VERSION ""

NS_ :

BS_:

BU_: WPC2 PSB SHVU_RR FCS vHS_B2 EMCU SLB GW_APSU GW_DLBCU RCM ARS CGW_CCU vDummy_HS_B GW_RLPSU ATS RLHV SGU PFSU GW_RRPSU ALBCU DSAU SWRC SHVU_FR RCS GW_DPSU BLTN_CAM SCM OHCL RWPC RRHV WPC HOD ASAU

BO_ 894 PDCex_01_200ms: 8 CGW_CCU
 SG_ PDCex_Crc1Val : 0|8@1+ (1,0) [0|0] "0" Vector__XXX
 SG_ PDCex_4thRLSBRMatSw : 10|1@1+ (1,0) [0|0] ""  ARS,FCS,WPC2
 SG_ PDCex_4thRRSBRMatSw : 11|1@1+ (1,0) [0|0] ""  ARS,FCS,WPC2
 SG_ PDCex_AlvCnt1Val : 12|4@1+ (1,0) [0|0] "0" Vector__XXX
 SG_ PDCex_4thRLSeatBeltSW : 16|1@1+ (1,0) [0|0] ""  ARS,FCS,WPC2
 SG_ PDCex_4thRCSeatBeltSW : 17|1@1+ (1,0) [0|0] ""  ARS,FCS,WPC2
 SG_ PDCex_4thRRSeatBeltSW : 18|1@1+ (1,0) [0|0] ""  ARS,FCS,WPC2
 SG_ PDCex_WirelessSBRWrngSta : 19|2@1+ (1,0) [0|0] "" Vector__XXX
 SG_ PDCex_FrtSunroofOpnSta : 21|2@1+ (1,0) [0|0] "" Vector__XXX
 SG_ PDCex_RrSunroofOpnSta : 23|2@1+ (1,0) [0|0] "" Vector__XXX
 SG_ PDCex_FuelDrOpenSta : 25|1@1+ (1,0) [0|0] ""  ARS,FCS,WPC2
 SG_ PDCex_TlgtUnLkSta : 26|2@1+ (1,0) [0|0] "" Vector__XXX
 SG_ PDCex_PSDPwrModeOffSwSta : 28|2@1+ (1,0) [0|0] ""  ARS,FCS,WPC2
 SG_ PDCex_StrBoxLidSta : 30|2@1+ (1,0) [0|0] "" Vector__XXX
 SG_ PDCex_StrBoxOutReleaseSwSta : 32|2@1+ (1,0) [0|0] "" Vector__XXX
 SG_ PDCex_DoorLock_LkOutSta : 34|2@1+ (1,0) [0|0] "" Vector__XXX
 SG_ SeatBeltSwSta_4thLft : 40|2@1+ (1,0) [0|0] "" Vector__XXX
 SG_ SeatBeltSwSta_4thCtr : 42|2@1+ (1,0) [0|0] "" Vector__XXX
 SG_ SeatBeltSwSta_4thRt : 44|2@1+ (1,0) [0|0] "" Vector__XXX
 SG_ PDCex_OptTyp : 8|2@1+ (1,0) [0|0] "" Vector__XXX

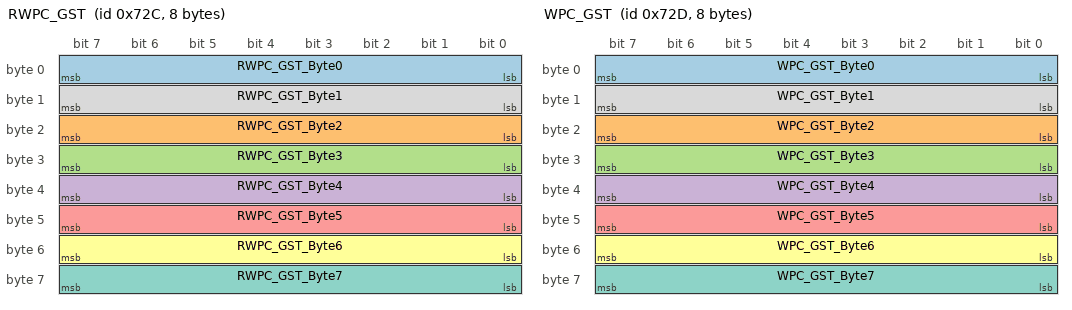
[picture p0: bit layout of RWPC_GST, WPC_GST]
BO_ 1836 RWPC_GST: 8 RWPC
 SG_ RWPC_GST_Byte0 : 0|8@1+ (1,0) [0|0] ""  CGW_CCU
 SG_ RWPC_GST_Byte2 : 16|8@1+ (1,0) [0|0] ""  CGW_CCU
 SG_ RWPC_GST_Byte3 : 24|8@1+ (1,0) [0|0] ""  CGW_CCU
 SG_ RWPC_GST_Byte4 : 32|8@1+ (1,0) [0|0] ""  CGW_CCU
 SG_ RWPC_GST_Byte5 : 40|8@1+ (1,0) [0|0] ""  CGW_CCU
 SG_ RWPC_GST_Byte6 : 48|8@1+ (1,0) [0|0] ""  CGW_CCU
 SG_ RWPC_GST_Byte7 : 56|8@1+ (1,0) [0|0] ""  CGW_CCU
 SG_ RWPC_GST_Byte1 : 8|8@1+ (1,0) [0|0] ""  CGW_CCU

BO_ 1837 WPC_GST: 8 WPC
 SG_ WPC_GST_Byte0 : 0|8@1+ (1,0) [0|0] ""  CGW_CCU
 SG_ WPC_GST_Byte2 : 16|8@1+ (1,0) [0|0] ""  CGW_CCU
 SG_ WPC_GST_Byte3 : 24|8@1+ (1,0) [0|0] ""  CGW_CCU
 SG_ WPC_GST_Byte4 : 32|8@1+ (1,0) [0|0] ""  CGW_CCU
 SG_ WPC_GST_Byte5 : 40|8@1+ (1,0) [0|0] ""  CGW_CCU
 SG_ WPC_GST_Byte6 : 48|8@1+ (1,0) [0|0] ""  CGW_CCU
 SG_ WPC_GST_Byte7 : 56|8@1+ (1,0) [0|0] ""  CGW_CCU
 SG_ WPC_GST_Byte1 : 8|8@1+ (1,0) [0|0] ""  CGW_CCU

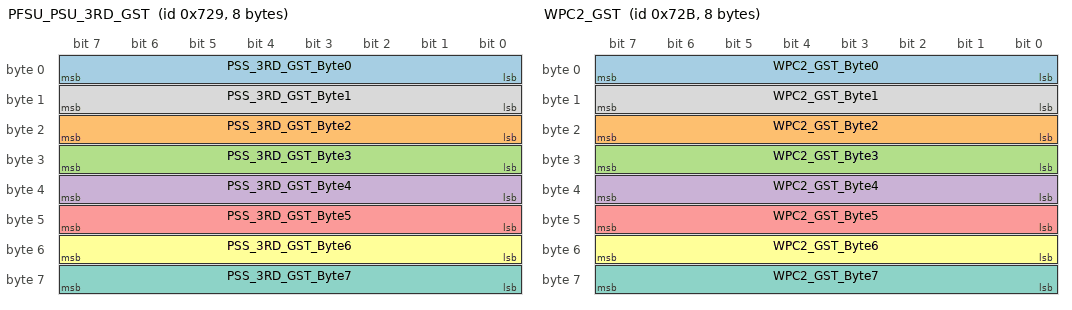
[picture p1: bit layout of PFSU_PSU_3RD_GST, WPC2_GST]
BO_ 1833 PFSU_PSU_3RD_GST: 8 PFSU
 SG_ PSS_3RD_GST_Byte0 : 0|8@1+ (1,0) [0|0] ""  CGW_CCU
 SG_ PSS_3RD_GST_Byte2 : 16|8@1+ (1,0) [0|0] ""  CGW_CCU
 SG_ PSS_3RD_GST_Byte3 : 24|8@1+ (1,0) [0|0] ""  CGW_CCU
 SG_ PSS_3RD_GST_Byte4 : 32|8@1+ (1,0) [0|0] ""  CGW_CCU
 SG_ PSS_3RD_GST_Byte5 : 40|8@1+ (1,0) [0|0] ""  CGW_CCU
 SG_ PSS_3RD_GST_Byte6 : 48|8@1+ (1,0) [0|0] ""  CGW_CCU
 SG_ PSS_3RD_GST_Byte7 : 56|8@1+ (1,0) [0|0] ""  CGW_CCU
 SG_ PSS_3RD_GST_Byte1 : 8|8@1+ (1,0) [0|0] ""  CGW_CCU

BO_ 1835 WPC2_GST: 8 WPC2
 SG_ WPC2_GST_Byte0 : 0|8@1+ (1,0) [0|0] ""  CGW_CCU
 SG_ WPC2_GST_Byte2 : 16|8@1+ (1,0) [0|0] ""  CGW_CCU
 SG_ WPC2_GST_Byte3 : 24|8@1+ (1,0) [0|0] ""  CGW_CCU
 SG_ WPC2_GST_Byte4 : 32|8@1+ (1,0) [0|0] ""  CGW_CCU
 SG_ WPC2_GST_Byte5 : 40|8@1+ (1,0) [0|0] ""  CGW_CCU
 SG_ WPC2_GST_Byte6 : 48|8@1+ (1,0) [0|0] ""  CGW_CCU
 SG_ WPC2_GST_Byte7 : 56|8@1+ (1,0) [0|0] ""  CGW_CCU
 SG_ WPC2_GST_Byte1 : 8|8@1+ (1,0) [0|0] ""  CGW_CCU

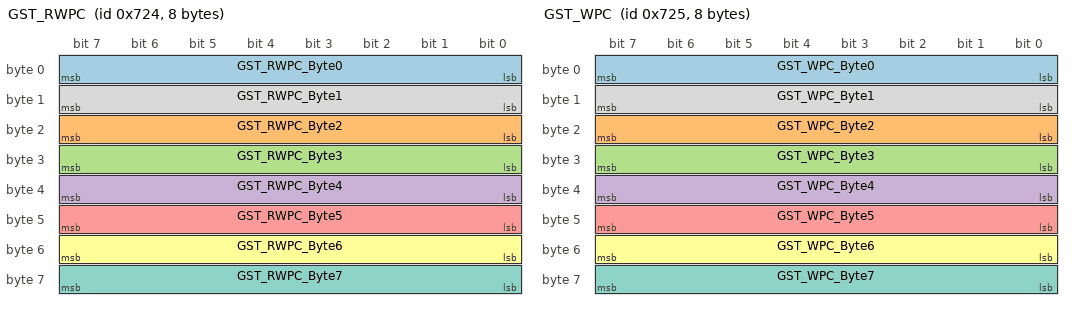
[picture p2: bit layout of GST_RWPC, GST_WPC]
BO_ 1828 GST_RWPC: 8 CGW_CCU
 SG_ GST_RWPC_Byte0 : 0|8@1+ (1,0) [0|0] ""  RWPC
 SG_ GST_RWPC_Byte2 : 16|8@1+ (1,0) [0|0] ""  RWPC
 SG_ GST_RWPC_Byte3 : 24|8@1+ (1,0) [0|0] ""  RWPC
 SG_ GST_RWPC_Byte4 : 32|8@1+ (1,0) [0|0] ""  RWPC
 SG_ GST_RWPC_Byte5 : 40|8@1+ (1,0) [0|0] ""  RWPC
 SG_ GST_RWPC_Byte6 : 48|8@1+ (1,0) [0|0] ""  RWPC
 SG_ GST_RWPC_Byte7 : 56|8@1+ (1,0) [0|0] ""  RWPC
 SG_ GST_RWPC_Byte1 : 8|8@1+ (1,0) [0|0] ""  RWPC

BO_ 1829 GST_WPC: 8 CGW_CCU
 SG_ GST_WPC_Byte0 : 0|8@1+ (1,0) [0|0] ""  WPC
 SG_ GST_WPC_Byte2 : 16|8@1+ (1,0) [0|0] ""  WPC
 SG_ GST_WPC_Byte3 : 24|8@1+ (1,0) [0|0] ""  WPC
 SG_ GST_WPC_Byte4 : 32|8@1+ (1,0) [0|0] ""  WPC
 SG_ GST_WPC_Byte5 : 40|8@1+ (1,0) [0|0] ""  WPC
 SG_ GST_WPC_Byte6 : 48|8@1+ (1,0) [0|0] ""  WPC
 SG_ GST_WPC_Byte7 : 56|8@1+ (1,0) [0|0] ""  WPC
 SG_ GST_WPC_Byte1 : 8|8@1+ (1,0) [0|0] ""  WPC

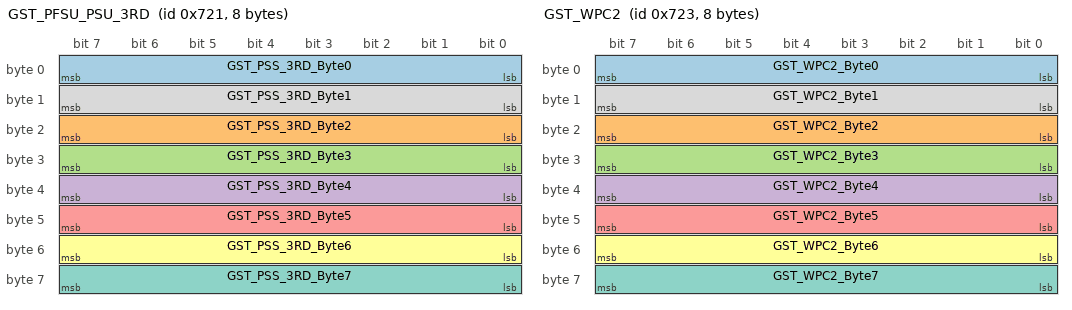
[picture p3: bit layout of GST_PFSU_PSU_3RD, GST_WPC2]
BO_ 1825 GST_PFSU_PSU_3RD: 8 CGW_CCU
 SG_ GST_PSS_3RD_Byte0 : 0|8@1+ (1,0) [0|0] ""  PFSU
 SG_ GST_PSS_3RD_Byte2 : 16|8@1+ (1,0) [0|0] ""  PFSU
 SG_ GST_PSS_3RD_Byte3 : 24|8@1+ (1,0) [0|0] ""  PFSU
 SG_ GST_PSS_3RD_Byte4 : 32|8@1+ (1,0) [0|0] ""  PFSU
 SG_ GST_PSS_3RD_Byte5 : 40|8@1+ (1,0) [0|0] ""  PFSU
 SG_ GST_PSS_3RD_Byte6 : 48|8@1+ (1,0) [0|0] ""  PFSU
 SG_ GST_PSS_3RD_Byte7 : 56|8@1+ (1,0) [0|0] ""  PFSU
 SG_ GST_PSS_3RD_Byte1 : 8|8@1+ (1,0) [0|0] ""  PFSU

BO_ 1827 GST_WPC2: 8 CGW_CCU
 SG_ GST_WPC2_Byte0 : 0|8@1+ (1,0) [0|0] ""  WPC2
 SG_ GST_WPC2_Byte2 : 16|8@1+ (1,0) [0|0] ""  WPC2
 SG_ GST_WPC2_Byte3 : 24|8@1+ (1,0) [0|0] ""  WPC2
 SG_ GST_WPC2_Byte4 : 32|8@1+ (1,0) [0|0] ""  WPC2
 SG_ GST_WPC2_Byte5 : 40|8@1+ (1,0) [0|0] ""  WPC2
 SG_ GST_WPC2_Byte6 : 48|8@1+ (1,0) [0|0] ""  WPC2
 SG_ GST_WPC2_Byte7 : 56|8@1+ (1,0) [0|0] ""  WPC2
 SG_ GST_WPC2_Byte1 : 8|8@1+ (1,0) [0|0] ""  WPC2

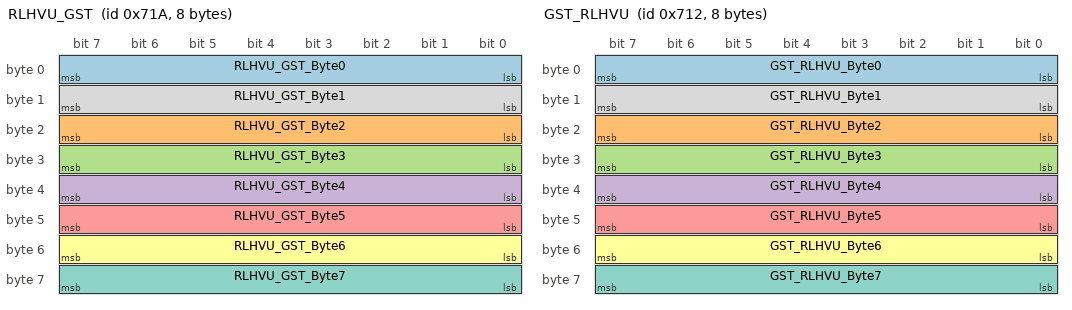
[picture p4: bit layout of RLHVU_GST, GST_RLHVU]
BO_ 1818 RLHVU_GST: 8 RLHV
 SG_ RLHVU_GST_Byte0 : 0|8@1+ (1,0) [0|0] ""  CGW_CCU
 SG_ RLHVU_GST_Byte2 : 16|8@1+ (1,0) [0|0] ""  CGW_CCU
 SG_ RLHVU_GST_Byte3 : 24|8@1+ (1,0) [0|0] ""  CGW_CCU
 SG_ RLHVU_GST_Byte4 : 32|8@1+ (1,0) [0|0] ""  CGW_CCU
 SG_ RLHVU_GST_Byte5 : 40|8@1+ (1,0) [0|0] ""  CGW_CCU
 SG_ RLHVU_GST_Byte6 : 48|8@1+ (1,0) [0|0] ""  CGW_CCU
 SG_ RLHVU_GST_Byte7 : 56|8@1+ (1,0) [0|0] ""  CGW_CCU
 SG_ RLHVU_GST_Byte1 : 8|8@1+ (1,0) [0|0] ""  CGW_CCU

BO_ 858 SBCM_AST_02_200ms: 8 CGW_CCU
 SG_ SBCM_AST_Crc2Val : 0|8@1+ (1,0) [0|0] "" Vector__XXX
 SG_ AST_CrashUnlockCmd : 10|1@1+ (1,0) [0|0] ""  BLTN_CAM
 SG_ SBCM_AST_AlvCnt2Val : 12|4@1+ (1,0) [0|0] "" Vector__XXX
 SG_ DoorLock_CtrlDrLkSwSta_SBCM : 16|2@1+ (1,0) [0|0] "" Vector__XXX
 SG_ DoorLock_CtrlDrUnLkSwSta_SBCM : 18|2@1+ (1,0) [0|0] "" Vector__XXX
 SG_ Warn_AsstDrSwSta_SBCM : 20|2@1+ (1,0) [0|0] ""  ALBCU,ATS,BLTN_CAM,GW_APSU,GW_RLPSU,GW_RRPSU,PSB,RWPC,WPC,WPC2
 SG_ DoorLock_AsstDrUnLkSta_SBCM : 22|2@1+ (1,0) [0|0] ""  ATS
 SG_ AST_SEAWarn_RH : 24|2@1+ (1,0) [0|0] "" Vector__XXX
 SG_ AST_SEAWarn_LH : 26|2@1+ (1,0) [0|0] "" Vector__XXX
 SG_ AST_SEWWarn_LH : 28|2@1+ (1,0) [0|0] "" Vector__XXX
 SG_ AST_SEWWarn_RH : 30|2@1+ (1,0) [0|0] "" Vector__XXX
 SG_ AST_MRActivationAlarm : 32|2@1+ (1,0) [0|0] "" Vector__XXX
 SG_ AST_ReleaseWarn : 34|2@1+ (1,0) [0|0] "" Vector__XXX
 SG_ USM_AstGhostDoorSta : 36|2@1+ (1,0) [0|0] "" Vector__XXX
 SG_ AST_SWFailAlarm : 38|2@1+ (1,0) [0|0] "" Vector__XXX
 SG_ DoorLock_PDSLkSwSta_AST : 40|2@1+ (1,0) [0|0] "" Vector__XXX
 SG_ PDS_TypeOption_AST : 42|2@1+ (1,0) [0|0] "" Vector__XXX
 SG_ AFCU_AutoWashModeSta_SBCM_AST : 56|3@1+ (1,0) [0|0] "" Vector__XXX
 SG_ CDM_AutoWashModeSta_SBCM_AST : 59|3@1+ (1,0) [0|0] "" Vector__XXX
 SG_ ASTDoorPushAlarm : 8|2@1+ (1,0) [0|0] "" Vector__XXX

BO_ 863 Ast_SHVU_03_200ms: 8 SHVU_FR
 SG_ Ast_SHVU_DTCdisplay : 0|8@1+ (1,0) [0|0] "" Vector__XXX
 SG_ Ast_SHVU_DiagMode : 8|2@1+ (1,0) [0|0] ""  vHS_B2

BO_ 862 SBCM_RL_01_200ms: 8 CGW_CCU
 SG_ SBCM_RL_Crc1Val : 0|8@1+ (1,0) [0|0] "" Vector__XXX
 SG_ RL_CrashUnlockCmd : 10|1@1+ (1,0) [0|0] ""  BLTN_CAM
 SG_ SBCM_RL_AlvCnt1Val : 12|4@1+ (1,0) [0|0] "" Vector__XXX
 SG_ Warn_RrLftDrSwSta_SBCM : 16|2@1+ (1,0) [0|0] ""  ATS,BLTN_CAM,GW_APSU,GW_RLPSU,GW_RRPSU,RWPC,WPC,WPC2
 SG_ DoorLock_RrLftDrUnLkSta_SBCM : 18|2@1+ (1,0) [0|0] ""  ATS
 SG_ RL_SEAActivated : 20|2@1+ (1,0) [0|0] "" Vector__XXX
 SG_ RL_SEAWarn : 22|2@1+ (1,0) [0|0] "" Vector__XXX
 SG_ RL_SEWWarn : 24|2@1+ (1,0) [0|0] "" Vector__XXX
 SG_ RL_ReleaseWarn : 26|2@1+ (1,0) [0|0] "" Vector__XXX
 SG_ RL_SWFailAlarm : 28|2@1+ (1,0) [0|0] "" Vector__XXX
 SG_ RL_ChildLock_ActnFlSta : 30|2@1+ (1,0) [0|0] "" Vector__XXX
 SG_ RL_MRActivationAlarm : 32|2@1+ (1,0) [0|0] "" Vector__XXX
 SG_ RL_ChildLock_Status : 34|2@1+ (1,0) [0|0] "" Vector__XXX
 SG_ USM_RLGhostDoorSta : 36|2@1+ (1,0) [0|0] "" Vector__XXX
 SG_ DoorLock_PDSLkSwSta_RL : 40|2@1+ (1,0) [0|0] "" Vector__XXX
 SG_ PDS_TypeOption_RL : 42|2@1+ (1,0) [0|0] "" Vector__XXX
 SG_ RLDoorPushAlarm : 8|2@1+ (1,0) [0|0] "" Vector__XXX

BO_ 1810 GST_RLHVU: 8 CGW_CCU
 SG_ GST_RLHVU_Byte0 : 0|8@1+ (1,0) [0|0] ""  RLHV
 SG_ GST_RLHVU_Byte2 : 16|8@1+ (1,0) [0|0] ""  RLHV
 SG_ GST_RLHVU_Byte3 : 24|8@1+ (1,0) [0|0] ""  RLHV
 SG_ GST_RLHVU_Byte4 : 32|8@1+ (1,0) [0|0] ""  RLHV
 SG_ GST_RLHVU_Byte5 : 40|8@1+ (1,0) [0|0] ""  RLHV
 SG_ GST_RLHVU_Byte6 : 48|8@1+ (1,0) [0|0] ""  RLHV
 SG_ GST_RLHVU_Byte7 : 56|8@1+ (1,0) [0|0] ""  RLHV
 SG_ GST_RLHVU_Byte1 : 8|8@1+ (1,0) [0|0] ""  RLHV

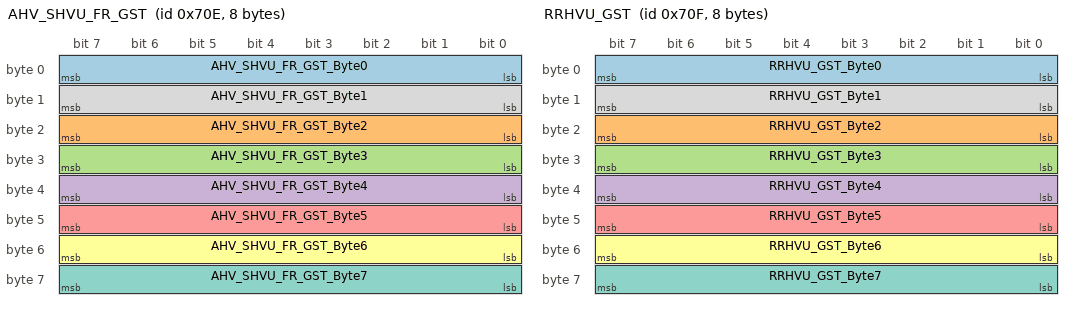
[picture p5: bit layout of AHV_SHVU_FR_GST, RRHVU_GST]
BO_ 1806 AHV_SHVU_FR_GST: 8 SHVU_FR
 SG_ AHV_SHVU_FR_GST_Byte0 : 0|8@1+ (1,0) [0|0] ""  CGW_CCU
 SG_ AHV_SHVU_FR_GST_Byte2 : 16|8@1+ (1,0) [0|0] ""  CGW_CCU
 SG_ AHV_SHVU_FR_GST_Byte3 : 24|8@1+ (1,0) [0|0] ""  CGW_CCU
 SG_ AHV_SHVU_FR_GST_Byte4 : 32|8@1+ (1,0) [0|0] ""  CGW_CCU
 SG_ AHV_SHVU_FR_GST_Byte5 : 40|8@1+ (1,0) [0|0] ""  CGW_CCU
 SG_ AHV_SHVU_FR_GST_Byte6 : 48|8@1+ (1,0) [0|0] ""  CGW_CCU
 SG_ AHV_SHVU_FR_GST_Byte7 : 56|8@1+ (1,0) [0|0] ""  CGW_CCU
 SG_ AHV_SHVU_FR_GST_Byte1 : 8|8@1+ (1,0) [0|0] ""  CGW_CCU

BO_ 1807 RRHVU_GST: 8 SHVU_RR
 SG_ RRHVU_GST_Byte0 : 0|8@1+ (1,0) [0|0] ""  CGW_CCU
 SG_ RRHVU_GST_Byte2 : 16|8@1+ (1,0) [0|0] ""  CGW_CCU
 SG_ RRHVU_GST_Byte3 : 24|8@1+ (1,0) [0|0] ""  CGW_CCU
 SG_ RRHVU_GST_Byte4 : 32|8@1+ (1,0) [0|0] ""  CGW_CCU
 SG_ RRHVU_GST_Byte5 : 40|8@1+ (1,0) [0|0] ""  CGW_CCU
 SG_ RRHVU_GST_Byte6 : 48|8@1+ (1,0) [0|0] ""  CGW_CCU
 SG_ RRHVU_GST_Byte7 : 56|8@1+ (1,0) [0|0] ""  CGW_CCU
 SG_ RRHVU_GST_Byte1 : 8|8@1+ (1,0) [0|0] ""  CGW_CCU

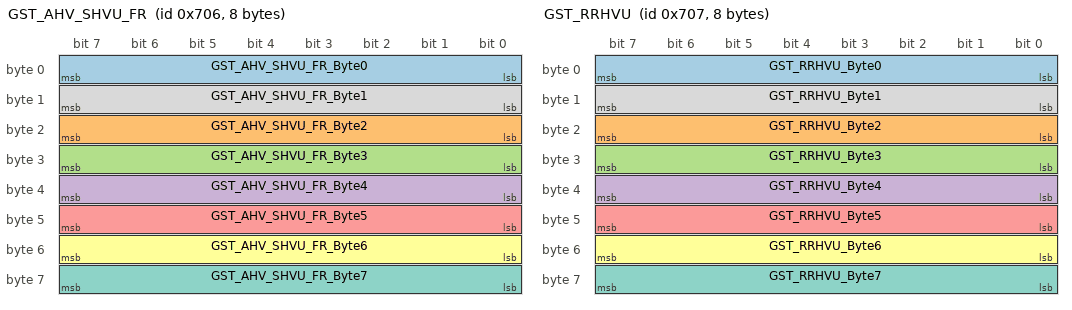
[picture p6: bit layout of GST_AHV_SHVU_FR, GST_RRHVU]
BO_ 1798 GST_AHV_SHVU_FR: 8 CGW_CCU
 SG_ GST_AHV_SHVU_FR_Byte0 : 0|8@1+ (1,0) [0|0] ""  SHVU_FR
 SG_ GST_AHV_SHVU_FR_Byte2 : 16|8@1+ (1,0) [0|0] ""  SHVU_FR
 SG_ GST_AHV_SHVU_FR_Byte3 : 24|8@1+ (1,0) [0|0] ""  SHVU_FR
 SG_ GST_AHV_SHVU_FR_Byte4 : 32|8@1+ (1,0) [0|0] ""  SHVU_FR
 SG_ GST_AHV_SHVU_FR_Byte5 : 40|8@1+ (1,0) [0|0] ""  SHVU_FR
 SG_ GST_AHV_SHVU_FR_Byte6 : 48|8@1+ (1,0) [0|0] ""  SHVU_FR
 SG_ GST_AHV_SHVU_FR_Byte7 : 56|8@1+ (1,0) [0|0] ""  SHVU_FR
 SG_ GST_AHV_SHVU_FR_Byte1 : 8|8@1+ (1,0) [0|0] ""  SHVU_FR

BO_ 1799 GST_RRHVU: 8 CGW_CCU
 SG_ GST_RRHVU_Byte0 : 0|8@1+ (1,0) [0|0] ""  RRHV,SHVU_RR
 SG_ GST_RRHVU_Byte2 : 16|8@1+ (1,0) [0|0] ""  RRHV,SHVU_RR
 SG_ GST_RRHVU_Byte3 : 24|8@1+ (1,0) [0|0] ""  RRHV,SHVU_RR
 SG_ GST_RRHVU_Byte4 : 32|8@1+ (1,0) [0|0] ""  RRHV,SHVU_RR
 SG_ GST_RRHVU_Byte5 : 40|8@1+ (1,0) [0|0] ""  RRHV,SHVU_RR
 SG_ GST_RRHVU_Byte6 : 48|8@1+ (1,0) [0|0] ""  RRHV,SHVU_RR
 SG_ GST_RRHVU_Byte7 : 56|8@1+ (1,0) [0|0] ""  RRHV,SHVU_RR
 SG_ GST_RRHVU_Byte1 : 8|8@1+ (1,0) [0|0] ""  RRHV,SHVU_RR

BO_ 847 Drv_SHVU_03_200ms: 8 SHVU_FR
 SG_ Drv_SHVU_DTCdisplay : 0|8@1+ (1,0) [0|0] "" Vector__XXX
 SG_ Drv_SHVU_DiagMode : 8|2@1+ (1,0) [0|0] "" Vector__XXX

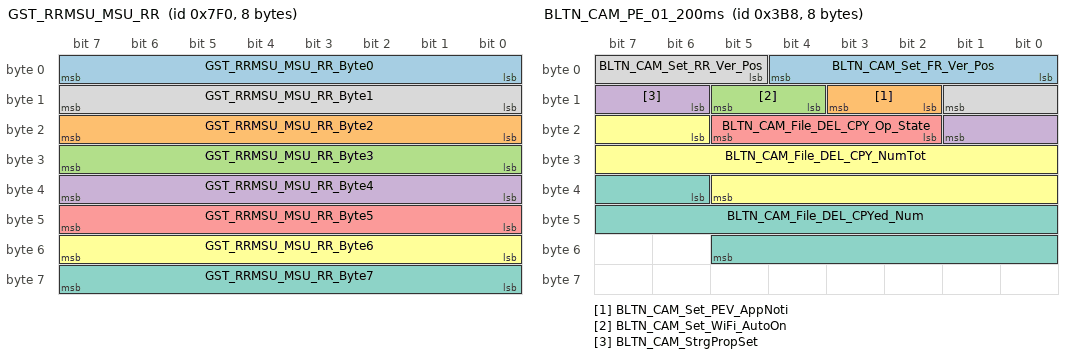
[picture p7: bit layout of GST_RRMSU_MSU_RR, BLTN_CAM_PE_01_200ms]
BO_ 2032 GST_RRMSU_MSU_RR: 8 CGW_CCU
 SG_ GST_RRMSU_MSU_RR_Byte0 : 0|8@1+ (1,0) [0|0] ""  GW_RRPSU
 SG_ GST_RRMSU_MSU_RR_Byte2 : 16|8@1+ (1,0) [0|0] ""  GW_RRPSU
 SG_ GST_RRMSU_MSU_RR_Byte3 : 24|8@1+ (1,0) [0|0] ""  GW_RRPSU
 SG_ GST_RRMSU_MSU_RR_Byte4 : 32|8@1+ (1,0) [0|0] ""  GW_RRPSU
 SG_ GST_RRMSU_MSU_RR_Byte5 : 40|8@1+ (1,0) [0|0] ""  GW_RRPSU
 SG_ GST_RRMSU_MSU_RR_Byte6 : 48|8@1+ (1,0) [0|0] ""  GW_RRPSU
 SG_ GST_RRMSU_MSU_RR_Byte7 : 56|8@1+ (1,0) [0|0] ""  GW_RRPSU
 SG_ GST_RRMSU_MSU_RR_Byte1 : 8|8@1+ (1,0) [0|0] ""  GW_RRPSU

BO_ 952 BLTN_CAM_PE_01_200ms: 8 BLTN_CAM
 SG_ BLTN_CAM_Set_FR_Ver_Pos : 0|5@1+ (1,0) [0|0] ""  CGW_CCU
 SG_ BLTN_CAM_Set_PEV_AppNoti : 10|2@1+ (1,0) [0|0] ""  CGW_CCU
 SG_ BLTN_CAM_Set_WiFi_AutoOn : 12|2@1+ (1,0) [0|0] ""  CGW_CCU
 SG_ BLTN_CAM_StrgPropSet : 14|4@1+ (1,0) [0|0] ""  CGW_CCU
 SG_ BLTN_CAM_File_DEL_CPY_Op_State : 18|4@1+ (1,0) [0|0] ""  CGW_CCU
 SG_ BLTN_CAM_File_DEL_CPY_NumTot : 22|16@1+ (1,0) [0|0] ""  CGW_CCU
 SG_ BLTN_CAM_File_DEL_CPYed_Num : 38|16@1+ (1,0) [0|0] ""  CGW_CCU
 SG_ BLTN_CAM_Set_RR_Ver_Pos : 5|5@1+ (1,0) [0|0] ""  CGW_CCU

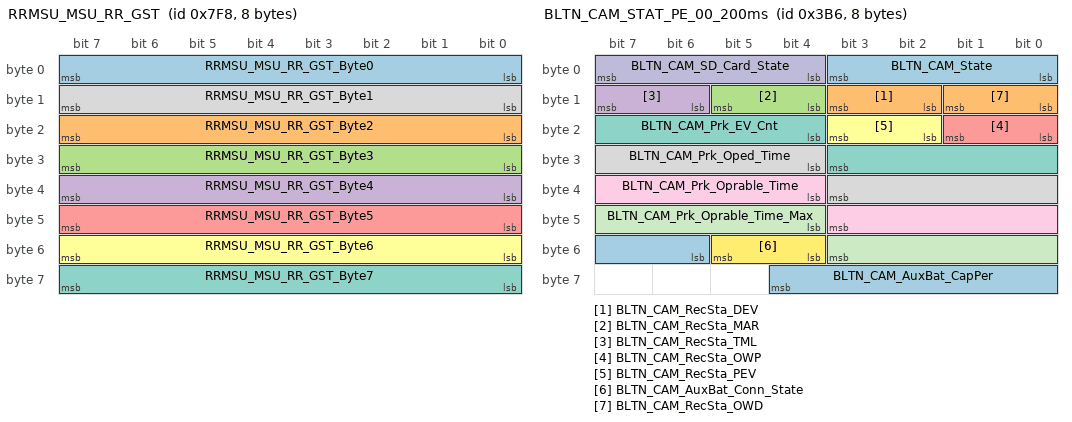
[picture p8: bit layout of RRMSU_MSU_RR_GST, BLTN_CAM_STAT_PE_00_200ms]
BO_ 2040 RRMSU_MSU_RR_GST: 8 GW_RRPSU
 SG_ RRMSU_MSU_RR_GST_Byte0 : 0|8@1+ (1,0) [0|0] ""  CGW_CCU
 SG_ RRMSU_MSU_RR_GST_Byte2 : 16|8@1+ (1,0) [0|0] ""  CGW_CCU
 SG_ RRMSU_MSU_RR_GST_Byte3 : 24|8@1+ (1,0) [0|0] ""  CGW_CCU
 SG_ RRMSU_MSU_RR_GST_Byte4 : 32|8@1+ (1,0) [0|0] ""  CGW_CCU
 SG_ RRMSU_MSU_RR_GST_Byte5 : 40|8@1+ (1,0) [0|0] ""  CGW_CCU
 SG_ RRMSU_MSU_RR_GST_Byte6 : 48|8@1+ (1,0) [0|0] ""  CGW_CCU
 SG_ RRMSU_MSU_RR_GST_Byte7 : 56|8@1+ (1,0) [0|0] ""  CGW_CCU
 SG_ RRMSU_MSU_RR_GST_Byte1 : 8|8@1+ (1,0) [0|0] ""  CGW_CCU

BO_ 950 BLTN_CAM_STAT_PE_00_200ms: 8 BLTN_CAM
 SG_ BLTN_CAM_State : 0|4@1+ (1,0) [0|0] ""  CGW_CCU
 SG_ BLTN_CAM_RecSta_DEV : 10|2@1+ (1,0) [0|0] ""  CGW_CCU
 SG_ BLTN_CAM_RecSta_MAR : 12|2@1+ (1,0) [0|0] ""  CGW_CCU
 SG_ BLTN_CAM_RecSta_TML : 14|2@1+ (1,0) [0|0] ""  CGW_CCU
 SG_ BLTN_CAM_RecSta_OWP : 16|2@1+ (1,0) [0|0] ""  CGW_CCU
 SG_ BLTN_CAM_RecSta_PEV : 18|2@1+ (1,0) [0|0] ""  CGW_CCU
 SG_ BLTN_CAM_Prk_EV_Cnt : 20|8@1+ (1,0) [0|0] ""  CGW_CCU
 SG_ BLTN_CAM_Prk_Oped_Time : 28|8@1+ (1,0) [0|0] "Hour"  CGW_CCU
 SG_ BLTN_CAM_Prk_Oprable_Time : 36|8@1+ (1,0) [0|0] "Hour"  CGW_CCU
 SG_ BLTN_CAM_SD_Card_State : 4|4@1+ (1,0) [0|0] ""  CGW_CCU
 SG_ BLTN_CAM_Prk_Oprable_Time_Max : 44|8@1+ (1,0) [0|0] "Hour"  CGW_CCU
 SG_ BLTN_CAM_AuxBat_Conn_State : 52|2@1+ (1,0) [0|0] ""  CGW_CCU
 SG_ BLTN_CAM_AuxBat_CapPer : 54|7@1+ (1,0) [0|0] "%"  CGW_CCU
 SG_ BLTN_CAM_RecSta_OWD : 8|2@1+ (1,0) [0|0] ""  CGW_CCU

BO_ 951 BLTN_CAM_PE_00_200ms: 8 BLTN_CAM
 SG_ BLTN_CAM_RecSet_OWD : 0|2@1+ (1,0) [0|0] ""  CGW_CCU
 SG_ BLTN_CAM_Set_Tim_Stm : 10|2@1+ (1,0) [0|0] ""  CGW_CCU
 SG_ BLTN_CAM_Set_Spd_Stm : 12|2@1+ (1,0) [0|0] ""  CGW_CCU
 SG_ BLTN_CAM_Set_Locatn_Stm : 14|2@1+ (1,0) [0|0] ""  CGW_CCU
 SG_ BLTN_CAM_Set_TrnSig_Stm : 16|2@1+ (1,0) [0|0] ""  CGW_CCU
 SG_ BLTN_CAM_Set_AclBrk_Stm : 18|2@1+ (1,0) [0|0] ""  CGW_CCU
 SG_ BLTN_CAM_RecSet_DEV : 2|2@1+ (1,0) [0|0] ""  CGW_CCU
 SG_ BLTN_CAM_Set_GearPos_Stm : 20|2@1+ (1,0) [0|0] ""  CGW_CCU
 SG_ BLTN_CAM_Set_EVSen_Stm : 22|2@1+ (1,0) [0|0] ""  CGW_CCU
 SG_ BLTN_CAM_Set_StrAngl_Stm : 24|2@1+ (1,0) [0|0] ""  CGW_CCU
 SG_ BLTN_CAM_Set_EV_RecMaxTime : 26|2@1+ (1,0) [0|0] ""  CGW_CCU
 SG_ BLTN_CAM_Set_PrkTime : 30|8@1+ (1,0) [0|0] "Hour"  CGW_CCU
 SG_ BLTN_CAM_Set_EV_BfrTime : 38|5@1+ (1,0) [0|0] ""  CGW_CCU
 SG_ BLTN_CAM_RecSet_OWP : 4|2@1+ (1,0) [0|0] ""  CGW_CCU
 SG_ BLTN_CAM_Set_EV_AftTime : 43|5@1+ (1,0) [0|0] ""  CGW_CCU
 SG_ BLTN_CAM_Set_Drv_TML_Int : 48|4@1+ (1,0) [0|0] ""  CGW_CCU
 SG_ BLTN_CAM_SenSet_DEV : 52|4@1+ (1,0) [0|0] ""  CGW_CCU
 SG_ BLTN_CAM_SenSet_PEV : 56|4@1+ (1,0) [0|0] ""  CGW_CCU
 SG_ BLTN_CAM_RecSet_PEV : 6|2@1+ (1,0) [0|0] ""  CGW_CCU
 SG_ BLTN_CAM_AudRec_Set : 8|2@1+ (1,0) [0|0] ""  CGW_CCU

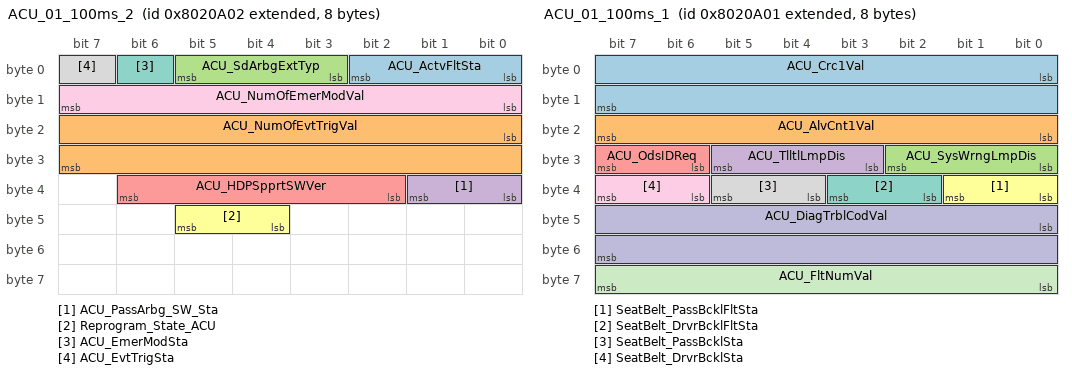
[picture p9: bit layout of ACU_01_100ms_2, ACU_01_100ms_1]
BO_ 2281835010 ACU_01_100ms_2: 8 CGW_CCU
 SG_ ACU_ActvFltSta : 0|3@1+ (1,0) [0|0] "" Vector__XXX
 SG_ ACU_NumOfEvtTrigVal : 16|16@1+ (1,0) [0|0] "" Vector__XXX
 SG_ ACU_SdArbgExtTyp : 3|3@1+ (1,0) [0|0] "" Vector__XXX
 SG_ ACU_PassArbg_SW_Sta : 32|2@1+ (1,0) [0|0] "" Vector__XXX
 SG_ ACU_HDPSpprtSWVer : 34|5@1+ (1,0) [0|0] "" Vector__XXX
 SG_ Reprogram_State_ACU : 44|2@1+ (1,0) [0|0] "" Vector__XXX
 SG_ ACU_EmerModSta : 6|1@1+ (1,0) [0|0] "" Vector__XXX
 SG_ ACU_EvtTrigSta : 7|1@1+ (1,0) [0|0] "" Vector__XXX
 SG_ ACU_NumOfEmerModVal : 8|8@1+ (1,0) [0|0] "" Vector__XXX

BO_ 2281835009 ACU_01_100ms_1: 8 CGW_CCU
 SG_ ACU_Crc1Val : 0|16@1+ (1,0) [0|0] ""  OHCL
 SG_ ACU_AlvCnt1Val : 16|8@1+ (1,0) [0|0] ""  OHCL
 SG_ ACU_SysWrngLmpDis : 24|3@1+ (1,0) [0|0] "" Vector__XXX
 SG_ ACU_TlltlLmpDis : 27|3@1+ (1,0) [0|0] ""  OHCL
 SG_ ACU_OdsIDReq : 30|2@1+ (1,0) [0|0] "" Vector__XXX
 SG_ SeatBelt_PassBcklFltSta : 32|2@1+ (1,0) [0|0] ""  PSB
 SG_ SeatBelt_DrvrBcklFltSta : 34|2@1+ (1,0) [0|0] ""  PSB
 SG_ SeatBelt_PassBcklSta : 36|2@1+ (1,0) [0|0] ""  ATS,GW_APSU,GW_RLPSU,GW_RRPSU,PSB
 SG_ SeatBelt_DrvrBcklSta : 38|2@1+ (1,0) [0|0] ""  PSB
 SG_ ACU_DiagTrblCodVal : 40|16@1+ (1,0) [0|0] "" Vector__XXX
 SG_ ACU_FltNumVal : 56|8@1+ (1,0) [0|0] "" Vector__XXX

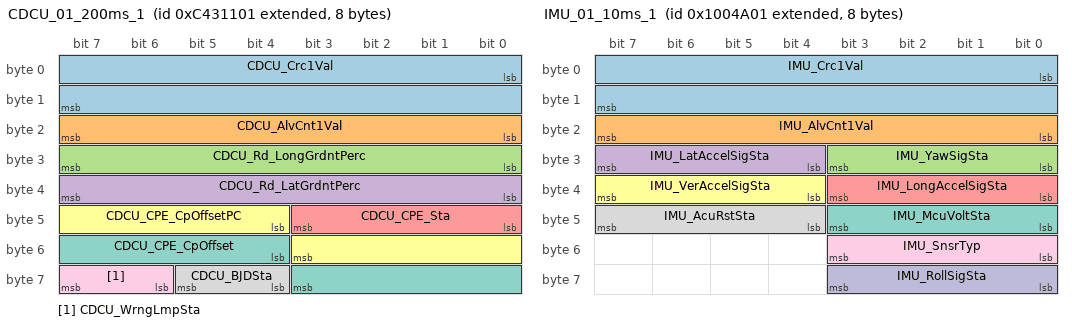
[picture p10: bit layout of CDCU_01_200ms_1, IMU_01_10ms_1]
BO_ 2353205505 CDCU_01_200ms_1: 8 CGW_CCU
 SG_ CDCU_Crc1Val : 0|16@1+ (1,0) [0|0] "" Vector__XXX
 SG_ CDCU_AlvCnt1Val : 16|8@1+ (1,0) [0|0] "" Vector__XXX
 SG_ CDCU_Rd_LongGrdntPerc : 24|8@1+ (1,-128) [-100|100] "%"  EMCU
 SG_ CDCU_Rd_LatGrdntPerc : 32|8@1+ (1,-128) [-100|100] "%"  EMCU
 SG_ CDCU_CPE_Sta : 40|4@1+ (1,0) [0|0] "" Vector__XXX
 SG_ CDCU_CPE_CpOffsetPC : 44|8@1+ (0.392157,-50) [-50|49.60784] "%" Vector__XXX
 SG_ CDCU_CPE_CpOffset : 52|8@1+ (0.392157,-50) [-50|49.60784] "Nm/bar" Vector__XXX
 SG_ CDCU_BJDSta : 60|2@1+ (1,0) [0|0] "" Vector__XXX
 SG_ CDCU_WrngLmpSta : 62|2@1+ (1,0) [0|0] "" Vector__XXX

BO_ 2164279809 IMU_01_10ms_1: 8 CGW_CCU
 SG_ IMU_Crc1Val : 0|16@1+ (1,0) [0|0] "" Vector__XXX
 SG_ IMU_AlvCnt1Val : 16|8@1+ (1,0) [0|0] "" Vector__XXX
 SG_ IMU_YawSigSta : 24|4@1+ (1,0) [0|0] ""  PSB
 SG_ IMU_LatAccelSigSta : 28|4@1+ (1,0) [0|0] ""  PSB
 SG_ IMU_LongAccelSigSta : 32|4@1+ (1,0) [0|0] ""  PSB
 SG_ IMU_VerAccelSigSta : 36|4@1+ (1,0) [0|0] "" Vector__XXX
 SG_ IMU_McuVoltSta : 40|4@1+ (1,0) [0|0] "" Vector__XXX
 SG_ IMU_AcuRstSta : 44|4@1+ (1,0) [0|0] "" Vector__XXX
 SG_ IMU_SnsrTyp : 48|4@1+ (1,0) [0|0] "" Vector__XXX
 SG_ IMU_RollSigSta : 56|4@1+ (1,0) [0|0] "" Vector__XXX

BO_ 2164279811 IMU_01_10ms_3: 8 CGW_CCU
 SG_ IMU_SeralNumVal : 0|48@1+ (1,0) [0|0] "" Vector__XXX

BO_ 2353205506 CDCU_01_200ms_2: 8 CGW_CCU
 SG_ CBCR_SocConsumptionReq : 2|2@1+ (1,0) [0|0] "" Vector__XXX
 SG_ CBCR_CluDispMsgSta : 4|3@1+ (1,0) [0|0] "" Vector__XXX

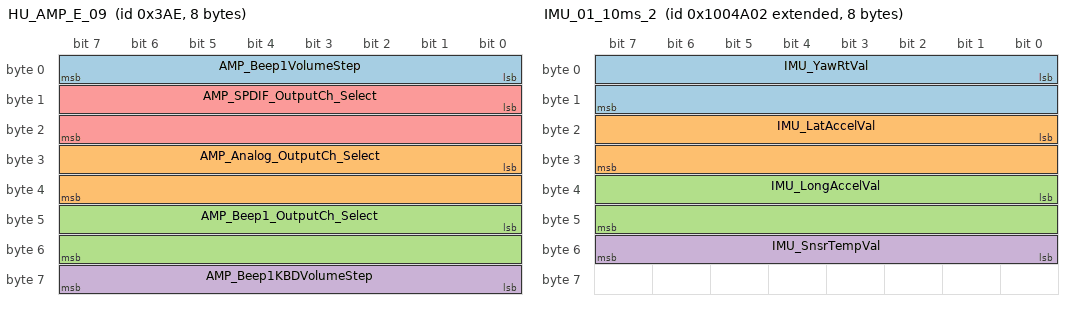
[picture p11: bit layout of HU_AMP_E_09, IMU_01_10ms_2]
BO_ 942 HU_AMP_E_09: 8 CGW_CCU
 SG_ AMP_Beep1VolumeStep : 0|8@1+ (1,0) [0|0] ""  ATS
 SG_ AMP_Analog_OutputCh_Select : 24|16@1+ (1,0) [0|0] "" Vector__XXX
 SG_ AMP_Beep1_OutputCh_Select : 40|16@1+ (1,0) [0|0] "" Vector__XXX
 SG_ AMP_Beep1KBDVolumeStep : 56|8@1+ (1,0) [0|0] "" Vector__XXX
 SG_ AMP_SPDIF_OutputCh_Select : 8|16@1+ (1,0) [0|0] "" Vector__XXX

BO_ 2164279810 IMU_01_10ms_2: 8 CGW_CCU
 SG_ IMU_YawRtVal : 0|16@1+ (0.005,-163.84) [0|0] "¢ª/s"  PSB
 SG_ IMU_LatAccelVal : 16|16@1+ (0.000127465,-4.17677312) [0|0] "g"  PSB
 SG_ IMU_LongAccelVal : 32|16@1+ (0.000127465,-4.17677312) [0|0] "g"  PSB
 SG_ IMU_SnsrTempVal : 48|8@1+ (1,-68) [0|0] "¡É" Vector__XXX

BO_ 2164279812 IMU_01_10ms_4: 8 CGW_CCU
 SG_ IMU_RollRtVal : 0|16@1+ (0.005,-163.84) [0|0] "¢ª/s" Vector__XXX
 SG_ IMU_VerAccelVal : 16|16@1+ (0.000127465,-4.17677312) [0|0] "g" Vector__XXX

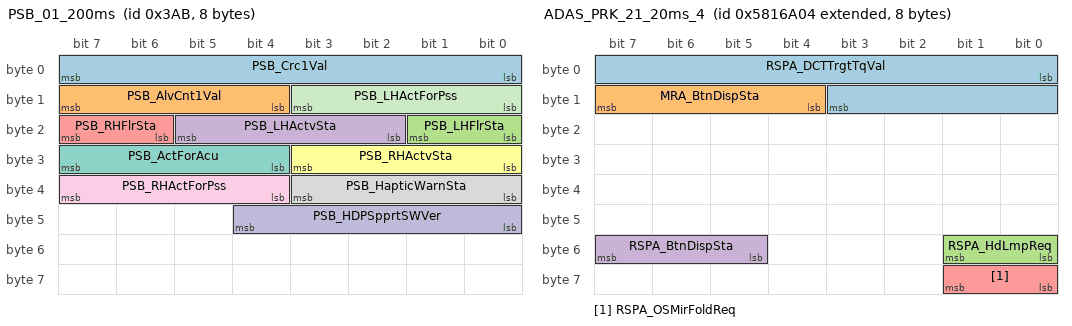
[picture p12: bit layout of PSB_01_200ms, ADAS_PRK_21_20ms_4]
BO_ 939 PSB_01_200ms: 8 PSB
 SG_ PSB_Crc1Val : 0|8@1+ (1,0) [0|0] ""  CGW_CCU
 SG_ PSB_AlvCnt1Val : 12|4@1+ (1,0) [0|0] ""  CGW_CCU
 SG_ PSB_LHFlrSta : 16|2@1+ (1,0) [0|0] ""  CGW_CCU
 SG_ PSB_LHActvSta : 18|4@1+ (1,0) [0|0] ""  CGW_CCU
 SG_ PSB_RHFlrSta : 22|2@1+ (1,0) [0|0] ""  CGW_CCU
 SG_ PSB_RHActvSta : 24|4@1+ (1,0) [0|0] ""  CGW_CCU,GW_APSU
 SG_ PSB_ActForAcu : 28|4@1+ (1,0) [0|0] ""  CGW_CCU
 SG_ PSB_HapticWarnSta : 32|4@1+ (1,0) [0|0] ""  CGW_CCU
 SG_ PSB_RHActForPss : 36|4@1+ (1,0) [0|0] ""  GW_APSU,GW_RLPSU,GW_RRPSU
 SG_ PSB_HDPSpprtSWVer : 40|5@1+ (1,0) [0|0] ""  CGW_CCU
 SG_ PSB_LHActForPss : 8|4@1+ (1,0) [0|0] ""  GW_RLPSU,GW_RRPSU

BO_ 935 SCM_02_00ms: 8 SCM
 SG_ SCM_AnySwOnEv : 24|1@1+ (1,0) [0|0] ""  CGW_CCU

BO_ 2239851012 ADAS_PRK_21_20ms_4: 8 CGW_CCU
 SG_ RSPA_DCTTrgtTqVal : 0|12@1- (1,0) [0|0] "Nm" Vector__XXX
 SG_ MRA_BtnDispSta : 12|4@1+ (1,0) [0|0] "" Vector__XXX
 SG_ RSPA_HdLmpReq : 48|2@1+ (1,0) [0|0] "" Vector__XXX
 SG_ RSPA_BtnDispSta : 53|3@1+ (1,0) [0|0] "" Vector__XXX
 SG_ RSPA_OSMirFoldReq : 56|2@1+ (1,0) [0|0] "" Vector__XXX

BO_TX_BU_ 863 : SHVU_FR,GW_APSU;
BO_TX_BU_ 1807 : SHVU_RR,RRHV;
CM_ BO_ 894 "[PE] Periodic and On Event";
CM_ SG_ 894 PDCex_Crc1Val "PDCex_CyclicRedundancyCheck1Value";
CM_ SG_ 894 PDCex_AlvCnt1Val "PDCex_AliveCounter1Value";
CM_ SG_ 894 PDCex_DoorLock_LkOutSta "DoorLock_LockOutputStatus";
CM_ BO_ 1836 "[TP] Transport Protocol";
CM_ BO_ 1837 "[TP] Transport Protocol";
CM_ BO_ 1833 "[TP] Transport Protocol";
CM_ BO_ 1835 "[TP] Transport Protocol";
CM_ BO_ 1828 "[TP] Transport Protocol";
CM_ BO_ 1829 "[TP] Transport Protocol";
CM_ BO_ 1825 "[TP] Transport Protocol";
CM_ BO_ 1827 "[TP] Transport Protocol";
CM_ BO_ 1818 "[TP] Transport Protocol";
CM_ BO_ 858 "[PE] Periodic and On Event";
CM_ SG_ 858 SBCM_AST_Crc2Val "SBCM_AST_CyclicRedundancyCheck2Value";
CM_ SG_ 858 AST_CrashUnlockCmd "AssistCrashUnlockCommand";
CM_ SG_ 858 SBCM_AST_AlvCnt2Val "SBCM_AST_AliveCounter2Value";
CM_ SG_ 858 DoorLock_CtrlDrLkSwSta_SBCM "DoorLock_CentralDoorLockAssistSwitchStatus";
CM_ SG_ 858 DoorLock_CtrlDrUnLkSwSta_SBCM "DoorLock_CentralDoorUnLockAssistSwitchStatus";
CM_ SG_ 858 Warn_AsstDrSwSta_SBCM "Warn_AssistDoorSwitchStatus ##2G## -  - C_AstDrSw,CF_Gway_AstDrSw,Warn_AsstDrSwSta";
CM_ SG_ 858 DoorLock_AsstDrUnLkSta_SBCM "DoorLock_AssistDoorUnLockStatus ##2G## -  - C_AstUnlockState,DoorLock_AsstDrUnLkSta";
CM_ SG_ 858 AST_SEAWarn_RH "Assist SEA Warning (LHD)";
CM_ BO_ 863 "[PE] Periodic and On Event";
CM_ BO_ 862 "[PE] Periodic and On Event";
CM_ SG_ 862 SBCM_RL_Crc1Val "SBCM_RL_CyclicRedundancyCheck1Value";
CM_ SG_ 862 RL_CrashUnlockCmd "Rear Lefr Crash Unlock Command";
CM_ SG_ 862 SBCM_RL_AlvCnt1Val "SBCM_RL_AliveCounter1Value";
CM_ SG_ 862 Warn_RrLftDrSwSta_SBCM "Warn_RearLeftDoorSwitchStatus ##2G## -  - C_RLDrSw,CF_Gway_RLDrSw,Warn_RrLftDrSwSta";
CM_ SG_ 862 DoorLock_RrLftDrUnLkSta_SBCM "DoorLock_RearLeftDoorUnLockStatus ##2G## -  - C_RLUnlockState,DoorLock_RrLftDrUnLkSta";
CM_ SG_ 862 RL_SEAActivated "RearLeftSEAActivated";
CM_ SG_ 862 RL_SEAWarn "Rear Left SEA Warning";
CM_ BO_ 1810 "[TP] Transport Protocol";
CM_ BO_ 1806 "[TP] Transport Protocol";
CM_ BO_ 1807 "[TP] Transport Protocol";
CM_ BO_ 1798 "[TP] Transport Protocol";
CM_ BO_ 1799 "[TP] Transport Protocol";
CM_ BO_ 847 "[PE] Periodic and On Event";
CM_ BO_ 2032 "[TP] Transport Protocol";
CM_ BO_ 952 "[PE] Periodic and On Event";
CM_ SG_ 952 BLTN_CAM_Set_FR_Ver_Pos "Front Camera Vertical position setting value.";
CM_ SG_ 952 BLTN_CAM_Set_PEV_AppNoti "Parked Event notification to Connectivity Phone App. On/Off";
CM_ SG_ 952 BLTN_CAM_Set_WiFi_AutoOn "Wifi On/Off User setting";
CM_ SG_ 952 BLTN_CAM_StrgPropSet "Propotion of built-in Cam SD card Propotion set of the Recording Categories";
CM_ SG_ 952 BLTN_CAM_File_DEL_CPY_Op_State "Bulil in Cam Fily copy and delete operating state.";
CM_ SG_ 952 BLTN_CAM_File_DEL_CPY_NumTot "Number of Copied or Deleted files.";
CM_ SG_ 952 BLTN_CAM_File_DEL_CPYed_Num "Total number of the copy or delete file.";
CM_ SG_ 952 BLTN_CAM_Set_RR_Ver_Pos "Rear Camera Vertical position setting value.";
CM_ BO_ 2040 "[TP] Transport Protocol";
CM_ BO_ 950 "[PE] Periodic and On Event";
CM_ SG_ 950 BLTN_CAM_State "This Signal is for cluster warning popup.";
CM_ SG_ 950 BLTN_CAM_RecSta_DEV "This Signal inform recording status of Driving Event.";
CM_ SG_ 950 BLTN_CAM_RecSta_MAR "This Signal inform recording status of Manual Recording.";
CM_ SG_ 950 BLTN_CAM_RecSta_TML "This Signal inform recording status of Time-lapse.";
CM_ SG_ 950 BLTN_CAM_RecSta_OWP "This Signal inform recording status of On While Parked.";
CM_ SG_ 950 BLTN_CAM_RecSta_PEV "This Signal inform recording status of Parked Event.";
CM_ SG_ 950 BLTN_CAM_Prk_EV_Cnt "The count number of a parked Event.";
CM_ SG_ 950 BLTN_CAM_Prk_Oped_Time "The Parked Opreated time ingormation";
CM_ SG_ 950 BLTN_CAM_Prk_Oprable_Time "The hours of Park Mode Operatable, the time is limited by user max oper. Set.";
CM_ SG_ 950 BLTN_CAM_SD_Card_State "This Signal is for SD card Status in Built-in App menu and CCS Phone App.";
CM_ SG_ 950 BLTN_CAM_Prk_Oprable_Time_Max "The hours of Park Mode Operatable, the time has no limit.";
CM_ SG_ 950 BLTN_CAM_AuxBat_Conn_State "0x0 : Default / 0x1 : Auxiliary Battery is connected.(P-LBM or B-LBM) / 0x2 : Auxiliary Battery Is not connected. - Auxiliary Battery applicable on this vehicle model / 0x3:  Auxiliary Battery is not connected. ? Auxiliary Battery not applicable on this vehicle model";
CM_ SG_ 950 BLTN_CAM_AuxBat_CapPer "The percentage of Aux. Bat.";
CM_ SG_ 950 BLTN_CAM_RecSta_OWD "This Signal inform recording status of On While Driving.";
CM_ BO_ 951 "[PE] Periodic and On Event";
CM_ SG_ 951 BLTN_CAM_RecSet_OWD "Record On/Off Set of On While Driving";
CM_ SG_ 951 BLTN_CAM_Set_Tim_Stm "Record Set of Date and Time Stamp";
CM_ SG_ 951 BLTN_CAM_Set_Spd_Stm "Record Set of Speed Stamp";
CM_ SG_ 951 BLTN_CAM_Set_Locatn_Stm "Record Set of Location Stamp";
CM_ SG_ 951 BLTN_CAM_Set_TrnSig_Stm "Record Set of Turn Signal Stamp";
CM_ SG_ 951 BLTN_CAM_Set_AclBrk_Stm "Record Set of Accelerator Brake Stamp";
CM_ SG_ 951 BLTN_CAM_RecSet_DEV "Record On/Off Set of Driving Event";
CM_ SG_ 951 BLTN_CAM_Set_GearPos_Stm "Record Set of Gear Position Stamp";
CM_ SG_ 951 BLTN_CAM_Set_EVSen_Stm "Record Set of Event Sensitivity Stamp";
CM_ SG_ 951 BLTN_CAM_Set_StrAngl_Stm "Record Set of Steering Angle Stamp";
CM_ SG_ 951 BLTN_CAM_Set_EV_RecMaxTime "Record Set of  EV Parking Rec Max Time On/Off";
CM_ SG_ 951 BLTN_CAM_Set_PrkTime "Parking Operation Setting Time, Resolution : hr";
CM_ SG_ 951 BLTN_CAM_Set_EV_BfrTime "Driving Event Time Setting - Before, Resolution : sec";
CM_ SG_ 951 BLTN_CAM_RecSet_OWP "Record On/Off Set of On While Parked, 0x0(Default) : Parking recording function not supported";
CM_ SG_ 951 BLTN_CAM_Set_EV_AftTime "Driving Event Time Setting - After, Resolution : sec";
CM_ SG_ 951 BLTN_CAM_Set_Drv_TML_Int "Record Set of Time-lapse Interval, Resolution : sec";
CM_ SG_ 951 BLTN_CAM_SenSet_DEV "Set of Event  Detection Sensitivity of Driving Mode";
CM_ SG_ 951 BLTN_CAM_SenSet_PEV "Set of Event  Detection Sensitivity of Parking Mode";
CM_ SG_ 951 BLTN_CAM_RecSet_PEV "Record Set of Parked Event, 0x0(Default) : Parking recording function not supported";
CM_ SG_ 951 BLTN_CAM_AudRec_Set "Audio Record On/Off Set";
CM_ BO_ 2281835010 "[P] Periodic";
CM_ SG_ 2281835010 ACU_ActvFltSta "ACU_ActiveFaultStatus ##2G##ACU - ACU11 - CF_Acu_FltStat";
CM_ SG_ 2281835010 ACU_NumOfEvtTrigVal "EDR trigger counter";
CM_ SG_ 2281835010 ACU_SdArbgExtTyp "ACU_SideAirbagExistanceType ##2G##ACU - ACU11 - CF_Acu_ExtOfSab";
CM_ SG_ 2281835010 ACU_PassArbg_SW_Sta "PAB ON_OFF S/W state for USM";
CM_ SG_ 2281835010 ACU_HDPSpprtSWVer "Software version information of signals related to HDP cooperative control";
CM_ SG_ 2281835010 Reprogram_State_ACU "Reprogram status of functional safety controller";
CM_ SG_ 2281835010 ACU_EvtTrigSta "EDR triggered information bit";
CM_ SG_ 2281835010 ACU_NumOfEmerModVal "Emergency mode counter";
CM_ BO_ 2281835009 "[P] Periodic";
CM_ SG_ 2281835009 ACU_Crc1Val "ACU_CyclicRedundancyCheck1Value";
CM_ SG_ 2281835009 ACU_AlvCnt1Val "ACU_AliveCounter1Value";
CM_ SG_ 2281835009 ACU_SysWrngLmpDis "ACU_SystemWarningLampDisplay ##2G##ACU - ACU14 - CF_SWL_Ind";
CM_ SG_ 2281835009 ACU_TlltlLmpDis "PAB ON OFF Lamp indication bit. 00X : PAB OFF LAMP, 0YO : PAB ON LAMP";
CM_ SG_ 2281835009 ACU_OdsIDReq "ACU_OdsIDRequest ##2G##ACU - ACU11 - CF_Ods_IDRcv";
CM_ SG_ 2281835009 SeatBelt_PassBcklFltSta "SeatBelt_PassengerBuckleFaultStatus ##2G##ACU - ACU11 - CF_PasBkl_FltStat";
CM_ SG_ 2281835009 SeatBelt_DrvrBcklFltSta "SeatBelt_DriverBuckleFaultStatus ##2G##ACU - ACU11 - CF_DriBkl_FltStat";
CM_ SG_ 2281835009 SeatBelt_PassBcklSta "SeatBelt_PassengerBuckleStatus ##2G##ACU - ACU11 - CF_PasBkl_Stat";
CM_ SG_ 2281835009 SeatBelt_DrvrBcklSta "SeatBelt_DriverBuckleStatus ##2G##ACU - ACU11 - CF_DriBkl_Stat";
CM_ SG_ 2281835009 ACU_DiagTrblCodVal "ACU_DiagnosticTroubleCodeValue ##2G##ACU - ACU11 - CF_Acu_Dtc";
CM_ SG_ 2281835009 ACU_FltNumVal "ACU_FaultNumberValue ##2G##ACU - ACU11 - CF_Acu_NumOfFlt";
CM_ BO_ 2353205505 "[P] Periodic";
CM_ SG_ 2353205505 CDCU_Crc1Val "CDCU_CyclicRedundancyCheck1Value";
CM_ SG_ 2353205505 CDCU_AlvCnt1Val "CDCU_AliveCounter1Value";
CM_ SG_ 2353205505 CDCU_Rd_LongGrdntPerc "CDCU_LongitudinalGradientPercent";
CM_ SG_ 2353205505 CDCU_Rd_LatGrdntPerc "CDCU_LateralGradientPercent";
CM_ SG_ 2353205505 CDCU_CPE_Sta "CPE status";
CM_ SG_ 2353205505 CDCU_CPE_CpOffsetPC "Brake pressure offset Request value (PC)";
CM_ SG_ 2353205505 CDCU_CPE_CpOffset "Brake factor offset Request value (Nm/bar)";
CM_ SG_ 2353205505 CDCU_BJDSta "Brake Judder Detection";
CM_ SG_ 2353205505 CDCU_WrngLmpSta "CDCU Warning Lamp Status";
CM_ BO_ 2164279809 "[P] Periodic";
CM_ SG_ 2164279809 IMU_Crc1Val "IMU_CyclicRedundancyCheck1Value";
CM_ SG_ 2164279809 IMU_AlvCnt1Val "IMU_AliveCounter1Value";
CM_ SG_ 2164279809 IMU_YawSigSta "IMU_YawSignalStatus ##2G##YRS - YRS11 - CF_Yrs_YrStat";
CM_ SG_ 2164279809 IMU_LatAccelSigSta "IMU_LateralAccelerationSignalStatus ##2G##YRS - YRS11 - CF_Yrs_LatAcStat";
CM_ SG_ 2164279809 IMU_LongAccelSigSta "IMU_LongitudinalAccelerationSignalStatus ##2G##YRS - YRS12 - CF_Yrs_LongAcStat";
CM_ SG_ 2164279809 IMU_VerAccelSigSta "IMU_Vertial Acceleration Signal Status";
CM_ SG_ 2164279809 IMU_McuVoltSta "IMU_McuVoltageStatus ##2G##YRS - YRS11 - CF_Yrs_MCUStat";
CM_ SG_ 2164279809 IMU_AcuRstSta "IMU_AcuResetStatus ##2G##YRS - YRS12 - CF_IMU_ResetStat";
CM_ SG_ 2164279809 IMU_SnsrTyp "IMU SensorType (Axis information)##2G##YRS - YRS12 - CF_Yrs_Type";
CM_ SG_ 2164279809 IMU_RollSigSta "IMU Rollrate signal status";
CM_ BO_ 2164279811 "[P] Periodic";
CM_ SG_ 2164279811 IMU_SeralNumVal "IMU_SerialNumberValue ##2G##YRS - YRS13 - YRS_SeralNo";
CM_ BO_ 2353205506 "[P] Periodic";
CM_ SG_ 2353205506 CBCR_SocConsumptionReq "Requests for Compulsory Battery Consumption for Regen.";
CM_ SG_ 2353205506 CBCR_CluDispMsgSta "CBCR logic requests to display message at cluster.";
CM_ BO_ 942 "[EC] On Event and On Change";
CM_ SG_ 942 AMP_Beep1VolumeStep "Command for Touch Beep Sound Volume Setting 
-range : 0 ~ max
-max : value of AMP_MaxBeep1VolumeState(0x087)
Harman AMP Only
-This Signal's Feedback is AMP_Beep1VolumeState(0x08A)@AMP";
CM_ BO_ 2164279810 "[P] Periodic";
CM_ SG_ 2164279810 IMU_YawRtVal "IMU_YawRateValue ##2G##YRS - YRS11 - CR_Yrs_Yr";
CM_ SG_ 2164279810 IMU_LatAccelVal "IMU_LateralAccelerationValue ##2G##YRS - YRS11 - CR_Yrs_LatAc";
CM_ SG_ 2164279810 IMU_LongAccelVal "IMU_LongitudinalAccelerationValue ##2G##YRS - YRS12 - CR_Yrs_LongAc";
CM_ SG_ 2164279810 IMU_SnsrTempVal "IMU_SensorTemperatureValue ##2G##YRS - YRS12 - YRS_Temp";
CM_ BO_ 2164279812 "[P] Periodic";
CM_ SG_ 2164279812 IMU_RollRtVal "IMU_Roll rate signal value";
CM_ SG_ 2164279812 IMU_VerAccelVal "IMU_Vertial Acceleration value";
CM_ BO_ 939 "[P] Periodic";
CM_ SG_ 939 PSB_Crc1Val "PSB_CyclicRedundancyCheck1Value";
CM_ SG_ 939 PSB_AlvCnt1Val "PSB_AliveCounter1Value";
CM_ SG_ 939 PSB_LHFlrSta "PSB_LeftHandedFailureStatus";
CM_ SG_ 939 PSB_LHActvSta "PSB_LeftHandedActiveStatus";
CM_ SG_ 939 PSB_RHFlrSta "PSB_RightHandedFailureStatus";
CM_ SG_ 939 PSB_RHActvSta "PSB_RightHandedActiveStatus";
CM_ SG_ 939 PSB_ActForAcu "PSB_ActiveForAcu";
CM_ SG_ 939 PSB_HapticWarnSta "PSB_Haptic_Warning_Status";
CM_ SG_ 939 PSB_RHActForPss "PSB_RightHandedActiveStatus_forPss";
CM_ SG_ 939 PSB_HDPSpprtSWVer "Requirement Spec Version about PSB haptic active by HDP";
CM_ SG_ 939 PSB_LHActForPss "PSB_LeftHandedActiveStatus_forPss";
CM_ BO_ 935 "[EC] On Event and On Change";
CM_ SG_ 935 SCM_AnySwOnEv "SCM_AnySwitchOnEvent";
CM_ BO_ 2239851012 "[P] Periodic";
CM_ SG_ 2239851012 RSPA_DCTTrgtTqVal "RSPA_DCTTargetTorqueValue";
CM_ SG_ 2239851012 MRA_BtnDispSta "MRA Button Display State";
CM_ SG_ 2239851012 RSPA_HdLmpReq "RSPA Head Lamp Request";
CM_ SG_ 2239851012 RSPA_BtnDispSta "RSPA Button Display State";
CM_ SG_ 2239851012 RSPA_OSMirFoldReq "RSPA_OSMirrorFoldRequest";
BA_DEF_ BO_  "DiagState" ENUM  "No","Yes";
BA_DEF_ BO_  "DiagResponse" ENUM  "No","Yes";
BA_DEF_ BO_  "DiagRequest" ENUM  "No","Yes";
BA_DEF_ BO_  "TpMessage" ENUM  "No","Yes";
BA_DEF_ BO_  "UsrMsgIDSforwardDeviation" INT 0 100;
BA_DEF_ BO_  "UsrMsgIDSbackwardDeviation" INT 50 1000;
BA_DEF_ BO_  "GenMsgCycleTime" INT 0 2000;
BA_DEF_ BO_  "GenMsgStartDelayTime" INT 0 2000;
BA_DEF_ BO_  "GenMsgSendType" ENUM  "Cyclic","NoMsgSendType";
BA_DEF_ BO_  "GenMsgCycleTimeFast" INT 0 500;
BA_DEF_ BO_  "GenMsgDelayTime" INT 0 20;
BA_DEF_ BO_  "GenMsgILSupport" ENUM  "No","Yes";
BA_DEF_ BO_  "GenMsgNrOfRepetition" INT 0 3;
BA_DEF_ BO_  "NmMessage" ENUM  "No","Yes";
BA_DEF_ BO_  "NWM-Botschaft" ENUM  "No","Yes";
BA_DEF_ BO_  "TpTxIndex" INT 0 65535;
BA_DEF_ BO_  "VFrameFormat" ENUM  "StandardCAN","ExtendedCAN","reserved","reserved","reserved","reserved","reserved","reserved","reserved","reserved","reserved","reserved","reserved","reserved","StandardCAN_FD","ExtendedCAN_FD";
BA_DEF_ SG_  "UserSigValidity" ENUM  "B+","ACC","IG","IG1","IG2","IG3","IG1 or IG2","IG1 or IG3","Undef";
BA_DEF_ SG_  "TimeoutValue" STRING ;
BA_DEF_ SG_  "UsrSigPurpose" ENUM  "Undef","FN","DIAG","DIAG(Req)","DIAG(Res)","DIAG(Phy)","DEV","CCP(Req)","CCP(Res)","NM","TP";
BA_DEF_ SG_  "GenSigStartValue" INT 0 1215752192;
BA_DEF_ SG_  "NetworkRequest" ENUM  "Yes","No";
BA_DEF_ SG_  "NetworkRequestHoldingTime" INT 0 65535;
BA_DEF_ SG_  "Description" STRING ;
BA_DEF_ SG_  "Version" STRING ;
BA_DEF_ SG_  "GenSigEnvVarType" ENUM  "Int","Float","Undef";
BA_DEF_ SG_  "GenSigSendType" ENUM  "Cyclic","OnWrite","OnWriteWithRepetition","OnChange","OnChangeWithRepetition","IfActive","IfActiveWithRepetition","NoSigSendType","OnChangeAndIfActive","OnChangeAndIfActiveWithRepetition";
BA_DEF_ SG_  "GwSigLatencyTime" INT 0 65536;
BA_DEF_ SG_  "GwSigMissingSourceType" ENUM  "Undef","OldValue","DefaultValue","InitialValue";
BA_DEF_ SG_  "NWM-WakeupAllowed" ENUM  "<n.a.>";
BA_DEF_ SG_  "RoutingFactor" INT 1 1215752192;
BA_DEF_ SG_  "SystemSignalLongSymbol" STRING ;
BA_DEF_REL_ BU_SG_REL_  "GenSigTimeoutTime" INT 0 7000;
BA_DEF_DEF_  "DiagState" "No";
BA_DEF_DEF_  "DiagResponse" "No";
BA_DEF_DEF_  "DiagRequest" "No";
BA_DEF_DEF_  "TpMessage" "No";
BA_DEF_DEF_  "UsrMsgIDSforwardDeviation" 10;
BA_DEF_DEF_  "UsrMsgIDSbackwardDeviation" 100;
BA_DEF_DEF_  "GenMsgCycleTime" 200;
BA_DEF_DEF_  "GenMsgStartDelayTime" 0;
BA_DEF_DEF_  "GenMsgSendType" "NoMsgSendType";
BA_DEF_DEF_  "GenMsgCycleTimeFast" 40;
BA_DEF_DEF_  "GenMsgDelayTime" 20;
BA_DEF_DEF_  "GenMsgILSupport" "Yes";
BA_DEF_DEF_  "GenMsgNrOfRepetition" 3;
BA_DEF_DEF_  "NmMessage" "No";
BA_DEF_DEF_  "NWM-Botschaft" "No";
BA_DEF_DEF_  "TpTxIndex" 0;
BA_DEF_DEF_  "VFrameFormat" "StandardCAN";
BA_DEF_DEF_  "UserSigValidity" "IG";
BA_DEF_DEF_  "TimeoutValue" "";
BA_DEF_DEF_  "UsrSigPurpose" "FN";
BA_DEF_DEF_  "GenSigStartValue" 0;
BA_DEF_DEF_  "NetworkRequest" "No";
BA_DEF_DEF_  "NetworkRequestHoldingTime" 0;
BA_DEF_DEF_  "Description" "";
BA_DEF_DEF_  "Version" "";
BA_DEF_DEF_  "GenSigEnvVarType" "Undef";
BA_DEF_DEF_  "GenSigSendType" "NoSigSendType";
BA_DEF_DEF_  "GwSigLatencyTime" 40;
BA_DEF_DEF_  "GwSigMissingSourceType" "Undef";
BA_DEF_DEF_  "NWM-WakeupAllowed" "<n.a.>";
BA_DEF_DEF_  "RoutingFactor" 1;
BA_DEF_DEF_REL_ "GenSigTimeoutTime" 500;
BA_DEF_DEF_  "SystemSignalLongSymbol" "";
BA_ "GenMsgSendType" BO_ 894 0;
BA_ "TpTxIndex" BO_ 1836 168;
BA_ "TpMessage" BO_ 1836 1;
BA_ "GenMsgILSupport" BO_ 1836 0;
BA_ "DiagResponse" BO_ 1836 1;
BA_ "GenMsgNrOfRepetition" BO_ 1836 0;
BA_ "GenMsgCycleTimeFast" BO_ 1836 0;
BA_ "GenMsgCycleTime" BO_ 1836 0;
BA_ "TpTxIndex" BO_ 1837 180;
BA_ "TpMessage" BO_ 1837 1;
BA_ "GenMsgILSupport" BO_ 1837 0;
BA_ "DiagResponse" BO_ 1837 1;
BA_ "GenMsgNrOfRepetition" BO_ 1837 0;
BA_ "GenMsgCycleTimeFast" BO_ 1837 0;
BA_ "GenMsgCycleTime" BO_ 1837 0;
BA_ "TpTxIndex" BO_ 1833 153;
BA_ "TpMessage" BO_ 1833 1;
BA_ "GenMsgILSupport" BO_ 1833 0;
BA_ "DiagResponse" BO_ 1833 1;
BA_ "GenMsgNrOfRepetition" BO_ 1833 0;
BA_ "GenMsgCycleTimeFast" BO_ 1833 0;
BA_ "GenMsgCycleTime" BO_ 1833 0;
BA_ "TpTxIndex" BO_ 1835 252;
BA_ "TpMessage" BO_ 1835 1;
BA_ "GenMsgILSupport" BO_ 1835 0;
BA_ "DiagResponse" BO_ 1835 1;
BA_ "GenMsgNrOfRepetition" BO_ 1835 0;
BA_ "GenMsgCycleTimeFast" BO_ 1835 0;
BA_ "GenMsgCycleTime" BO_ 1835 0;
BA_ "TpTxIndex" BO_ 1828 168;
BA_ "TpMessage" BO_ 1828 1;
BA_ "GenMsgILSupport" BO_ 1828 0;
BA_ "DiagRequest" BO_ 1828 1;
BA_ "GenMsgNrOfRepetition" BO_ 1828 0;
BA_ "GenMsgCycleTimeFast" BO_ 1828 0;
BA_ "GenMsgCycleTime" BO_ 1828 0;
BA_ "TpTxIndex" BO_ 1829 180;
BA_ "TpMessage" BO_ 1829 1;
BA_ "GenMsgILSupport" BO_ 1829 0;
BA_ "DiagRequest" BO_ 1829 1;
BA_ "GenMsgNrOfRepetition" BO_ 1829 0;
BA_ "GenMsgCycleTimeFast" BO_ 1829 0;
BA_ "GenMsgCycleTime" BO_ 1829 0;
BA_ "TpTxIndex" BO_ 1825 153;
BA_ "TpMessage" BO_ 1825 1;
BA_ "GenMsgILSupport" BO_ 1825 0;
BA_ "DiagRequest" BO_ 1825 1;
BA_ "GenMsgNrOfRepetition" BO_ 1825 0;
BA_ "GenMsgCycleTimeFast" BO_ 1825 0;
BA_ "GenMsgCycleTime" BO_ 1825 0;
BA_ "TpTxIndex" BO_ 1827 252;
BA_ "TpMessage" BO_ 1827 1;
BA_ "GenMsgILSupport" BO_ 1827 0;
BA_ "DiagRequest" BO_ 1827 1;
BA_ "GenMsgNrOfRepetition" BO_ 1827 0;
BA_ "GenMsgCycleTimeFast" BO_ 1827 0;
BA_ "GenMsgCycleTime" BO_ 1827 0;
BA_ "TpTxIndex" BO_ 1818 160;
BA_ "TpMessage" BO_ 1818 1;
BA_ "GenMsgILSupport" BO_ 1818 0;
BA_ "DiagResponse" BO_ 1818 1;
BA_ "GenMsgNrOfRepetition" BO_ 1818 0;
BA_ "GenMsgCycleTimeFast" BO_ 1818 0;
BA_ "GenMsgCycleTime" BO_ 1818 0;
BA_ "GenMsgSendType" BO_ 858 0;
BA_ "GenMsgSendType" BO_ 863 0;
BA_ "GenMsgSendType" BO_ 862 0;
BA_ "TpTxIndex" BO_ 1810 160;
BA_ "TpMessage" BO_ 1810 1;
BA_ "GenMsgILSupport" BO_ 1810 0;
BA_ "DiagRequest" BO_ 1810 1;
BA_ "GenMsgNrOfRepetition" BO_ 1810 0;
BA_ "GenMsgCycleTimeFast" BO_ 1810 0;
BA_ "GenMsgCycleTime" BO_ 1810 0;
BA_ "TpTxIndex" BO_ 1806 106;
BA_ "TpMessage" BO_ 1806 1;
BA_ "GenMsgILSupport" BO_ 1806 0;
BA_ "DiagResponse" BO_ 1806 1;
BA_ "GenMsgNrOfRepetition" BO_ 1806 0;
BA_ "GenMsgCycleTimeFast" BO_ 1806 0;
BA_ "GenMsgCycleTime" BO_ 1806 0;
BA_ "TpTxIndex" BO_ 1807 165;
BA_ "TpMessage" BO_ 1807 1;
BA_ "GenMsgILSupport" BO_ 1807 0;
BA_ "DiagResponse" BO_ 1807 1;
BA_ "GenMsgNrOfRepetition" BO_ 1807 0;
BA_ "GenMsgCycleTimeFast" BO_ 1807 0;
BA_ "GenMsgCycleTime" BO_ 1807 0;
BA_ "TpTxIndex" BO_ 1798 106;
BA_ "TpMessage" BO_ 1798 1;
BA_ "GenMsgILSupport" BO_ 1798 0;
BA_ "DiagRequest" BO_ 1798 1;
BA_ "GenMsgNrOfRepetition" BO_ 1798 0;
BA_ "GenMsgCycleTimeFast" BO_ 1798 0;
BA_ "GenMsgCycleTime" BO_ 1798 0;
BA_ "TpTxIndex" BO_ 1799 165;
BA_ "TpMessage" BO_ 1799 1;
BA_ "GenMsgILSupport" BO_ 1799 0;
BA_ "DiagRequest" BO_ 1799 1;
BA_ "GenMsgNrOfRepetition" BO_ 1799 0;
BA_ "GenMsgCycleTimeFast" BO_ 1799 0;
BA_ "GenMsgCycleTime" BO_ 1799 0;
BA_ "GenMsgSendType" BO_ 847 0;
BA_ "TpTxIndex" BO_ 2032 260;
BA_ "TpMessage" BO_ 2032 1;
BA_ "GenMsgILSupport" BO_ 2032 0;
BA_ "DiagRequest" BO_ 2032 1;
BA_ "GenMsgNrOfRepetition" BO_ 2032 0;
BA_ "GenMsgCycleTimeFast" BO_ 2032 0;
BA_ "GenMsgCycleTime" BO_ 2032 0;
BA_ "GenMsgSendType" BO_ 952 0;
BA_ "TpTxIndex" BO_ 2040 260;
BA_ "TpMessage" BO_ 2040 1;
BA_ "GenMsgILSupport" BO_ 2040 0;
BA_ "DiagResponse" BO_ 2040 1;
BA_ "GenMsgNrOfRepetition" BO_ 2040 0;
BA_ "GenMsgCycleTimeFast" BO_ 2040 0;
BA_ "GenMsgCycleTime" BO_ 2040 0;
BA_ "GenMsgSendType" BO_ 950 0;
BA_ "GenMsgSendType" BO_ 951 0;
BA_ "VFrameFormat" BO_ 2281835010 1;
BA_ "GenMsgNrOfRepetition" BO_ 2281835010 0;
BA_ "GenMsgCycleTimeFast" BO_ 2281835010 0;
BA_ "GenMsgCycleTime" BO_ 2281835010 100;
BA_ "GenMsgSendType" BO_ 2281835010 0;
BA_ "VFrameFormat" BO_ 2281835009 1;
BA_ "GenMsgNrOfRepetition" BO_ 2281835009 0;
BA_ "GenMsgCycleTimeFast" BO_ 2281835009 0;
BA_ "GenMsgCycleTime" BO_ 2281835009 100;
BA_ "GenMsgSendType" BO_ 2281835009 0;
BA_ "VFrameFormat" BO_ 2353205505 1;
BA_ "GenMsgNrOfRepetition" BO_ 2353205505 0;
BA_ "GenMsgCycleTimeFast" BO_ 2353205505 0;
BA_ "GenMsgCycleTime" BO_ 2353205505 400;
BA_ "GenMsgSendType" BO_ 2353205505 0;
BA_ "VFrameFormat" BO_ 2164279809 1;
BA_ "GenMsgNrOfRepetition" BO_ 2164279809 0;
BA_ "GenMsgCycleTimeFast" BO_ 2164279809 0;
BA_ "GenMsgCycleTime" BO_ 2164279809 50;
BA_ "GenMsgSendType" BO_ 2164279809 0;
BA_ "VFrameFormat" BO_ 2164279811 1;
BA_ "GenMsgNrOfRepetition" BO_ 2164279811 0;
BA_ "GenMsgCycleTimeFast" BO_ 2164279811 0;
BA_ "GenMsgCycleTime" BO_ 2164279811 50;
BA_ "GenMsgSendType" BO_ 2164279811 0;
BA_ "VFrameFormat" BO_ 2353205506 1;
BA_ "GenMsgNrOfRepetition" BO_ 2353205506 0;
BA_ "GenMsgCycleTimeFast" BO_ 2353205506 0;
BA_ "GenMsgCycleTime" BO_ 2353205506 400;
BA_ "GenMsgSendType" BO_ 2353205506 0;
BA_ "GenMsgCycleTime" BO_ 942 0;
BA_ "VFrameFormat" BO_ 2164279810 1;
BA_ "GenMsgNrOfRepetition" BO_ 2164279810 0;
BA_ "GenMsgCycleTimeFast" BO_ 2164279810 0;
BA_ "GenMsgCycleTime" BO_ 2164279810 50;
BA_ "GenMsgSendType" BO_ 2164279810 0;
BA_ "VFrameFormat" BO_ 2164279812 1;
BA_ "GenMsgNrOfRepetition" BO_ 2164279812 0;
BA_ "GenMsgCycleTimeFast" BO_ 2164279812 0;
BA_ "GenMsgCycleTime" BO_ 2164279812 50;
BA_ "GenMsgSendType" BO_ 2164279812 0;
BA_ "GenMsgNrOfRepetition" BO_ 939 0;
BA_ "GenMsgCycleTimeFast" BO_ 939 0;
BA_ "GenMsgSendType" BO_ 939 0;
BA_ "GenMsgCycleTime" BO_ 935 0;
BA_ "VFrameFormat" BO_ 2239851012 1;
BA_ "GenMsgNrOfRepetition" BO_ 2239851012 0;
BA_ "GenMsgCycleTimeFast" BO_ 2239851012 0;
BA_ "GenMsgCycleTime" BO_ 2239851012 100;
BA_ "GenMsgSendType" BO_ 2239851012 0;
BA_ "Version" SG_ 894 PDCex_Crc1Val "22.05.03";
BA_ "UserSigValidity" SG_ 894 PDCex_Crc1Val 0;
BA_ "GenSigSendType" SG_ 894 PDCex_Crc1Val 4;
BA_ "Description" SG_ 894 PDCex_Crc1Val "The data area for CRC calculation is based on the data length (DLC) of the message DB.

The CRC shall be calculated over the entire data block (excluding the CRC bytes) including the user data, alive counter and Data ID 

 

- CRC Polynomial (0x1D) , Ini";
BA_ "Version" SG_ 894 PDCex_4thRLSBRMatSw "21.10.05";
BA_ "NetworkRequestHoldingTime" SG_ 894 PDCex_4thRLSBRMatSw 5000;
BA_ "NetworkRequest" SG_ 894 PDCex_4thRLSBRMatSw 0;
BA_ "UserSigValidity" SG_ 894 PDCex_4thRLSBRMatSw 0;
BA_ "GenSigSendType" SG_ 894 PDCex_4thRLSBRMatSw 4;
BA_ "Description" SG_ 894 PDCex_4thRLSBRMatSw "4th Rear Left Seated State

This signal replaces C_4thRLSBRMatSw(ICU_08_200ms) of ICU when applying PDCex to MPV vehicle.";
BA_ "Version" SG_ 894 PDCex_4thRRSBRMatSw "21.10.05";
BA_ "NetworkRequestHoldingTime" SG_ 894 PDCex_4thRRSBRMatSw 5000;
BA_ "NetworkRequest" SG_ 894 PDCex_4thRRSBRMatSw 0;
BA_ "UserSigValidity" SG_ 894 PDCex_4thRRSBRMatSw 0;
BA_ "GenSigSendType" SG_ 894 PDCex_4thRRSBRMatSw 4;
BA_ "Description" SG_ 894 PDCex_4thRRSBRMatSw "4th Rear Right Seated State

This signal replaces C_4thRRSBRMatSw(ICU_08_200ms) of ICU when applying PDCex to MPV vehicle.";
BA_ "Version" SG_ 894 PDCex_AlvCnt1Val "22.05.03";
BA_ "UserSigValidity" SG_ 894 PDCex_AlvCnt1Val 0;
BA_ "GenSigSendType" SG_ 894 PDCex_AlvCnt1Val 4;
BA_ "Description" SG_ 894 PDCex_AlvCnt1Val "For the first transmission request for a data element the counter shall be initialized with 0 and shall be incremented by 1

for every subsequent send request. When the counter reaches the maximum value(0xE), then it shall restart with 0 for the next sen";
BA_ "Version" SG_ 894 PDCex_4thRLSeatBeltSW "21.10.05";
BA_ "NetworkRequestHoldingTime" SG_ 894 PDCex_4thRLSeatBeltSW 5000;
BA_ "NetworkRequest" SG_ 894 PDCex_4thRLSeatBeltSW 0;
BA_ "UserSigValidity" SG_ 894 PDCex_4thRLSeatBeltSW 0;
BA_ "GenSigSendType" SG_ 894 PDCex_4thRLSeatBeltSW 4;
BA_ "Description" SG_ 894 PDCex_4thRLSeatBeltSW "4th Rear Left Seat Belt Switch Status

This signal replaces C_4thRLSeatBeltSW(ICU_08_200ms) of ICU when applying PDCex to MPV vehicle.";
BA_ "Version" SG_ 894 PDCex_4thRCSeatBeltSW "21.10.05";
BA_ "NetworkRequestHoldingTime" SG_ 894 PDCex_4thRCSeatBeltSW 5000;
BA_ "NetworkRequest" SG_ 894 PDCex_4thRCSeatBeltSW 0;
BA_ "UserSigValidity" SG_ 894 PDCex_4thRCSeatBeltSW 0;
BA_ "GenSigSendType" SG_ 894 PDCex_4thRCSeatBeltSW 4;
BA_ "Description" SG_ 894 PDCex_4thRCSeatBeltSW "4th Rear Center Seat Belt Switch Status

This signal replaces C_4thRCSeatBeltSW(ICU_08_200ms) of ICU when applying PDCex to MPV vehicle.";
BA_ "Version" SG_ 894 PDCex_4thRRSeatBeltSW "21.10.05";
BA_ "NetworkRequestHoldingTime" SG_ 894 PDCex_4thRRSeatBeltSW 5000;
BA_ "NetworkRequest" SG_ 894 PDCex_4thRRSeatBeltSW 0;
BA_ "UserSigValidity" SG_ 894 PDCex_4thRRSeatBeltSW 0;
BA_ "GenSigSendType" SG_ 894 PDCex_4thRRSeatBeltSW 4;
BA_ "Description" SG_ 894 PDCex_4thRRSeatBeltSW "4th Rear Right Seat Belt Switch Status

This signal replaces C_4thRRSeatBeltSW(ICU_08_200ms) of ICU when applying PDCex to MPV vehicle.";
BA_ "Version" SG_ 894 PDCex_WirelessSBRWrngSta "21.10.05";
BA_ "NetworkRequestHoldingTime" SG_ 894 PDCex_WirelessSBRWrngSta 5000;
BA_ "NetworkRequest" SG_ 894 PDCex_WirelessSBRWrngSta 0;
BA_ "UserSigValidity" SG_ 894 PDCex_WirelessSBRWrngSta 0;
BA_ "GenSigSendType" SG_ 894 PDCex_WirelessSBRWrngSta 4;
BA_ "Description" SG_ 894 PDCex_WirelessSBRWrngSta "Wireless SBR Warning Status

This signal replaces Warn_SBRBattWrngSwSta(ICU_03_200ms) of ICU when applying PDCex to MPV vehicle.";
BA_ "Version" SG_ 894 PDCex_FrtSunroofOpnSta "21.10.05";
BA_ "NetworkRequestHoldingTime" SG_ 894 PDCex_FrtSunroofOpnSta 5000;
BA_ "NetworkRequest" SG_ 894 PDCex_FrtSunroofOpnSta 0;
BA_ "UserSigValidity" SG_ 894 PDCex_FrtSunroofOpnSta 0;
BA_ "GenSigSendType" SG_ 894 PDCex_FrtSunroofOpnSta 4;
BA_ "Description" SG_ 894 PDCex_FrtSunroofOpnSta "Front Sunroof Open Status

When PDCex is applied to MPV or Pickup vehicle and PDCex receives a front sunroof open/close status signal directly, this signal replaces IBU's BCM_SunRoofOpnSta (BCM_10_200ms) or RCM's RCM_SunroofOpnSta@RCM_02_200ms";
BA_ "Version" SG_ 894 PDCex_RrSunroofOpnSta "21.10.05";
BA_ "NetworkRequestHoldingTime" SG_ 894 PDCex_RrSunroofOpnSta 5000;
BA_ "NetworkRequest" SG_ 894 PDCex_RrSunroofOpnSta 0;
BA_ "UserSigValidity" SG_ 894 PDCex_RrSunroofOpnSta 0;
BA_ "GenSigSendType" SG_ 894 PDCex_RrSunroofOpnSta 4;
BA_ "Description" SG_ 894 PDCex_RrSunroofOpnSta "Rear Sunroof Open Status

When PDCex is applied to MPV vehicle and PDCex receives a rear sunroof open/close status signal directly, this signal replaces IBU's BCM_RrSunroofOpnSta(BCM_10_200ms)";
BA_ "Version" SG_ 894 PDCex_FuelDrOpenSta "21.10.05";
BA_ "NetworkRequestHoldingTime" SG_ 894 PDCex_FuelDrOpenSta 5000;
BA_ "NetworkRequest" SG_ 894 PDCex_FuelDrOpenSta 0;
BA_ "UserSigValidity" SG_ 894 PDCex_FuelDrOpenSta 0;
BA_ "GenSigSendType" SG_ 894 PDCex_FuelDrOpenSta 4;
BA_ "Description" SG_ 894 PDCex_FuelDrOpenSta "Fuel door open status of sliding door applied vehicle

This signal replaces C_FuelDrState(ICU_08_200ms) of ICU when applying PDCex to MPV vehicle.";
BA_ "Version" SG_ 894 PDCex_TlgtUnLkSta "21.10.05";
BA_ "NetworkRequestHoldingTime" SG_ 894 PDCex_TlgtUnLkSta 5000;
BA_ "NetworkRequest" SG_ 894 PDCex_TlgtUnLkSta 0;
BA_ "UserSigValidity" SG_ 894 PDCex_TlgtUnLkSta 0;
BA_ "GenSigSendType" SG_ 894 PDCex_TlgtUnLkSta 4;
BA_ "Description" SG_ 894 PDCex_TlgtUnLkSta "Tailgate unlocked status of MPV vehicle twin swing tailgate vehicle

This signal replaces Tlgt_UnLkSta(ICU_12_200ms) of ICU when PDCex is applied to MPV vehicles with twin swing type tailgate.";
BA_ "Version" SG_ 894 PDCex_PSDPwrModeOffSwSta "21.10.05";
BA_ "NetworkRequestHoldingTime" SG_ 894 PDCex_PSDPwrModeOffSwSta 5000;
BA_ "NetworkRequest" SG_ 894 PDCex_PSDPwrModeOffSwSta 0;
BA_ "UserSigValidity" SG_ 894 PDCex_PSDPwrModeOffSwSta 0;
BA_ "GenSigSendType" SG_ 894 PDCex_PSDPwrModeOffSwSta 4;
BA_ "Description" SG_ 894 PDCex_PSDPwrModeOffSwSta "PSD power mode off switch state(Self-return type)

-'On' value is output only during the time the switch is pressed

This signal replaces C_PSDPTGOnOffSw(ICU_08_200ms) of ICU when applying PDCex to MPV vehicle.";
BA_ "Version" SG_ 894 PDCex_StrBoxLidSta "21.10.05";
BA_ "NetworkRequestHoldingTime" SG_ 894 PDCex_StrBoxLidSta 5000;
BA_ "NetworkRequest" SG_ 894 PDCex_StrBoxLidSta 0;
BA_ "UserSigValidity" SG_ 894 PDCex_StrBoxLidSta 0;
BA_ "GenSigSendType" SG_ 894 PDCex_StrBoxLidSta 4;
BA_ "Description" SG_ 894 PDCex_StrBoxLidSta "Open Bed Storage Box Full Lock Switch State(Storage box lid open/close state)

This signal replaces Trunk_TrnkTlgtStrBoxLidSta(ICU_05_200ms) of ICU when applying PDCex to Pickup(Open bed) vehicle.";
BA_ "Version" SG_ 894 PDCex_StrBoxOutReleaseSwSta "21.10.05";
BA_ "NetworkRequestHoldingTime" SG_ 894 PDCex_StrBoxOutReleaseSwSta 5000;
BA_ "NetworkRequest" SG_ 894 PDCex_StrBoxOutReleaseSwSta 0;
BA_ "UserSigValidity" SG_ 894 PDCex_StrBoxOutReleaseSwSta 0;
BA_ "GenSigSendType" SG_ 894 PDCex_StrBoxOutReleaseSwSta 4;
BA_ "Description" SG_ 894 PDCex_StrBoxOutReleaseSwSta "External release switch(Self-return type) status to open open bed storage box

-'On' value is output only during the time the switch is pressed

This signal replaces Trunk_StrBoxOutReleaseSwSta(ICU_03_200ms) of ICU when applying PDCex to Pickup(Open bed)";
BA_ "Version" SG_ 894 PDCex_DoorLock_LkOutSta "21.11.05";
BA_ "NetworkRequestHoldingTime" SG_ 894 PDCex_DoorLock_LkOutSta 5000;
BA_ "NetworkRequest" SG_ 894 PDCex_DoorLock_LkOutSta 0;
BA_ "UserSigValidity" SG_ 894 PDCex_DoorLock_LkOutSta 0;
BA_ "GenSigSendType" SG_ 894 PDCex_DoorLock_LkOutSta 4;
BA_ "Description" SG_ 894 PDCex_DoorLock_LkOutSta "- Door Lock or Unlock Output State 



0x0 : Off (Door lock/unlock output Off state)



0x1 : On (Door lock/unlock output On state)";
BA_ "Version" SG_ 894 SeatBeltSwSta_4thLft "23.07.03";
BA_ "NetworkRequestHoldingTime" SG_ 894 SeatBeltSwSta_4thLft 5000;
BA_ "NetworkRequest" SG_ 894 SeatBeltSwSta_4thLft 0;
BA_ "UserSigValidity" SG_ 894 SeatBeltSwSta_4thLft 0;
BA_ "GenSigSendType" SG_ 894 SeatBeltSwSta_4thLft 4;
BA_ "Description" SG_ 894 SeatBeltSwSta_4thLft "4th Left Seat Belt Switch Status

This signal is set as 'Not Supported' if the seat belt is not installed for EDR law(UN ECE R160.01) and EURO NCAP";
BA_ "Version" SG_ 894 SeatBeltSwSta_4thCtr "23.07.03";
BA_ "NetworkRequestHoldingTime" SG_ 894 SeatBeltSwSta_4thCtr 5000;
BA_ "NetworkRequest" SG_ 894 SeatBeltSwSta_4thCtr 0;
BA_ "UserSigValidity" SG_ 894 SeatBeltSwSta_4thCtr 0;
BA_ "GenSigSendType" SG_ 894 SeatBeltSwSta_4thCtr 4;
BA_ "Description" SG_ 894 SeatBeltSwSta_4thCtr "4th Center Seat Belt Switch Status

This signal is set as 'Not Supported' if the seat belt is not installed for EDR law(UN ECE R160.01) and EURO NCAP";
BA_ "Version" SG_ 894 SeatBeltSwSta_4thRt "23.07.03";
BA_ "NetworkRequestHoldingTime" SG_ 894 SeatBeltSwSta_4thRt 5000;
BA_ "NetworkRequest" SG_ 894 SeatBeltSwSta_4thRt 0;
BA_ "UserSigValidity" SG_ 894 SeatBeltSwSta_4thRt 0;
BA_ "GenSigSendType" SG_ 894 SeatBeltSwSta_4thRt 4;
BA_ "Description" SG_ 894 SeatBeltSwSta_4thRt "4th Right Seat Belt Switch Status

This signal is set as 'Not Supported' if the seat belt is not installed for EDR law(UN ECE R160.01) and EURO NCAP";
BA_ "Version" SG_ 894 PDCex_OptTyp "23.07.01";
BA_ "NetworkRequestHoldingTime" SG_ 894 PDCex_OptTyp 5000;
BA_ "NetworkRequest" SG_ 894 PDCex_OptTyp 0;
BA_ "UserSigValidity" SG_ 894 PDCex_OptTyp 0;
BA_ "GenSigSendType" SG_ 894 PDCex_OptTyp 4;
BA_ "Description" SG_ 894 PDCex_OptTyp "MPV, Pickup, Curtain option of PDCex

This signal transmits MPV or Pickup or Curtain option information when PDCex is applied.";
BA_ "Version" SG_ 1836 RWPC_GST_Byte0 "22.07.01";
BA_ "NetworkRequestHoldingTime" SG_ 1836 RWPC_GST_Byte0 5000;
BA_ "NetworkRequest" SG_ 1836 RWPC_GST_Byte0 0;
BA_ "UserSigValidity" SG_ 1836 RWPC_GST_Byte0 0;
BA_ "UsrSigPurpose" SG_ 1836 RWPC_GST_Byte0 4;
BA_ "Description" SG_ 1836 RWPC_GST_Byte0 "TP Index : 168";
BA_ "Version" SG_ 1836 RWPC_GST_Byte2 "22.07.01";
BA_ "NetworkRequestHoldingTime" SG_ 1836 RWPC_GST_Byte2 5000;
BA_ "NetworkRequest" SG_ 1836 RWPC_GST_Byte2 0;
BA_ "UserSigValidity" SG_ 1836 RWPC_GST_Byte2 0;
BA_ "UsrSigPurpose" SG_ 1836 RWPC_GST_Byte2 4;
BA_ "Description" SG_ 1836 RWPC_GST_Byte2 "TP Index : 168";
BA_ "Version" SG_ 1836 RWPC_GST_Byte3 "22.07.01";
BA_ "NetworkRequestHoldingTime" SG_ 1836 RWPC_GST_Byte3 5000;
BA_ "NetworkRequest" SG_ 1836 RWPC_GST_Byte3 0;
BA_ "UserSigValidity" SG_ 1836 RWPC_GST_Byte3 0;
BA_ "UsrSigPurpose" SG_ 1836 RWPC_GST_Byte3 4;
BA_ "Description" SG_ 1836 RWPC_GST_Byte3 "TP Index : 168";
BA_ "Version" SG_ 1836 RWPC_GST_Byte4 "22.07.01";
BA_ "NetworkRequestHoldingTime" SG_ 1836 RWPC_GST_Byte4 5000;
BA_ "NetworkRequest" SG_ 1836 RWPC_GST_Byte4 0;
BA_ "UserSigValidity" SG_ 1836 RWPC_GST_Byte4 0;
BA_ "UsrSigPurpose" SG_ 1836 RWPC_GST_Byte4 4;
BA_ "Description" SG_ 1836 RWPC_GST_Byte4 "TP Index : 168";
BA_ "Version" SG_ 1836 RWPC_GST_Byte5 "22.07.01";
BA_ "NetworkRequestHoldingTime" SG_ 1836 RWPC_GST_Byte5 5000;
BA_ "NetworkRequest" SG_ 1836 RWPC_GST_Byte5 0;
BA_ "UserSigValidity" SG_ 1836 RWPC_GST_Byte5 0;
BA_ "UsrSigPurpose" SG_ 1836 RWPC_GST_Byte5 4;
BA_ "Description" SG_ 1836 RWPC_GST_Byte5 "TP Index : 168";
BA_ "Version" SG_ 1836 RWPC_GST_Byte6 "22.07.01";
BA_ "NetworkRequestHoldingTime" SG_ 1836 RWPC_GST_Byte6 5000;
BA_ "NetworkRequest" SG_ 1836 RWPC_GST_Byte6 0;
BA_ "UserSigValidity" SG_ 1836 RWPC_GST_Byte6 0;
BA_ "UsrSigPurpose" SG_ 1836 RWPC_GST_Byte6 4;
BA_ "Description" SG_ 1836 RWPC_GST_Byte6 "TP Index : 168";
BA_ "Version" SG_ 1836 RWPC_GST_Byte7 "22.07.01";
BA_ "NetworkRequestHoldingTime" SG_ 1836 RWPC_GST_Byte7 5000;
BA_ "NetworkRequest" SG_ 1836 RWPC_GST_Byte7 0;
BA_ "UserSigValidity" SG_ 1836 RWPC_GST_Byte7 0;
BA_ "UsrSigPurpose" SG_ 1836 RWPC_GST_Byte7 4;
BA_ "Description" SG_ 1836 RWPC_GST_Byte7 "TP Index : 168";
BA_ "Version" SG_ 1836 RWPC_GST_Byte1 "22.07.01";
BA_ "NetworkRequestHoldingTime" SG_ 1836 RWPC_GST_Byte1 5000;
BA_ "NetworkRequest" SG_ 1836 RWPC_GST_Byte1 0;
BA_ "UserSigValidity" SG_ 1836 RWPC_GST_Byte1 0;
BA_ "UsrSigPurpose" SG_ 1836 RWPC_GST_Byte1 4;
BA_ "Description" SG_ 1836 RWPC_GST_Byte1 "TP Index : 168";
BA_ "Version" SG_ 1837 WPC_GST_Byte0 "22.07.01";
BA_ "NetworkRequestHoldingTime" SG_ 1837 WPC_GST_Byte0 5000;
BA_ "NetworkRequest" SG_ 1837 WPC_GST_Byte0 0;
BA_ "UserSigValidity" SG_ 1837 WPC_GST_Byte0 0;
BA_ "UsrSigPurpose" SG_ 1837 WPC_GST_Byte0 4;
BA_ "Description" SG_ 1837 WPC_GST_Byte0 "TP Index : 180";
BA_ "Version" SG_ 1837 WPC_GST_Byte2 "22.07.01";
BA_ "NetworkRequestHoldingTime" SG_ 1837 WPC_GST_Byte2 5000;
BA_ "NetworkRequest" SG_ 1837 WPC_GST_Byte2 0;
BA_ "UserSigValidity" SG_ 1837 WPC_GST_Byte2 0;
BA_ "UsrSigPurpose" SG_ 1837 WPC_GST_Byte2 4;
BA_ "Description" SG_ 1837 WPC_GST_Byte2 "TP Index : 180";
BA_ "Version" SG_ 1837 WPC_GST_Byte3 "22.07.01";
BA_ "NetworkRequestHoldingTime" SG_ 1837 WPC_GST_Byte3 5000;
BA_ "NetworkRequest" SG_ 1837 WPC_GST_Byte3 0;
BA_ "UserSigValidity" SG_ 1837 WPC_GST_Byte3 0;
BA_ "UsrSigPurpose" SG_ 1837 WPC_GST_Byte3 4;
BA_ "Description" SG_ 1837 WPC_GST_Byte3 "TP Index : 180";
BA_ "Version" SG_ 1837 WPC_GST_Byte4 "22.07.01";
BA_ "NetworkRequestHoldingTime" SG_ 1837 WPC_GST_Byte4 5000;
BA_ "NetworkRequest" SG_ 1837 WPC_GST_Byte4 0;
BA_ "UserSigValidity" SG_ 1837 WPC_GST_Byte4 0;
BA_ "UsrSigPurpose" SG_ 1837 WPC_GST_Byte4 4;
BA_ "Description" SG_ 1837 WPC_GST_Byte4 "TP Index : 180";
BA_ "Version" SG_ 1837 WPC_GST_Byte5 "22.07.01";
BA_ "NetworkRequestHoldingTime" SG_ 1837 WPC_GST_Byte5 5000;
BA_ "NetworkRequest" SG_ 1837 WPC_GST_Byte5 0;
BA_ "UserSigValidity" SG_ 1837 WPC_GST_Byte5 0;
BA_ "UsrSigPurpose" SG_ 1837 WPC_GST_Byte5 4;
BA_ "Description" SG_ 1837 WPC_GST_Byte5 "TP Index : 180";
BA_ "Version" SG_ 1837 WPC_GST_Byte6 "22.07.01";
BA_ "NetworkRequestHoldingTime" SG_ 1837 WPC_GST_Byte6 5000;
BA_ "NetworkRequest" SG_ 1837 WPC_GST_Byte6 0;
BA_ "UserSigValidity" SG_ 1837 WPC_GST_Byte6 0;
BA_ "UsrSigPurpose" SG_ 1837 WPC_GST_Byte6 4;
BA_ "Description" SG_ 1837 WPC_GST_Byte6 "TP Index : 180";
BA_ "Version" SG_ 1837 WPC_GST_Byte7 "22.07.01";
BA_ "NetworkRequestHoldingTime" SG_ 1837 WPC_GST_Byte7 5000;
BA_ "NetworkRequest" SG_ 1837 WPC_GST_Byte7 0;
BA_ "UserSigValidity" SG_ 1837 WPC_GST_Byte7 0;
BA_ "UsrSigPurpose" SG_ 1837 WPC_GST_Byte7 4;
BA_ "Description" SG_ 1837 WPC_GST_Byte7 "TP Index : 180";
BA_ "Version" SG_ 1837 WPC_GST_Byte1 "22.07.01";
BA_ "NetworkRequestHoldingTime" SG_ 1837 WPC_GST_Byte1 5000;
BA_ "NetworkRequest" SG_ 1837 WPC_GST_Byte1 0;
BA_ "UserSigValidity" SG_ 1837 WPC_GST_Byte1 0;
BA_ "UsrSigPurpose" SG_ 1837 WPC_GST_Byte1 4;
BA_ "Description" SG_ 1837 WPC_GST_Byte1 "TP Index : 180";
BA_ "Version" SG_ 1833 PSS_3RD_GST_Byte0 "22.10.16";
BA_ "NetworkRequestHoldingTime" SG_ 1833 PSS_3RD_GST_Byte0 5000;
BA_ "NetworkRequest" SG_ 1833 PSS_3RD_GST_Byte0 0;
BA_ "UserSigValidity" SG_ 1833 PSS_3RD_GST_Byte0 0;
BA_ "UsrSigPurpose" SG_ 1833 PSS_3RD_GST_Byte0 4;
BA_ "Description" SG_ 1833 PSS_3RD_GST_Byte0 "TP Index : 153";
BA_ "Version" SG_ 1833 PSS_3RD_GST_Byte2 "22.10.16";
BA_ "NetworkRequestHoldingTime" SG_ 1833 PSS_3RD_GST_Byte2 5000;
BA_ "NetworkRequest" SG_ 1833 PSS_3RD_GST_Byte2 0;
BA_ "UserSigValidity" SG_ 1833 PSS_3RD_GST_Byte2 0;
BA_ "UsrSigPurpose" SG_ 1833 PSS_3RD_GST_Byte2 4;
BA_ "Description" SG_ 1833 PSS_3RD_GST_Byte2 "TP Index : 153";
BA_ "Version" SG_ 1833 PSS_3RD_GST_Byte3 "22.10.16";
BA_ "NetworkRequestHoldingTime" SG_ 1833 PSS_3RD_GST_Byte3 5000;
BA_ "NetworkRequest" SG_ 1833 PSS_3RD_GST_Byte3 0;
BA_ "UserSigValidity" SG_ 1833 PSS_3RD_GST_Byte3 0;
BA_ "UsrSigPurpose" SG_ 1833 PSS_3RD_GST_Byte3 4;
BA_ "Description" SG_ 1833 PSS_3RD_GST_Byte3 "TP Index : 153";
BA_ "Version" SG_ 1833 PSS_3RD_GST_Byte4 "22.10.16";
BA_ "NetworkRequestHoldingTime" SG_ 1833 PSS_3RD_GST_Byte4 5000;
BA_ "NetworkRequest" SG_ 1833 PSS_3RD_GST_Byte4 0;
BA_ "UserSigValidity" SG_ 1833 PSS_3RD_GST_Byte4 0;
BA_ "UsrSigPurpose" SG_ 1833 PSS_3RD_GST_Byte4 4;
BA_ "Description" SG_ 1833 PSS_3RD_GST_Byte4 "TP Index : 153";
BA_ "Version" SG_ 1833 PSS_3RD_GST_Byte5 "22.10.16";
BA_ "NetworkRequestHoldingTime" SG_ 1833 PSS_3RD_GST_Byte5 5000;
BA_ "NetworkRequest" SG_ 1833 PSS_3RD_GST_Byte5 0;
BA_ "UserSigValidity" SG_ 1833 PSS_3RD_GST_Byte5 0;
BA_ "UsrSigPurpose" SG_ 1833 PSS_3RD_GST_Byte5 4;
BA_ "Description" SG_ 1833 PSS_3RD_GST_Byte5 "TP Index : 153";
BA_ "Version" SG_ 1833 PSS_3RD_GST_Byte6 "22.10.16";
BA_ "NetworkRequestHoldingTime" SG_ 1833 PSS_3RD_GST_Byte6 5000;
BA_ "NetworkRequest" SG_ 1833 PSS_3RD_GST_Byte6 0;
BA_ "UserSigValidity" SG_ 1833 PSS_3RD_GST_Byte6 0;
BA_ "UsrSigPurpose" SG_ 1833 PSS_3RD_GST_Byte6 4;
BA_ "Description" SG_ 1833 PSS_3RD_GST_Byte6 "TP Index : 153";
BA_ "Version" SG_ 1833 PSS_3RD_GST_Byte7 "22.10.16";
BA_ "NetworkRequestHoldingTime" SG_ 1833 PSS_3RD_GST_Byte7 5000;
BA_ "NetworkRequest" SG_ 1833 PSS_3RD_GST_Byte7 0;
BA_ "UserSigValidity" SG_ 1833 PSS_3RD_GST_Byte7 0;
BA_ "UsrSigPurpose" SG_ 1833 PSS_3RD_GST_Byte7 4;
BA_ "Description" SG_ 1833 PSS_3RD_GST_Byte7 "TP Index : 153";
BA_ "Version" SG_ 1833 PSS_3RD_GST_Byte1 "22.10.16";
BA_ "NetworkRequestHoldingTime" SG_ 1833 PSS_3RD_GST_Byte1 5000;
BA_ "NetworkRequest" SG_ 1833 PSS_3RD_GST_Byte1 0;
BA_ "UserSigValidity" SG_ 1833 PSS_3RD_GST_Byte1 0;
BA_ "UsrSigPurpose" SG_ 1833 PSS_3RD_GST_Byte1 4;
BA_ "Description" SG_ 1833 PSS_3RD_GST_Byte1 "TP Index : 153";
BA_ "Version" SG_ 1835 WPC2_GST_Byte0 "22.07.01";
BA_ "NetworkRequestHoldingTime" SG_ 1835 WPC2_GST_Byte0 5000;
BA_ "NetworkRequest" SG_ 1835 WPC2_GST_Byte0 0;
BA_ "UserSigValidity" SG_ 1835 WPC2_GST_Byte0 0;
BA_ "UsrSigPurpose" SG_ 1835 WPC2_GST_Byte0 4;
BA_ "Description" SG_ 1835 WPC2_GST_Byte0 "TP Index : 252";
BA_ "Version" SG_ 1835 WPC2_GST_Byte2 "22.07.01";
BA_ "NetworkRequestHoldingTime" SG_ 1835 WPC2_GST_Byte2 5000;
BA_ "NetworkRequest" SG_ 1835 WPC2_GST_Byte2 0;
BA_ "UserSigValidity" SG_ 1835 WPC2_GST_Byte2 0;
BA_ "UsrSigPurpose" SG_ 1835 WPC2_GST_Byte2 4;
BA_ "Description" SG_ 1835 WPC2_GST_Byte2 "TP Index : 252";
BA_ "Version" SG_ 1835 WPC2_GST_Byte3 "22.07.01";
BA_ "NetworkRequestHoldingTime" SG_ 1835 WPC2_GST_Byte3 5000;
BA_ "NetworkRequest" SG_ 1835 WPC2_GST_Byte3 0;
BA_ "UserSigValidity" SG_ 1835 WPC2_GST_Byte3 0;
BA_ "UsrSigPurpose" SG_ 1835 WPC2_GST_Byte3 4;
BA_ "Description" SG_ 1835 WPC2_GST_Byte3 "TP Index : 252";
BA_ "Version" SG_ 1835 WPC2_GST_Byte4 "22.07.01";
BA_ "NetworkRequestHoldingTime" SG_ 1835 WPC2_GST_Byte4 5000;
BA_ "NetworkRequest" SG_ 1835 WPC2_GST_Byte4 0;
BA_ "UserSigValidity" SG_ 1835 WPC2_GST_Byte4 0;
BA_ "UsrSigPurpose" SG_ 1835 WPC2_GST_Byte4 4;
BA_ "Description" SG_ 1835 WPC2_GST_Byte4 "TP Index : 252";
BA_ "Version" SG_ 1835 WPC2_GST_Byte5 "22.07.01";
BA_ "NetworkRequestHoldingTime" SG_ 1835 WPC2_GST_Byte5 5000;
BA_ "NetworkRequest" SG_ 1835 WPC2_GST_Byte5 0;
BA_ "UserSigValidity" SG_ 1835 WPC2_GST_Byte5 0;
BA_ "UsrSigPurpose" SG_ 1835 WPC2_GST_Byte5 4;
BA_ "Description" SG_ 1835 WPC2_GST_Byte5 "TP Index : 252";
BA_ "Version" SG_ 1835 WPC2_GST_Byte6 "22.07.01";
BA_ "NetworkRequestHoldingTime" SG_ 1835 WPC2_GST_Byte6 5000;
BA_ "NetworkRequest" SG_ 1835 WPC2_GST_Byte6 0;
BA_ "UserSigValidity" SG_ 1835 WPC2_GST_Byte6 0;
BA_ "UsrSigPurpose" SG_ 1835 WPC2_GST_Byte6 4;
BA_ "Description" SG_ 1835 WPC2_GST_Byte6 "TP Index : 252";
BA_ "Version" SG_ 1835 WPC2_GST_Byte7 "22.07.01";
BA_ "NetworkRequestHoldingTime" SG_ 1835 WPC2_GST_Byte7 5000;
BA_ "NetworkRequest" SG_ 1835 WPC2_GST_Byte7 0;
BA_ "UserSigValidity" SG_ 1835 WPC2_GST_Byte7 0;
BA_ "UsrSigPurpose" SG_ 1835 WPC2_GST_Byte7 4;
BA_ "Description" SG_ 1835 WPC2_GST_Byte7 "TP Index : 252";
BA_ "Version" SG_ 1835 WPC2_GST_Byte1 "22.07.01";
BA_ "NetworkRequestHoldingTime" SG_ 1835 WPC2_GST_Byte1 5000;
BA_ "NetworkRequest" SG_ 1835 WPC2_GST_Byte1 0;
BA_ "UserSigValidity" SG_ 1835 WPC2_GST_Byte1 0;
BA_ "UsrSigPurpose" SG_ 1835 WPC2_GST_Byte1 4;
BA_ "Description" SG_ 1835 WPC2_GST_Byte1 "TP Index : 252";
BA_ "Version" SG_ 1828 GST_RWPC_Byte0 "21.02.04";
BA_ "NetworkRequestHoldingTime" SG_ 1828 GST_RWPC_Byte0 5000;
BA_ "NetworkRequest" SG_ 1828 GST_RWPC_Byte0 0;
BA_ "UserSigValidity" SG_ 1828 GST_RWPC_Byte0 0;
BA_ "UsrSigPurpose" SG_ 1828 GST_RWPC_Byte0 3;
BA_ "Description" SG_ 1828 GST_RWPC_Byte0 "TP Index : 168";
BA_ "Version" SG_ 1828 GST_RWPC_Byte2 "21.02.04";
BA_ "NetworkRequestHoldingTime" SG_ 1828 GST_RWPC_Byte2 5000;
BA_ "NetworkRequest" SG_ 1828 GST_RWPC_Byte2 0;
BA_ "UserSigValidity" SG_ 1828 GST_RWPC_Byte2 0;
BA_ "UsrSigPurpose" SG_ 1828 GST_RWPC_Byte2 3;
BA_ "Description" SG_ 1828 GST_RWPC_Byte2 "TP Index : 168";
BA_ "Version" SG_ 1828 GST_RWPC_Byte3 "21.02.04";
BA_ "NetworkRequestHoldingTime" SG_ 1828 GST_RWPC_Byte3 5000;
BA_ "NetworkRequest" SG_ 1828 GST_RWPC_Byte3 0;
BA_ "UserSigValidity" SG_ 1828 GST_RWPC_Byte3 0;
BA_ "UsrSigPurpose" SG_ 1828 GST_RWPC_Byte3 3;
BA_ "Description" SG_ 1828 GST_RWPC_Byte3 "TP Index : 168";
BA_ "Version" SG_ 1828 GST_RWPC_Byte4 "21.02.04";
BA_ "NetworkRequestHoldingTime" SG_ 1828 GST_RWPC_Byte4 5000;
BA_ "NetworkRequest" SG_ 1828 GST_RWPC_Byte4 0;
BA_ "UserSigValidity" SG_ 1828 GST_RWPC_Byte4 0;
BA_ "UsrSigPurpose" SG_ 1828 GST_RWPC_Byte4 3;
BA_ "Description" SG_ 1828 GST_RWPC_Byte4 "TP Index : 168";
BA_ "Version" SG_ 1828 GST_RWPC_Byte5 "21.02.04";
BA_ "NetworkRequestHoldingTime" SG_ 1828 GST_RWPC_Byte5 5000;
BA_ "NetworkRequest" SG_ 1828 GST_RWPC_Byte5 0;
BA_ "UserSigValidity" SG_ 1828 GST_RWPC_Byte5 0;
BA_ "UsrSigPurpose" SG_ 1828 GST_RWPC_Byte5 3;
BA_ "Description" SG_ 1828 GST_RWPC_Byte5 "TP Index : 168";
BA_ "Version" SG_ 1828 GST_RWPC_Byte6 "21.02.04";
BA_ "NetworkRequestHoldingTime" SG_ 1828 GST_RWPC_Byte6 5000;
BA_ "NetworkRequest" SG_ 1828 GST_RWPC_Byte6 0;
BA_ "UserSigValidity" SG_ 1828 GST_RWPC_Byte6 0;
BA_ "UsrSigPurpose" SG_ 1828 GST_RWPC_Byte6 3;
BA_ "Description" SG_ 1828 GST_RWPC_Byte6 "TP Index : 168";
BA_ "Version" SG_ 1828 GST_RWPC_Byte7 "21.02.04";
BA_ "NetworkRequestHoldingTime" SG_ 1828 GST_RWPC_Byte7 5000;
BA_ "NetworkRequest" SG_ 1828 GST_RWPC_Byte7 0;
BA_ "UserSigValidity" SG_ 1828 GST_RWPC_Byte7 0;
BA_ "UsrSigPurpose" SG_ 1828 GST_RWPC_Byte7 3;
BA_ "Description" SG_ 1828 GST_RWPC_Byte7 "TP Index : 168";
BA_ "Version" SG_ 1828 GST_RWPC_Byte1 "21.02.04";
BA_ "NetworkRequestHoldingTime" SG_ 1828 GST_RWPC_Byte1 5000;
BA_ "NetworkRequest" SG_ 1828 GST_RWPC_Byte1 0;
BA_ "UserSigValidity" SG_ 1828 GST_RWPC_Byte1 0;
BA_ "UsrSigPurpose" SG_ 1828 GST_RWPC_Byte1 3;
BA_ "Description" SG_ 1828 GST_RWPC_Byte1 "TP Index : 168";
BA_ "Version" SG_ 1829 GST_WPC_Byte0 "21.02.04";
BA_ "NetworkRequestHoldingTime" SG_ 1829 GST_WPC_Byte0 5000;
BA_ "NetworkRequest" SG_ 1829 GST_WPC_Byte0 0;
BA_ "UserSigValidity" SG_ 1829 GST_WPC_Byte0 0;
BA_ "UsrSigPurpose" SG_ 1829 GST_WPC_Byte0 3;
BA_ "Description" SG_ 1829 GST_WPC_Byte0 "TP Index : 180";
BA_ "Version" SG_ 1829 GST_WPC_Byte2 "21.02.04";
BA_ "NetworkRequestHoldingTime" SG_ 1829 GST_WPC_Byte2 5000;
BA_ "NetworkRequest" SG_ 1829 GST_WPC_Byte2 0;
BA_ "UserSigValidity" SG_ 1829 GST_WPC_Byte2 0;
BA_ "UsrSigPurpose" SG_ 1829 GST_WPC_Byte2 3;
BA_ "Description" SG_ 1829 GST_WPC_Byte2 "TP Index : 180";
BA_ "Version" SG_ 1829 GST_WPC_Byte3 "21.02.04";
BA_ "NetworkRequestHoldingTime" SG_ 1829 GST_WPC_Byte3 5000;
BA_ "NetworkRequest" SG_ 1829 GST_WPC_Byte3 0;
BA_ "UserSigValidity" SG_ 1829 GST_WPC_Byte3 0;
BA_ "UsrSigPurpose" SG_ 1829 GST_WPC_Byte3 3;
BA_ "Description" SG_ 1829 GST_WPC_Byte3 "TP Index : 180";
BA_ "Version" SG_ 1829 GST_WPC_Byte4 "21.02.04";
BA_ "NetworkRequestHoldingTime" SG_ 1829 GST_WPC_Byte4 5000;
BA_ "NetworkRequest" SG_ 1829 GST_WPC_Byte4 0;
BA_ "UserSigValidity" SG_ 1829 GST_WPC_Byte4 0;
BA_ "UsrSigPurpose" SG_ 1829 GST_WPC_Byte4 3;
BA_ "Description" SG_ 1829 GST_WPC_Byte4 "TP Index : 180";
BA_ "Version" SG_ 1829 GST_WPC_Byte5 "21.02.04";
BA_ "NetworkRequestHoldingTime" SG_ 1829 GST_WPC_Byte5 5000;
BA_ "NetworkRequest" SG_ 1829 GST_WPC_Byte5 0;
BA_ "UserSigValidity" SG_ 1829 GST_WPC_Byte5 0;
BA_ "UsrSigPurpose" SG_ 1829 GST_WPC_Byte5 3;
BA_ "Description" SG_ 1829 GST_WPC_Byte5 "TP Index : 180";
BA_ "Version" SG_ 1829 GST_WPC_Byte6 "21.02.04";
BA_ "NetworkRequestHoldingTime" SG_ 1829 GST_WPC_Byte6 5000;
BA_ "NetworkRequest" SG_ 1829 GST_WPC_Byte6 0;
BA_ "UserSigValidity" SG_ 1829 GST_WPC_Byte6 0;
BA_ "UsrSigPurpose" SG_ 1829 GST_WPC_Byte6 3;
BA_ "Description" SG_ 1829 GST_WPC_Byte6 "TP Index : 180";
BA_ "Version" SG_ 1829 GST_WPC_Byte7 "21.02.04";
BA_ "NetworkRequestHoldingTime" SG_ 1829 GST_WPC_Byte7 5000;
BA_ "NetworkRequest" SG_ 1829 GST_WPC_Byte7 0;
BA_ "UserSigValidity" SG_ 1829 GST_WPC_Byte7 0;
BA_ "UsrSigPurpose" SG_ 1829 GST_WPC_Byte7 3;
BA_ "Description" SG_ 1829 GST_WPC_Byte7 "TP Index : 180";
BA_ "Version" SG_ 1829 GST_WPC_Byte1 "21.02.04";
BA_ "NetworkRequestHoldingTime" SG_ 1829 GST_WPC_Byte1 5000;
BA_ "NetworkRequest" SG_ 1829 GST_WPC_Byte1 0;
BA_ "UserSigValidity" SG_ 1829 GST_WPC_Byte1 0;
BA_ "UsrSigPurpose" SG_ 1829 GST_WPC_Byte1 3;
BA_ "Description" SG_ 1829 GST_WPC_Byte1 "TP Index : 180";
BA_ "Version" SG_ 1825 GST_PSS_3RD_Byte0 "22.10.16";
BA_ "NetworkRequestHoldingTime" SG_ 1825 GST_PSS_3RD_Byte0 5000;
BA_ "NetworkRequest" SG_ 1825 GST_PSS_3RD_Byte0 0;
BA_ "UserSigValidity" SG_ 1825 GST_PSS_3RD_Byte0 0;
BA_ "UsrSigPurpose" SG_ 1825 GST_PSS_3RD_Byte0 3;
BA_ "Description" SG_ 1825 GST_PSS_3RD_Byte0 "TP Index : 153";
BA_ "Version" SG_ 1825 GST_PSS_3RD_Byte2 "22.10.16";
BA_ "NetworkRequestHoldingTime" SG_ 1825 GST_PSS_3RD_Byte2 5000;
BA_ "NetworkRequest" SG_ 1825 GST_PSS_3RD_Byte2 0;
BA_ "UserSigValidity" SG_ 1825 GST_PSS_3RD_Byte2 0;
BA_ "UsrSigPurpose" SG_ 1825 GST_PSS_3RD_Byte2 3;
BA_ "Description" SG_ 1825 GST_PSS_3RD_Byte2 "TP Index : 153";
BA_ "Version" SG_ 1825 GST_PSS_3RD_Byte3 "22.10.16";
BA_ "NetworkRequestHoldingTime" SG_ 1825 GST_PSS_3RD_Byte3 5000;
BA_ "NetworkRequest" SG_ 1825 GST_PSS_3RD_Byte3 0;
BA_ "UserSigValidity" SG_ 1825 GST_PSS_3RD_Byte3 0;
BA_ "UsrSigPurpose" SG_ 1825 GST_PSS_3RD_Byte3 3;
BA_ "Description" SG_ 1825 GST_PSS_3RD_Byte3 "TP Index : 153";
BA_ "Version" SG_ 1825 GST_PSS_3RD_Byte4 "22.10.16";
BA_ "NetworkRequestHoldingTime" SG_ 1825 GST_PSS_3RD_Byte4 5000;
BA_ "NetworkRequest" SG_ 1825 GST_PSS_3RD_Byte4 0;
BA_ "UserSigValidity" SG_ 1825 GST_PSS_3RD_Byte4 0;
BA_ "UsrSigPurpose" SG_ 1825 GST_PSS_3RD_Byte4 3;
BA_ "Description" SG_ 1825 GST_PSS_3RD_Byte4 "TP Index : 153";
BA_ "Version" SG_ 1825 GST_PSS_3RD_Byte5 "22.10.16";
BA_ "NetworkRequestHoldingTime" SG_ 1825 GST_PSS_3RD_Byte5 5000;
BA_ "NetworkRequest" SG_ 1825 GST_PSS_3RD_Byte5 0;
BA_ "UserSigValidity" SG_ 1825 GST_PSS_3RD_Byte5 0;
BA_ "UsrSigPurpose" SG_ 1825 GST_PSS_3RD_Byte5 3;
BA_ "Description" SG_ 1825 GST_PSS_3RD_Byte5 "TP Index : 153";
BA_ "Version" SG_ 1825 GST_PSS_3RD_Byte6 "22.10.16";
BA_ "NetworkRequestHoldingTime" SG_ 1825 GST_PSS_3RD_Byte6 5000;
BA_ "NetworkRequest" SG_ 1825 GST_PSS_3RD_Byte6 0;
BA_ "UserSigValidity" SG_ 1825 GST_PSS_3RD_Byte6 0;
BA_ "UsrSigPurpose" SG_ 1825 GST_PSS_3RD_Byte6 3;
BA_ "Description" SG_ 1825 GST_PSS_3RD_Byte6 "TP Index : 153";
BA_ "Version" SG_ 1825 GST_PSS_3RD_Byte7 "22.10.16";
BA_ "NetworkRequestHoldingTime" SG_ 1825 GST_PSS_3RD_Byte7 5000;
BA_ "NetworkRequest" SG_ 1825 GST_PSS_3RD_Byte7 0;
BA_ "UserSigValidity" SG_ 1825 GST_PSS_3RD_Byte7 0;
BA_ "UsrSigPurpose" SG_ 1825 GST_PSS_3RD_Byte7 3;
BA_ "Description" SG_ 1825 GST_PSS_3RD_Byte7 "TP Index : 153";
BA_ "Version" SG_ 1825 GST_PSS_3RD_Byte1 "22.10.16";
BA_ "NetworkRequestHoldingTime" SG_ 1825 GST_PSS_3RD_Byte1 5000;
BA_ "NetworkRequest" SG_ 1825 GST_PSS_3RD_Byte1 0;
BA_ "UserSigValidity" SG_ 1825 GST_PSS_3RD_Byte1 0;
BA_ "UsrSigPurpose" SG_ 1825 GST_PSS_3RD_Byte1 3;
BA_ "Description" SG_ 1825 GST_PSS_3RD_Byte1 "TP Index : 153";
BA_ "Version" SG_ 1827 GST_WPC2_Byte0 "22.02.06";
BA_ "NetworkRequestHoldingTime" SG_ 1827 GST_WPC2_Byte0 5000;
BA_ "NetworkRequest" SG_ 1827 GST_WPC2_Byte0 0;
BA_ "UserSigValidity" SG_ 1827 GST_WPC2_Byte0 0;
BA_ "UsrSigPurpose" SG_ 1827 GST_WPC2_Byte0 3;
BA_ "Description" SG_ 1827 GST_WPC2_Byte0 "TP Index : 252";
BA_ "Version" SG_ 1827 GST_WPC2_Byte2 "22.02.06";
BA_ "NetworkRequestHoldingTime" SG_ 1827 GST_WPC2_Byte2 5000;
BA_ "NetworkRequest" SG_ 1827 GST_WPC2_Byte2 0;
BA_ "UserSigValidity" SG_ 1827 GST_WPC2_Byte2 0;
BA_ "UsrSigPurpose" SG_ 1827 GST_WPC2_Byte2 3;
BA_ "Description" SG_ 1827 GST_WPC2_Byte2 "TP Index : 252";
BA_ "Version" SG_ 1827 GST_WPC2_Byte3 "22.02.06";
BA_ "NetworkRequestHoldingTime" SG_ 1827 GST_WPC2_Byte3 5000;
BA_ "NetworkRequest" SG_ 1827 GST_WPC2_Byte3 0;
BA_ "UserSigValidity" SG_ 1827 GST_WPC2_Byte3 0;
BA_ "UsrSigPurpose" SG_ 1827 GST_WPC2_Byte3 3;
BA_ "Description" SG_ 1827 GST_WPC2_Byte3 "TP Index : 252";
BA_ "Version" SG_ 1827 GST_WPC2_Byte4 "22.02.06";
BA_ "NetworkRequestHoldingTime" SG_ 1827 GST_WPC2_Byte4 5000;
BA_ "NetworkRequest" SG_ 1827 GST_WPC2_Byte4 0;
BA_ "UserSigValidity" SG_ 1827 GST_WPC2_Byte4 0;
BA_ "UsrSigPurpose" SG_ 1827 GST_WPC2_Byte4 3;
BA_ "Description" SG_ 1827 GST_WPC2_Byte4 "TP Index : 252";
BA_ "Version" SG_ 1827 GST_WPC2_Byte5 "22.02.06";
BA_ "NetworkRequestHoldingTime" SG_ 1827 GST_WPC2_Byte5 5000;
BA_ "NetworkRequest" SG_ 1827 GST_WPC2_Byte5 0;
BA_ "UserSigValidity" SG_ 1827 GST_WPC2_Byte5 0;
BA_ "UsrSigPurpose" SG_ 1827 GST_WPC2_Byte5 3;
BA_ "Description" SG_ 1827 GST_WPC2_Byte5 "TP Index : 252";
BA_ "Version" SG_ 1827 GST_WPC2_Byte6 "22.02.06";
BA_ "NetworkRequestHoldingTime" SG_ 1827 GST_WPC2_Byte6 5000;
BA_ "NetworkRequest" SG_ 1827 GST_WPC2_Byte6 0;
BA_ "UserSigValidity" SG_ 1827 GST_WPC2_Byte6 0;
BA_ "UsrSigPurpose" SG_ 1827 GST_WPC2_Byte6 3;
BA_ "Description" SG_ 1827 GST_WPC2_Byte6 "TP Index : 252";
BA_ "Version" SG_ 1827 GST_WPC2_Byte7 "22.02.06";
BA_ "NetworkRequestHoldingTime" SG_ 1827 GST_WPC2_Byte7 5000;
BA_ "NetworkRequest" SG_ 1827 GST_WPC2_Byte7 0;
BA_ "UserSigValidity" SG_ 1827 GST_WPC2_Byte7 0;
BA_ "UsrSigPurpose" SG_ 1827 GST_WPC2_Byte7 3;
BA_ "Description" SG_ 1827 GST_WPC2_Byte7 "TP Index : 252";
BA_ "Version" SG_ 1827 GST_WPC2_Byte1 "22.02.06";
BA_ "NetworkRequestHoldingTime" SG_ 1827 GST_WPC2_Byte1 5000;
BA_ "NetworkRequest" SG_ 1827 GST_WPC2_Byte1 0;
BA_ "UserSigValidity" SG_ 1827 GST_WPC2_Byte1 0;
BA_ "UsrSigPurpose" SG_ 1827 GST_WPC2_Byte1 3;
BA_ "Description" SG_ 1827 GST_WPC2_Byte1 "TP Index : 252";
BA_ "Version" SG_ 1818 RLHVU_GST_Byte0 "22.07.01";
BA_ "NetworkRequestHoldingTime" SG_ 1818 RLHVU_GST_Byte0 5000;
BA_ "NetworkRequest" SG_ 1818 RLHVU_GST_Byte0 0;
BA_ "UserSigValidity" SG_ 1818 RLHVU_GST_Byte0 0;
BA_ "UsrSigPurpose" SG_ 1818 RLHVU_GST_Byte0 4;
BA_ "Description" SG_ 1818 RLHVU_GST_Byte0 "TP Index : 160";
BA_ "Version" SG_ 1818 RLHVU_GST_Byte2 "22.07.01";
BA_ "NetworkRequestHoldingTime" SG_ 1818 RLHVU_GST_Byte2 5000;
BA_ "NetworkRequest" SG_ 1818 RLHVU_GST_Byte2 0;
BA_ "UserSigValidity" SG_ 1818 RLHVU_GST_Byte2 0;
BA_ "UsrSigPurpose" SG_ 1818 RLHVU_GST_Byte2 4;
BA_ "Description" SG_ 1818 RLHVU_GST_Byte2 "TP Index : 160";
BA_ "Version" SG_ 1818 RLHVU_GST_Byte3 "22.07.01";
BA_ "NetworkRequestHoldingTime" SG_ 1818 RLHVU_GST_Byte3 5000;
BA_ "NetworkRequest" SG_ 1818 RLHVU_GST_Byte3 0;
BA_ "UserSigValidity" SG_ 1818 RLHVU_GST_Byte3 0;
BA_ "UsrSigPurpose" SG_ 1818 RLHVU_GST_Byte3 4;
BA_ "Description" SG_ 1818 RLHVU_GST_Byte3 "TP Index : 160";
BA_ "Version" SG_ 1818 RLHVU_GST_Byte4 "22.07.01";
BA_ "NetworkRequestHoldingTime" SG_ 1818 RLHVU_GST_Byte4 5000;
BA_ "NetworkRequest" SG_ 1818 RLHVU_GST_Byte4 0;
BA_ "UserSigValidity" SG_ 1818 RLHVU_GST_Byte4 0;
BA_ "UsrSigPurpose" SG_ 1818 RLHVU_GST_Byte4 4;
BA_ "Description" SG_ 1818 RLHVU_GST_Byte4 "TP Index : 160";
BA_ "Version" SG_ 1818 RLHVU_GST_Byte5 "22.07.01";
BA_ "NetworkRequestHoldingTime" SG_ 1818 RLHVU_GST_Byte5 5000;
BA_ "NetworkRequest" SG_ 1818 RLHVU_GST_Byte5 0;
BA_ "UserSigValidity" SG_ 1818 RLHVU_GST_Byte5 0;
BA_ "UsrSigPurpose" SG_ 1818 RLHVU_GST_Byte5 4;
BA_ "Description" SG_ 1818 RLHVU_GST_Byte5 "TP Index : 160";
BA_ "Version" SG_ 1818 RLHVU_GST_Byte6 "22.07.01";
BA_ "NetworkRequestHoldingTime" SG_ 1818 RLHVU_GST_Byte6 5000;
BA_ "NetworkRequest" SG_ 1818 RLHVU_GST_Byte6 0;
BA_ "UserSigValidity" SG_ 1818 RLHVU_GST_Byte6 0;
BA_ "UsrSigPurpose" SG_ 1818 RLHVU_GST_Byte6 4;
BA_ "Description" SG_ 1818 RLHVU_GST_Byte6 "TP Index : 160";
BA_ "Version" SG_ 1818 RLHVU_GST_Byte7 "22.07.01";
BA_ "NetworkRequestHoldingTime" SG_ 1818 RLHVU_GST_Byte7 5000;
BA_ "NetworkRequest" SG_ 1818 RLHVU_GST_Byte7 0;
BA_ "UserSigValidity" SG_ 1818 RLHVU_GST_Byte7 0;
BA_ "UsrSigPurpose" SG_ 1818 RLHVU_GST_Byte7 4;
BA_ "Description" SG_ 1818 RLHVU_GST_Byte7 "TP Index : 160";
BA_ "Version" SG_ 1818 RLHVU_GST_Byte1 "22.07.01";
BA_ "NetworkRequestHoldingTime" SG_ 1818 RLHVU_GST_Byte1 5000;
BA_ "NetworkRequest" SG_ 1818 RLHVU_GST_Byte1 0;
BA_ "UserSigValidity" SG_ 1818 RLHVU_GST_Byte1 0;
BA_ "UsrSigPurpose" SG_ 1818 RLHVU_GST_Byte1 4;
BA_ "Description" SG_ 1818 RLHVU_GST_Byte1 "TP Index : 160";
BA_ "Version" SG_ 858 SBCM_AST_Crc2Val "21.09.03";
BA_ "UserSigValidity" SG_ 858 SBCM_AST_Crc2Val 0;
BA_ "GenSigSendType" SG_ 858 SBCM_AST_Crc2Val 4;
BA_ "Description" SG_ 858 SBCM_AST_Crc2Val "The data area for CRC calculation is based on the data length (DLC) of the message DB.

The CRC shall be calculated over the entire data block (excluding the CRC bytes) including the user data, alive counter and Data ID 

 

- CRC Polynomial (0x1D) , Ini";
BA_ "Version" SG_ 858 AST_CrashUnlockCmd "21.07.07";
BA_ "NetworkRequest" SG_ 858 AST_CrashUnlockCmd 0;
BA_ "UserSigValidity" SG_ 858 AST_CrashUnlockCmd 0;
BA_ "GenSigSendType" SG_ 858 AST_CrashUnlockCmd 4;
BA_ "Description" SG_ 858 AST_CrashUnlockCmd "Assist Crash Unlock Command";
BA_ "Version" SG_ 858 SBCM_AST_AlvCnt2Val "21.09.03";
BA_ "UserSigValidity" SG_ 858 SBCM_AST_AlvCnt2Val 0;
BA_ "GenSigSendType" SG_ 858 SBCM_AST_AlvCnt2Val 4;
BA_ "Description" SG_ 858 SBCM_AST_AlvCnt2Val "For the first transmission request for a data element the counter shall be initialized with 0 and shall be incremented by 1

for every subsequent send request. When the counter reaches the maximum value(0xE), then it shall restart with 0 for the next sen";
BA_ "Version" SG_ 858 DoorLock_CtrlDrLkSwSta_SBCM "21.07.07";
BA_ "NetworkRequest" SG_ 858 DoorLock_CtrlDrLkSwSta_SBCM 0;
BA_ "UserSigValidity" SG_ 858 DoorLock_CtrlDrLkSwSta_SBCM 0;
BA_ "GenSigSendType" SG_ 858 DoorLock_CtrlDrLkSwSta_SBCM 4;
BA_ "Description" SG_ 858 DoorLock_CtrlDrLkSwSta_SBCM "Central Door Lock Assist Switch Status";
BA_ "Version" SG_ 858 DoorLock_CtrlDrUnLkSwSta_SBCM "21.07.07";
BA_ "NetworkRequest" SG_ 858 DoorLock_CtrlDrUnLkSwSta_SBCM 0;
BA_ "UserSigValidity" SG_ 858 DoorLock_CtrlDrUnLkSwSta_SBCM 0;
BA_ "GenSigSendType" SG_ 858 DoorLock_CtrlDrUnLkSwSta_SBCM 4;
BA_ "Description" SG_ 858 DoorLock_CtrlDrUnLkSwSta_SBCM "Central Door Unlock Assist Switch Status";
BA_ "Version" SG_ 858 Warn_AsstDrSwSta_SBCM "21.09.05";
BA_ "NetworkRequest" SG_ 858 Warn_AsstDrSwSta_SBCM 0;
BA_ "UserSigValidity" SG_ 858 Warn_AsstDrSwSta_SBCM 0;
BA_ "GenSigSendType" SG_ 858 Warn_AsstDrSwSta_SBCM 4;
BA_ "Description" SG_ 858 Warn_AsstDrSwSta_SBCM "Warning Assist Door Switch Status";
BA_ "Version" SG_ 858 DoorLock_AsstDrUnLkSta_SBCM "21.07.07";
BA_ "NetworkRequest" SG_ 858 DoorLock_AsstDrUnLkSta_SBCM 0;
BA_ "UserSigValidity" SG_ 858 DoorLock_AsstDrUnLkSta_SBCM 0;
BA_ "GenSigSendType" SG_ 858 DoorLock_AsstDrUnLkSta_SBCM 4;
BA_ "Description" SG_ 858 DoorLock_AsstDrUnLkSta_SBCM "Assist Door Unlock Status";
BA_ "Version" SG_ 858 AST_SEAWarn_RH "21.07.07";
BA_ "NetworkRequest" SG_ 858 AST_SEAWarn_RH 0;
BA_ "UserSigValidity" SG_ 858 AST_SEAWarn_RH 0;
BA_ "GenSigSendType" SG_ 858 AST_SEAWarn_RH 4;
BA_ "Description" SG_ 858 AST_SEAWarn_RH "Assist (FRH) SEA Warning";
BA_ "Version" SG_ 858 AST_SEAWarn_LH "21.07.07";
BA_ "NetworkRequest" SG_ 858 AST_SEAWarn_LH 0;
BA_ "UserSigValidity" SG_ 858 AST_SEAWarn_LH 0;
BA_ "GenSigSendType" SG_ 858 AST_SEAWarn_LH 4;
BA_ "Description" SG_ 858 AST_SEAWarn_LH "Assist (FLH) Door SEA Warning";
BA_ "Version" SG_ 858 AST_SEWWarn_LH "21.07.07";
BA_ "NetworkRequest" SG_ 858 AST_SEWWarn_LH 0;
BA_ "UserSigValidity" SG_ 858 AST_SEWWarn_LH 0;
BA_ "GenSigSendType" SG_ 858 AST_SEWWarn_LH 4;
BA_ "Version" SG_ 858 AST_SEWWarn_RH "21.07.07";
BA_ "NetworkRequest" SG_ 858 AST_SEWWarn_RH 0;
BA_ "UserSigValidity" SG_ 858 AST_SEWWarn_RH 0;
BA_ "GenSigSendType" SG_ 858 AST_SEWWarn_RH 4;
BA_ "Version" SG_ 858 AST_MRActivationAlarm "21.07.07";
BA_ "NetworkRequestHoldingTime" SG_ 858 AST_MRActivationAlarm 5000;
BA_ "NetworkRequest" SG_ 858 AST_MRActivationAlarm 0;
BA_ "UserSigValidity" SG_ 858 AST_MRActivationAlarm 0;
BA_ "GenSigSendType" SG_ 858 AST_MRActivationAlarm 4;
BA_ "Version" SG_ 858 AST_ReleaseWarn "21.09.05";
BA_ "NetworkRequestHoldingTime" SG_ 858 AST_ReleaseWarn 5000;
BA_ "NetworkRequest" SG_ 858 AST_ReleaseWarn 0;
BA_ "UserSigValidity" SG_ 858 AST_ReleaseWarn 0;
BA_ "GenSigSendType" SG_ 858 AST_ReleaseWarn 4;
BA_ "Version" SG_ 858 USM_AstGhostDoorSta "21.07.07";
BA_ "NetworkRequestHoldingTime" SG_ 858 USM_AstGhostDoorSta 5000;
BA_ "NetworkRequest" SG_ 858 USM_AstGhostDoorSta 0;
BA_ "UserSigValidity" SG_ 858 USM_AstGhostDoorSta 0;
BA_ "GenSigSendType" SG_ 858 USM_AstGhostDoorSta 4;
BA_ "Version" SG_ 858 AST_SWFailAlarm "21.07.07";
BA_ "NetworkRequestHoldingTime" SG_ 858 AST_SWFailAlarm 5000;
BA_ "NetworkRequest" SG_ 858 AST_SWFailAlarm 0;
BA_ "UserSigValidity" SG_ 858 AST_SWFailAlarm 0;
BA_ "GenSigSendType" SG_ 858 AST_SWFailAlarm 4;
BA_ "Version" SG_ 858 DoorLock_PDSLkSwSta_AST "21.09.05";
BA_ "NetworkRequest" SG_ 858 DoorLock_PDSLkSwSta_AST 0;
BA_ "UserSigValidity" SG_ 858 DoorLock_PDSLkSwSta_AST 0;
BA_ "GenSigSendType" SG_ 858 DoorLock_PDSLkSwSta_AST 4;
BA_ "Version" SG_ 858 PDS_TypeOption_AST "21.07.07";
BA_ "NetworkRequest" SG_ 858 PDS_TypeOption_AST 0;
BA_ "UserSigValidity" SG_ 858 PDS_TypeOption_AST 0;
BA_ "GenSigSendType" SG_ 858 PDS_TypeOption_AST 4;
BA_ "Version" SG_ 858 AFCU_AutoWashModeSta_SBCM_AST "22.07.00";
BA_ "NetworkRequestHoldingTime" SG_ 858 AFCU_AutoWashModeSta_SBCM_AST 5000;
BA_ "NetworkRequest" SG_ 858 AFCU_AutoWashModeSta_SBCM_AST 0;
BA_ "UserSigValidity" SG_ 858 AFCU_AutoWashModeSta_SBCM_AST 0;
BA_ "GenSigSendType" SG_ 858 AFCU_AutoWashModeSta_SBCM_AST 4;
BA_ "Version" SG_ 858 CDM_AutoWashModeSta_SBCM_AST "22.07.00";
BA_ "NetworkRequestHoldingTime" SG_ 858 CDM_AutoWashModeSta_SBCM_AST 5000;
BA_ "NetworkRequest" SG_ 858 CDM_AutoWashModeSta_SBCM_AST 0;
BA_ "UserSigValidity" SG_ 858 CDM_AutoWashModeSta_SBCM_AST 0;
BA_ "GenSigSendType" SG_ 858 CDM_AutoWashModeSta_SBCM_AST 4;
BA_ "Version" SG_ 858 ASTDoorPushAlarm "21.07.07";
BA_ "NetworkRequestHoldingTime" SG_ 858 ASTDoorPushAlarm 5000;
BA_ "NetworkRequest" SG_ 858 ASTDoorPushAlarm 0;
BA_ "UserSigValidity" SG_ 858 ASTDoorPushAlarm 0;
BA_ "GenSigSendType" SG_ 858 ASTDoorPushAlarm 4;
BA_ "Version" SG_ 863 Ast_SHVU_DTCdisplay "22.05.04";
BA_ "NetworkRequestHoldingTime" SG_ 863 Ast_SHVU_DTCdisplay 5000;
BA_ "NetworkRequest" SG_ 863 Ast_SHVU_DTCdisplay 0;
BA_ "UserSigValidity" SG_ 863 Ast_SHVU_DTCdisplay 7;
BA_ "GenSigSendType" SG_ 863 Ast_SHVU_DTCdisplay 4;
BA_ "Description" SG_ 863 Ast_SHVU_DTCdisplay "This signal indicates DTC Code of Self-Diagnostic mode (Passenger Seat)";
BA_ "Version" SG_ 863 Ast_SHVU_DiagMode "22.05.04";
BA_ "NetworkRequestHoldingTime" SG_ 863 Ast_SHVU_DiagMode 5000;
BA_ "NetworkRequest" SG_ 863 Ast_SHVU_DiagMode 0;
BA_ "UserSigValidity" SG_ 863 Ast_SHVU_DiagMode 7;
BA_ "GenSigSendType" SG_ 863 Ast_SHVU_DiagMode 4;
BA_ "Description" SG_ 863 Ast_SHVU_DiagMode "This signal indicates operating mode of SHVU (Self-Diagnostic mode or normal mode)";
BA_ "Version" SG_ 862 SBCM_RL_Crc1Val "21.09.03";
BA_ "UserSigValidity" SG_ 862 SBCM_RL_Crc1Val 0;
BA_ "GenSigSendType" SG_ 862 SBCM_RL_Crc1Val 4;
BA_ "Description" SG_ 862 SBCM_RL_Crc1Val "The data area for CRC calculation is based on the data length (DLC) of the message DB.

The CRC shall be calculated over the entire data block (excluding the CRC bytes) including the user data, alive counter and Data ID 

 

- CRC Polynomial (0x1D) , Ini";
BA_ "Version" SG_ 862 RL_CrashUnlockCmd "21.07.07";
BA_ "NetworkRequest" SG_ 862 RL_CrashUnlockCmd 0;
BA_ "UserSigValidity" SG_ 862 RL_CrashUnlockCmd 0;
BA_ "GenSigSendType" SG_ 862 RL_CrashUnlockCmd 4;
BA_ "Description" SG_ 862 RL_CrashUnlockCmd "RearLefrCrashUnlockCommand";
BA_ "Version" SG_ 862 SBCM_RL_AlvCnt1Val "21.09.03";
BA_ "UserSigValidity" SG_ 862 SBCM_RL_AlvCnt1Val 0;
BA_ "GenSigSendType" SG_ 862 SBCM_RL_AlvCnt1Val 4;
BA_ "Description" SG_ 862 SBCM_RL_AlvCnt1Val "For the first transmission request for a data element the counter shall be initialized with 0 and shall be incremented by 1

for every subsequent send request. When the counter reaches the maximum value(0xE), then it shall restart with 0 for the next sen";
BA_ "Version" SG_ 862 Warn_RrLftDrSwSta_SBCM "21.09.05";
BA_ "NetworkRequest" SG_ 862 Warn_RrLftDrSwSta_SBCM 0;
BA_ "UserSigValidity" SG_ 862 Warn_RrLftDrSwSta_SBCM 0;
BA_ "GenSigSendType" SG_ 862 Warn_RrLftDrSwSta_SBCM 4;
BA_ "Description" SG_ 862 Warn_RrLftDrSwSta_SBCM "Warning Rear Left Door Switch Status";
BA_ "Version" SG_ 862 DoorLock_RrLftDrUnLkSta_SBCM "21.07.07";
BA_ "NetworkRequest" SG_ 862 DoorLock_RrLftDrUnLkSta_SBCM 0;
BA_ "UserSigValidity" SG_ 862 DoorLock_RrLftDrUnLkSta_SBCM 0;
BA_ "GenSigSendType" SG_ 862 DoorLock_RrLftDrUnLkSta_SBCM 4;
BA_ "Description" SG_ 862 DoorLock_RrLftDrUnLkSta_SBCM "Rear Left Door Unlock Status";
BA_ "Version" SG_ 862 RL_SEAActivated "21.07.07";
BA_ "NetworkRequest" SG_ 862 RL_SEAActivated 0;
BA_ "UserSigValidity" SG_ 862 RL_SEAActivated 0;
BA_ "GenSigSendType" SG_ 862 RL_SEAActivated 4;
BA_ "Description" SG_ 862 RL_SEAActivated "Rear Left SEA Activated";
BA_ "Version" SG_ 862 RL_SEAWarn "21.07.07";
BA_ "NetworkRequest" SG_ 862 RL_SEAWarn 0;
BA_ "UserSigValidity" SG_ 862 RL_SEAWarn 0;
BA_ "GenSigSendType" SG_ 862 RL_SEAWarn 4;
BA_ "Description" SG_ 862 RL_SEAWarn "RearLeftSEAWarning";
BA_ "Version" SG_ 862 RL_SEWWarn "21.07.07";
BA_ "NetworkRequest" SG_ 862 RL_SEWWarn 0;
BA_ "UserSigValidity" SG_ 862 RL_SEWWarn 0;
BA_ "GenSigSendType" SG_ 862 RL_SEWWarn 4;
BA_ "Version" SG_ 862 RL_ReleaseWarn "21.09.05";
BA_ "NetworkRequestHoldingTime" SG_ 862 RL_ReleaseWarn 5000;
BA_ "NetworkRequest" SG_ 862 RL_ReleaseWarn 0;
BA_ "UserSigValidity" SG_ 862 RL_ReleaseWarn 0;
BA_ "GenSigSendType" SG_ 862 RL_ReleaseWarn 4;
BA_ "Version" SG_ 862 RL_SWFailAlarm "21.07.07";
BA_ "NetworkRequestHoldingTime" SG_ 862 RL_SWFailAlarm 5000;
BA_ "NetworkRequest" SG_ 862 RL_SWFailAlarm 0;
BA_ "UserSigValidity" SG_ 862 RL_SWFailAlarm 0;
BA_ "GenSigSendType" SG_ 862 RL_SWFailAlarm 4;
BA_ "Version" SG_ 862 RL_ChildLock_ActnFlSta "21.07.07";
BA_ "NetworkRequestHoldingTime" SG_ 862 RL_ChildLock_ActnFlSta 5000;
BA_ "NetworkRequest" SG_ 862 RL_ChildLock_ActnFlSta 0;
BA_ "UserSigValidity" SG_ 862 RL_ChildLock_ActnFlSta 0;
BA_ "GenSigSendType" SG_ 862 RL_ChildLock_ActnFlSta 4;
BA_ "Version" SG_ 862 RL_MRActivationAlarm "21.07.07";
BA_ "NetworkRequestHoldingTime" SG_ 862 RL_MRActivationAlarm 5000;
BA_ "NetworkRequest" SG_ 862 RL_MRActivationAlarm 0;
BA_ "UserSigValidity" SG_ 862 RL_MRActivationAlarm 0;
BA_ "GenSigSendType" SG_ 862 RL_MRActivationAlarm 4;
BA_ "Version" SG_ 862 RL_ChildLock_Status "21.07.07";
BA_ "NetworkRequestHoldingTime" SG_ 862 RL_ChildLock_Status 5000;
BA_ "NetworkRequest" SG_ 862 RL_ChildLock_Status 0;
BA_ "UserSigValidity" SG_ 862 RL_ChildLock_Status 0;
BA_ "GenSigSendType" SG_ 862 RL_ChildLock_Status 4;
BA_ "Version" SG_ 862 USM_RLGhostDoorSta "21.07.07";
BA_ "NetworkRequestHoldingTime" SG_ 862 USM_RLGhostDoorSta 5000;
BA_ "NetworkRequest" SG_ 862 USM_RLGhostDoorSta 0;
BA_ "UserSigValidity" SG_ 862 USM_RLGhostDoorSta 0;
BA_ "GenSigSendType" SG_ 862 USM_RLGhostDoorSta 4;
BA_ "Version" SG_ 862 DoorLock_PDSLkSwSta_RL "21.09.05";
BA_ "NetworkRequest" SG_ 862 DoorLock_PDSLkSwSta_RL 0;
BA_ "UserSigValidity" SG_ 862 DoorLock_PDSLkSwSta_RL 0;
BA_ "GenSigSendType" SG_ 862 DoorLock_PDSLkSwSta_RL 4;
BA_ "Version" SG_ 862 PDS_TypeOption_RL "21.07.07";
BA_ "NetworkRequest" SG_ 862 PDS_TypeOption_RL 0;
BA_ "UserSigValidity" SG_ 862 PDS_TypeOption_RL 0;
BA_ "GenSigSendType" SG_ 862 PDS_TypeOption_RL 4;
BA_ "Version" SG_ 862 RLDoorPushAlarm "21.07.07";
BA_ "NetworkRequestHoldingTime" SG_ 862 RLDoorPushAlarm 5000;
BA_ "NetworkRequest" SG_ 862 RLDoorPushAlarm 0;
BA_ "UserSigValidity" SG_ 862 RLDoorPushAlarm 0;
BA_ "GenSigSendType" SG_ 862 RLDoorPushAlarm 4;
BA_ "Version" SG_ 1810 GST_RLHVU_Byte0 "21.02.04";
BA_ "NetworkRequestHoldingTime" SG_ 1810 GST_RLHVU_Byte0 5000;
BA_ "NetworkRequest" SG_ 1810 GST_RLHVU_Byte0 0;
BA_ "UserSigValidity" SG_ 1810 GST_RLHVU_Byte0 0;
BA_ "UsrSigPurpose" SG_ 1810 GST_RLHVU_Byte0 3;
BA_ "Description" SG_ 1810 GST_RLHVU_Byte0 "TP Index : 160";
BA_ "Version" SG_ 1810 GST_RLHVU_Byte2 "21.02.04";
BA_ "NetworkRequestHoldingTime" SG_ 1810 GST_RLHVU_Byte2 5000;
BA_ "NetworkRequest" SG_ 1810 GST_RLHVU_Byte2 0;
BA_ "UserSigValidity" SG_ 1810 GST_RLHVU_Byte2 0;
BA_ "UsrSigPurpose" SG_ 1810 GST_RLHVU_Byte2 3;
BA_ "Description" SG_ 1810 GST_RLHVU_Byte2 "TP Index : 160";
BA_ "Version" SG_ 1810 GST_RLHVU_Byte3 "21.02.04";
BA_ "NetworkRequestHoldingTime" SG_ 1810 GST_RLHVU_Byte3 5000;
BA_ "NetworkRequest" SG_ 1810 GST_RLHVU_Byte3 0;
BA_ "UserSigValidity" SG_ 1810 GST_RLHVU_Byte3 0;
BA_ "UsrSigPurpose" SG_ 1810 GST_RLHVU_Byte3 3;
BA_ "Description" SG_ 1810 GST_RLHVU_Byte3 "TP Index : 160";
BA_ "Version" SG_ 1810 GST_RLHVU_Byte4 "21.02.04";
BA_ "NetworkRequestHoldingTime" SG_ 1810 GST_RLHVU_Byte4 5000;
BA_ "NetworkRequest" SG_ 1810 GST_RLHVU_Byte4 0;
BA_ "UserSigValidity" SG_ 1810 GST_RLHVU_Byte4 0;
BA_ "UsrSigPurpose" SG_ 1810 GST_RLHVU_Byte4 3;
BA_ "Description" SG_ 1810 GST_RLHVU_Byte4 "TP Index : 160";
BA_ "Version" SG_ 1810 GST_RLHVU_Byte5 "21.02.04";
BA_ "NetworkRequestHoldingTime" SG_ 1810 GST_RLHVU_Byte5 5000;
BA_ "NetworkRequest" SG_ 1810 GST_RLHVU_Byte5 0;
BA_ "UserSigValidity" SG_ 1810 GST_RLHVU_Byte5 0;
BA_ "UsrSigPurpose" SG_ 1810 GST_RLHVU_Byte5 3;
BA_ "Description" SG_ 1810 GST_RLHVU_Byte5 "TP Index : 160";
BA_ "Version" SG_ 1810 GST_RLHVU_Byte6 "21.02.04";
BA_ "NetworkRequestHoldingTime" SG_ 1810 GST_RLHVU_Byte6 5000;
BA_ "NetworkRequest" SG_ 1810 GST_RLHVU_Byte6 0;
BA_ "UserSigValidity" SG_ 1810 GST_RLHVU_Byte6 0;
BA_ "UsrSigPurpose" SG_ 1810 GST_RLHVU_Byte6 3;
BA_ "Description" SG_ 1810 GST_RLHVU_Byte6 "TP Index : 160";
BA_ "Version" SG_ 1810 GST_RLHVU_Byte7 "21.02.04";
BA_ "NetworkRequestHoldingTime" SG_ 1810 GST_RLHVU_Byte7 5000;
BA_ "NetworkRequest" SG_ 1810 GST_RLHVU_Byte7 0;
BA_ "UserSigValidity" SG_ 1810 GST_RLHVU_Byte7 0;
BA_ "UsrSigPurpose" SG_ 1810 GST_RLHVU_Byte7 3;
BA_ "Description" SG_ 1810 GST_RLHVU_Byte7 "TP Index : 160";
BA_ "Version" SG_ 1810 GST_RLHVU_Byte1 "21.02.04";
BA_ "NetworkRequestHoldingTime" SG_ 1810 GST_RLHVU_Byte1 5000;
BA_ "NetworkRequest" SG_ 1810 GST_RLHVU_Byte1 0;
BA_ "UserSigValidity" SG_ 1810 GST_RLHVU_Byte1 0;
BA_ "UsrSigPurpose" SG_ 1810 GST_RLHVU_Byte1 3;
BA_ "Description" SG_ 1810 GST_RLHVU_Byte1 "TP Index : 160";
BA_ "Version" SG_ 1806 AHV_SHVU_FR_GST_Byte0 "22.07.01";
BA_ "NetworkRequestHoldingTime" SG_ 1806 AHV_SHVU_FR_GST_Byte0 5000;
BA_ "NetworkRequest" SG_ 1806 AHV_SHVU_FR_GST_Byte0 0;
BA_ "UserSigValidity" SG_ 1806 AHV_SHVU_FR_GST_Byte0 0;
BA_ "UsrSigPurpose" SG_ 1806 AHV_SHVU_FR_GST_Byte0 4;
BA_ "Description" SG_ 1806 AHV_SHVU_FR_GST_Byte0 "TP Index : 106";
BA_ "Version" SG_ 1806 AHV_SHVU_FR_GST_Byte2 "22.07.01";
BA_ "NetworkRequestHoldingTime" SG_ 1806 AHV_SHVU_FR_GST_Byte2 5000;
BA_ "NetworkRequest" SG_ 1806 AHV_SHVU_FR_GST_Byte2 0;
BA_ "UserSigValidity" SG_ 1806 AHV_SHVU_FR_GST_Byte2 0;
BA_ "UsrSigPurpose" SG_ 1806 AHV_SHVU_FR_GST_Byte2 4;
BA_ "Description" SG_ 1806 AHV_SHVU_FR_GST_Byte2 "TP Index : 106";
BA_ "Version" SG_ 1806 AHV_SHVU_FR_GST_Byte3 "22.07.01";
BA_ "NetworkRequestHoldingTime" SG_ 1806 AHV_SHVU_FR_GST_Byte3 5000;
BA_ "NetworkRequest" SG_ 1806 AHV_SHVU_FR_GST_Byte3 0;
BA_ "UserSigValidity" SG_ 1806 AHV_SHVU_FR_GST_Byte3 0;
BA_ "UsrSigPurpose" SG_ 1806 AHV_SHVU_FR_GST_Byte3 4;
BA_ "Description" SG_ 1806 AHV_SHVU_FR_GST_Byte3 "TP Index : 106";
BA_ "Version" SG_ 1806 AHV_SHVU_FR_GST_Byte4 "22.07.01";
BA_ "NetworkRequestHoldingTime" SG_ 1806 AHV_SHVU_FR_GST_Byte4 5000;
BA_ "NetworkRequest" SG_ 1806 AHV_SHVU_FR_GST_Byte4 0;
BA_ "UserSigValidity" SG_ 1806 AHV_SHVU_FR_GST_Byte4 0;
BA_ "UsrSigPurpose" SG_ 1806 AHV_SHVU_FR_GST_Byte4 4;
BA_ "Description" SG_ 1806 AHV_SHVU_FR_GST_Byte4 "TP Index : 106";
BA_ "Version" SG_ 1806 AHV_SHVU_FR_GST_Byte5 "22.07.01";
BA_ "NetworkRequestHoldingTime" SG_ 1806 AHV_SHVU_FR_GST_Byte5 5000;
BA_ "NetworkRequest" SG_ 1806 AHV_SHVU_FR_GST_Byte5 0;
BA_ "UserSigValidity" SG_ 1806 AHV_SHVU_FR_GST_Byte5 0;
BA_ "UsrSigPurpose" SG_ 1806 AHV_SHVU_FR_GST_Byte5 4;
BA_ "Description" SG_ 1806 AHV_SHVU_FR_GST_Byte5 "TP Index : 106";
BA_ "Version" SG_ 1806 AHV_SHVU_FR_GST_Byte6 "22.07.01";
BA_ "NetworkRequestHoldingTime" SG_ 1806 AHV_SHVU_FR_GST_Byte6 5000;
BA_ "NetworkRequest" SG_ 1806 AHV_SHVU_FR_GST_Byte6 0;
BA_ "UserSigValidity" SG_ 1806 AHV_SHVU_FR_GST_Byte6 0;
BA_ "UsrSigPurpose" SG_ 1806 AHV_SHVU_FR_GST_Byte6 4;
BA_ "Description" SG_ 1806 AHV_SHVU_FR_GST_Byte6 "TP Index : 106";
BA_ "Version" SG_ 1806 AHV_SHVU_FR_GST_Byte7 "22.07.01";
BA_ "NetworkRequestHoldingTime" SG_ 1806 AHV_SHVU_FR_GST_Byte7 5000;
BA_ "NetworkRequest" SG_ 1806 AHV_SHVU_FR_GST_Byte7 0;
BA_ "UserSigValidity" SG_ 1806 AHV_SHVU_FR_GST_Byte7 0;
BA_ "UsrSigPurpose" SG_ 1806 AHV_SHVU_FR_GST_Byte7 4;
BA_ "Description" SG_ 1806 AHV_SHVU_FR_GST_Byte7 "TP Index : 106";
BA_ "Version" SG_ 1806 AHV_SHVU_FR_GST_Byte1 "22.07.01";
BA_ "NetworkRequestHoldingTime" SG_ 1806 AHV_SHVU_FR_GST_Byte1 5000;
BA_ "NetworkRequest" SG_ 1806 AHV_SHVU_FR_GST_Byte1 0;
BA_ "UserSigValidity" SG_ 1806 AHV_SHVU_FR_GST_Byte1 0;
BA_ "UsrSigPurpose" SG_ 1806 AHV_SHVU_FR_GST_Byte1 4;
BA_ "Description" SG_ 1806 AHV_SHVU_FR_GST_Byte1 "TP Index : 106";
BA_ "Version" SG_ 1807 RRHVU_GST_Byte0 "22.07.01";
BA_ "NetworkRequestHoldingTime" SG_ 1807 RRHVU_GST_Byte0 5000;
BA_ "NetworkRequest" SG_ 1807 RRHVU_GST_Byte0 0;
BA_ "UserSigValidity" SG_ 1807 RRHVU_GST_Byte0 0;
BA_ "UsrSigPurpose" SG_ 1807 RRHVU_GST_Byte0 4;
BA_ "Description" SG_ 1807 RRHVU_GST_Byte0 "TP Index : 165";
BA_ "Version" SG_ 1807 RRHVU_GST_Byte2 "22.07.01";
BA_ "NetworkRequestHoldingTime" SG_ 1807 RRHVU_GST_Byte2 5000;
BA_ "NetworkRequest" SG_ 1807 RRHVU_GST_Byte2 0;
BA_ "UserSigValidity" SG_ 1807 RRHVU_GST_Byte2 0;
BA_ "UsrSigPurpose" SG_ 1807 RRHVU_GST_Byte2 4;
BA_ "Description" SG_ 1807 RRHVU_GST_Byte2 "TP Index : 165";
BA_ "Version" SG_ 1807 RRHVU_GST_Byte3 "22.07.01";
BA_ "NetworkRequestHoldingTime" SG_ 1807 RRHVU_GST_Byte3 5000;
BA_ "NetworkRequest" SG_ 1807 RRHVU_GST_Byte3 0;
BA_ "UserSigValidity" SG_ 1807 RRHVU_GST_Byte3 0;
BA_ "UsrSigPurpose" SG_ 1807 RRHVU_GST_Byte3 4;
BA_ "Description" SG_ 1807 RRHVU_GST_Byte3 "TP Index : 165";
BA_ "Version" SG_ 1807 RRHVU_GST_Byte4 "22.07.01";
BA_ "NetworkRequestHoldingTime" SG_ 1807 RRHVU_GST_Byte4 5000;
BA_ "NetworkRequest" SG_ 1807 RRHVU_GST_Byte4 0;
BA_ "UserSigValidity" SG_ 1807 RRHVU_GST_Byte4 0;
BA_ "UsrSigPurpose" SG_ 1807 RRHVU_GST_Byte4 4;
BA_ "Description" SG_ 1807 RRHVU_GST_Byte4 "TP Index : 165";
BA_ "Version" SG_ 1807 RRHVU_GST_Byte5 "22.07.01";
BA_ "NetworkRequestHoldingTime" SG_ 1807 RRHVU_GST_Byte5 5000;
BA_ "NetworkRequest" SG_ 1807 RRHVU_GST_Byte5 0;
BA_ "UserSigValidity" SG_ 1807 RRHVU_GST_Byte5 0;
BA_ "UsrSigPurpose" SG_ 1807 RRHVU_GST_Byte5 4;
BA_ "Description" SG_ 1807 RRHVU_GST_Byte5 "TP Index : 165";
BA_ "Version" SG_ 1807 RRHVU_GST_Byte6 "22.07.01";
BA_ "NetworkRequestHoldingTime" SG_ 1807 RRHVU_GST_Byte6 5000;
BA_ "NetworkRequest" SG_ 1807 RRHVU_GST_Byte6 0;
BA_ "UserSigValidity" SG_ 1807 RRHVU_GST_Byte6 0;
BA_ "UsrSigPurpose" SG_ 1807 RRHVU_GST_Byte6 4;
BA_ "Description" SG_ 1807 RRHVU_GST_Byte6 "TP Index : 165";
BA_ "Version" SG_ 1807 RRHVU_GST_Byte7 "22.07.01";
BA_ "NetworkRequestHoldingTime" SG_ 1807 RRHVU_GST_Byte7 5000;
BA_ "NetworkRequest" SG_ 1807 RRHVU_GST_Byte7 0;
BA_ "UserSigValidity" SG_ 1807 RRHVU_GST_Byte7 0;
BA_ "UsrSigPurpose" SG_ 1807 RRHVU_GST_Byte7 4;
BA_ "Description" SG_ 1807 RRHVU_GST_Byte7 "TP Index : 165";
BA_ "Version" SG_ 1807 RRHVU_GST_Byte1 "22.07.01";
BA_ "NetworkRequestHoldingTime" SG_ 1807 RRHVU_GST_Byte1 5000;
BA_ "NetworkRequest" SG_ 1807 RRHVU_GST_Byte1 0;
BA_ "UserSigValidity" SG_ 1807 RRHVU_GST_Byte1 0;
BA_ "UsrSigPurpose" SG_ 1807 RRHVU_GST_Byte1 4;
BA_ "Description" SG_ 1807 RRHVU_GST_Byte1 "TP Index : 165";
BA_ "Version" SG_ 1798 GST_AHV_SHVU_FR_Byte0 "21.02.04";
BA_ "NetworkRequestHoldingTime" SG_ 1798 GST_AHV_SHVU_FR_Byte0 5000;
BA_ "NetworkRequest" SG_ 1798 GST_AHV_SHVU_FR_Byte0 0;
BA_ "UserSigValidity" SG_ 1798 GST_AHV_SHVU_FR_Byte0 0;
BA_ "UsrSigPurpose" SG_ 1798 GST_AHV_SHVU_FR_Byte0 3;
BA_ "Description" SG_ 1798 GST_AHV_SHVU_FR_Byte0 "TP Index : 106";
BA_ "Version" SG_ 1798 GST_AHV_SHVU_FR_Byte2 "21.02.04";
BA_ "NetworkRequestHoldingTime" SG_ 1798 GST_AHV_SHVU_FR_Byte2 5000;
BA_ "NetworkRequest" SG_ 1798 GST_AHV_SHVU_FR_Byte2 0;
BA_ "UserSigValidity" SG_ 1798 GST_AHV_SHVU_FR_Byte2 0;
BA_ "UsrSigPurpose" SG_ 1798 GST_AHV_SHVU_FR_Byte2 3;
BA_ "Description" SG_ 1798 GST_AHV_SHVU_FR_Byte2 "TP Index : 106";
BA_ "Version" SG_ 1798 GST_AHV_SHVU_FR_Byte3 "21.02.04";
BA_ "NetworkRequestHoldingTime" SG_ 1798 GST_AHV_SHVU_FR_Byte3 5000;
BA_ "NetworkRequest" SG_ 1798 GST_AHV_SHVU_FR_Byte3 0;
BA_ "UserSigValidity" SG_ 1798 GST_AHV_SHVU_FR_Byte3 0;
BA_ "UsrSigPurpose" SG_ 1798 GST_AHV_SHVU_FR_Byte3 3;
BA_ "Description" SG_ 1798 GST_AHV_SHVU_FR_Byte3 "TP Index : 106";
BA_ "Version" SG_ 1798 GST_AHV_SHVU_FR_Byte4 "21.02.04";
BA_ "NetworkRequestHoldingTime" SG_ 1798 GST_AHV_SHVU_FR_Byte4 5000;
BA_ "NetworkRequest" SG_ 1798 GST_AHV_SHVU_FR_Byte4 0;
BA_ "UserSigValidity" SG_ 1798 GST_AHV_SHVU_FR_Byte4 0;
BA_ "UsrSigPurpose" SG_ 1798 GST_AHV_SHVU_FR_Byte4 3;
BA_ "Description" SG_ 1798 GST_AHV_SHVU_FR_Byte4 "TP Index : 106";
BA_ "Version" SG_ 1798 GST_AHV_SHVU_FR_Byte5 "21.02.04";
BA_ "NetworkRequestHoldingTime" SG_ 1798 GST_AHV_SHVU_FR_Byte5 5000;
BA_ "NetworkRequest" SG_ 1798 GST_AHV_SHVU_FR_Byte5 0;
BA_ "UserSigValidity" SG_ 1798 GST_AHV_SHVU_FR_Byte5 0;
BA_ "UsrSigPurpose" SG_ 1798 GST_AHV_SHVU_FR_Byte5 3;
BA_ "Description" SG_ 1798 GST_AHV_SHVU_FR_Byte5 "TP Index : 106";
BA_ "Version" SG_ 1798 GST_AHV_SHVU_FR_Byte6 "21.02.04";
BA_ "NetworkRequestHoldingTime" SG_ 1798 GST_AHV_SHVU_FR_Byte6 5000;
BA_ "NetworkRequest" SG_ 1798 GST_AHV_SHVU_FR_Byte6 0;
BA_ "UserSigValidity" SG_ 1798 GST_AHV_SHVU_FR_Byte6 0;
BA_ "UsrSigPurpose" SG_ 1798 GST_AHV_SHVU_FR_Byte6 3;
BA_ "Description" SG_ 1798 GST_AHV_SHVU_FR_Byte6 "TP Index : 106";
BA_ "Version" SG_ 1798 GST_AHV_SHVU_FR_Byte7 "21.02.04";
BA_ "NetworkRequestHoldingTime" SG_ 1798 GST_AHV_SHVU_FR_Byte7 5000;
BA_ "NetworkRequest" SG_ 1798 GST_AHV_SHVU_FR_Byte7 0;
BA_ "UserSigValidity" SG_ 1798 GST_AHV_SHVU_FR_Byte7 0;
BA_ "UsrSigPurpose" SG_ 1798 GST_AHV_SHVU_FR_Byte7 3;
BA_ "Description" SG_ 1798 GST_AHV_SHVU_FR_Byte7 "TP Index : 106";
BA_ "Version" SG_ 1798 GST_AHV_SHVU_FR_Byte1 "21.02.04";
BA_ "NetworkRequestHoldingTime" SG_ 1798 GST_AHV_SHVU_FR_Byte1 5000;
BA_ "NetworkRequest" SG_ 1798 GST_AHV_SHVU_FR_Byte1 0;
BA_ "UserSigValidity" SG_ 1798 GST_AHV_SHVU_FR_Byte1 0;
BA_ "UsrSigPurpose" SG_ 1798 GST_AHV_SHVU_FR_Byte1 3;
BA_ "Description" SG_ 1798 GST_AHV_SHVU_FR_Byte1 "TP Index : 106";
BA_ "Version" SG_ 1799 GST_RRHVU_Byte0 "21.02.04";
BA_ "NetworkRequestHoldingTime" SG_ 1799 GST_RRHVU_Byte0 5000;
BA_ "NetworkRequest" SG_ 1799 GST_RRHVU_Byte0 0;
BA_ "UserSigValidity" SG_ 1799 GST_RRHVU_Byte0 0;
BA_ "UsrSigPurpose" SG_ 1799 GST_RRHVU_Byte0 3;
BA_ "Description" SG_ 1799 GST_RRHVU_Byte0 "TP Index : 165";
BA_ "Version" SG_ 1799 GST_RRHVU_Byte2 "21.02.04";
BA_ "NetworkRequestHoldingTime" SG_ 1799 GST_RRHVU_Byte2 5000;
BA_ "NetworkRequest" SG_ 1799 GST_RRHVU_Byte2 0;
BA_ "UserSigValidity" SG_ 1799 GST_RRHVU_Byte2 0;
BA_ "UsrSigPurpose" SG_ 1799 GST_RRHVU_Byte2 3;
BA_ "Description" SG_ 1799 GST_RRHVU_Byte2 "TP Index : 165";
BA_ "Version" SG_ 1799 GST_RRHVU_Byte3 "21.02.04";
BA_ "NetworkRequestHoldingTime" SG_ 1799 GST_RRHVU_Byte3 5000;
BA_ "NetworkRequest" SG_ 1799 GST_RRHVU_Byte3 0;
BA_ "UserSigValidity" SG_ 1799 GST_RRHVU_Byte3 0;
BA_ "UsrSigPurpose" SG_ 1799 GST_RRHVU_Byte3 3;
BA_ "Description" SG_ 1799 GST_RRHVU_Byte3 "TP Index : 165";
BA_ "Version" SG_ 1799 GST_RRHVU_Byte4 "21.02.04";
BA_ "NetworkRequestHoldingTime" SG_ 1799 GST_RRHVU_Byte4 5000;
BA_ "NetworkRequest" SG_ 1799 GST_RRHVU_Byte4 0;
BA_ "UserSigValidity" SG_ 1799 GST_RRHVU_Byte4 0;
BA_ "UsrSigPurpose" SG_ 1799 GST_RRHVU_Byte4 3;
BA_ "Description" SG_ 1799 GST_RRHVU_Byte4 "TP Index : 165";
BA_ "Version" SG_ 1799 GST_RRHVU_Byte5 "21.02.04";
BA_ "NetworkRequestHoldingTime" SG_ 1799 GST_RRHVU_Byte5 5000;
BA_ "NetworkRequest" SG_ 1799 GST_RRHVU_Byte5 0;
BA_ "UserSigValidity" SG_ 1799 GST_RRHVU_Byte5 0;
BA_ "UsrSigPurpose" SG_ 1799 GST_RRHVU_Byte5 3;
BA_ "Description" SG_ 1799 GST_RRHVU_Byte5 "TP Index : 165";
BA_ "Version" SG_ 1799 GST_RRHVU_Byte6 "21.02.04";
BA_ "NetworkRequestHoldingTime" SG_ 1799 GST_RRHVU_Byte6 5000;
BA_ "NetworkRequest" SG_ 1799 GST_RRHVU_Byte6 0;
BA_ "UserSigValidity" SG_ 1799 GST_RRHVU_Byte6 0;
BA_ "UsrSigPurpose" SG_ 1799 GST_RRHVU_Byte6 3;
BA_ "Description" SG_ 1799 GST_RRHVU_Byte6 "TP Index : 165";
BA_ "Version" SG_ 1799 GST_RRHVU_Byte7 "21.02.04";
BA_ "NetworkRequestHoldingTime" SG_ 1799 GST_RRHVU_Byte7 5000;
BA_ "NetworkRequest" SG_ 1799 GST_RRHVU_Byte7 0;
BA_ "UserSigValidity" SG_ 1799 GST_RRHVU_Byte7 0;
BA_ "UsrSigPurpose" SG_ 1799 GST_RRHVU_Byte7 3;
BA_ "Description" SG_ 1799 GST_RRHVU_Byte7 "TP Index : 165";
BA_ "Version" SG_ 1799 GST_RRHVU_Byte1 "21.02.04";
BA_ "NetworkRequestHoldingTime" SG_ 1799 GST_RRHVU_Byte1 5000;
BA_ "NetworkRequest" SG_ 1799 GST_RRHVU_Byte1 0;
BA_ "UserSigValidity" SG_ 1799 GST_RRHVU_Byte1 0;
BA_ "UsrSigPurpose" SG_ 1799 GST_RRHVU_Byte1 3;
BA_ "Description" SG_ 1799 GST_RRHVU_Byte1 "TP Index : 165";
BA_ "Version" SG_ 847 Drv_SHVU_DTCdisplay "22.05.04";
BA_ "NetworkRequestHoldingTime" SG_ 847 Drv_SHVU_DTCdisplay 5000;
BA_ "NetworkRequest" SG_ 847 Drv_SHVU_DTCdisplay 0;
BA_ "UserSigValidity" SG_ 847 Drv_SHVU_DTCdisplay 7;
BA_ "GenSigSendType" SG_ 847 Drv_SHVU_DTCdisplay 4;
BA_ "Description" SG_ 847 Drv_SHVU_DTCdisplay "This signal indicates DTC Code of Self-Diagnostic mode (Driver Seat)";
BA_ "Version" SG_ 847 Drv_SHVU_DiagMode "22.05.04";
BA_ "NetworkRequestHoldingTime" SG_ 847 Drv_SHVU_DiagMode 5000;
BA_ "NetworkRequest" SG_ 847 Drv_SHVU_DiagMode 0;
BA_ "UserSigValidity" SG_ 847 Drv_SHVU_DiagMode 7;
BA_ "GenSigSendType" SG_ 847 Drv_SHVU_DiagMode 4;
BA_ "Description" SG_ 847 Drv_SHVU_DiagMode "This signal indicates operating mode of SHVU (Self-Diagnostic mode or normal mode)";
BA_ "Version" SG_ 2032 GST_RRMSU_MSU_RR_Byte0 "23.04.07";
BA_ "NetworkRequestHoldingTime" SG_ 2032 GST_RRMSU_MSU_RR_Byte0 5000;
BA_ "NetworkRequest" SG_ 2032 GST_RRMSU_MSU_RR_Byte0 0;
BA_ "UserSigValidity" SG_ 2032 GST_RRMSU_MSU_RR_Byte0 0;
BA_ "UsrSigPurpose" SG_ 2032 GST_RRMSU_MSU_RR_Byte0 3;
BA_ "Description" SG_ 2032 GST_RRMSU_MSU_RR_Byte0 "TP Index : 260";
BA_ "Version" SG_ 2032 GST_RRMSU_MSU_RR_Byte2 "23.04.07";
BA_ "NetworkRequestHoldingTime" SG_ 2032 GST_RRMSU_MSU_RR_Byte2 5000;
BA_ "NetworkRequest" SG_ 2032 GST_RRMSU_MSU_RR_Byte2 0;
BA_ "UserSigValidity" SG_ 2032 GST_RRMSU_MSU_RR_Byte2 0;
BA_ "UsrSigPurpose" SG_ 2032 GST_RRMSU_MSU_RR_Byte2 3;
BA_ "Description" SG_ 2032 GST_RRMSU_MSU_RR_Byte2 "TP Index : 260";
BA_ "Version" SG_ 2032 GST_RRMSU_MSU_RR_Byte3 "23.04.07";
BA_ "NetworkRequestHoldingTime" SG_ 2032 GST_RRMSU_MSU_RR_Byte3 5000;
BA_ "NetworkRequest" SG_ 2032 GST_RRMSU_MSU_RR_Byte3 0;
BA_ "UserSigValidity" SG_ 2032 GST_RRMSU_MSU_RR_Byte3 0;
BA_ "UsrSigPurpose" SG_ 2032 GST_RRMSU_MSU_RR_Byte3 3;
BA_ "Description" SG_ 2032 GST_RRMSU_MSU_RR_Byte3 "TP Index : 260";
BA_ "Version" SG_ 2032 GST_RRMSU_MSU_RR_Byte4 "23.04.07";
BA_ "NetworkRequestHoldingTime" SG_ 2032 GST_RRMSU_MSU_RR_Byte4 5000;
BA_ "NetworkRequest" SG_ 2032 GST_RRMSU_MSU_RR_Byte4 0;
BA_ "UserSigValidity" SG_ 2032 GST_RRMSU_MSU_RR_Byte4 0;
BA_ "UsrSigPurpose" SG_ 2032 GST_RRMSU_MSU_RR_Byte4 3;
BA_ "Description" SG_ 2032 GST_RRMSU_MSU_RR_Byte4 "TP Index : 260";
BA_ "Version" SG_ 2032 GST_RRMSU_MSU_RR_Byte5 "23.04.07";
BA_ "NetworkRequestHoldingTime" SG_ 2032 GST_RRMSU_MSU_RR_Byte5 5000;
BA_ "NetworkRequest" SG_ 2032 GST_RRMSU_MSU_RR_Byte5 0;
BA_ "UserSigValidity" SG_ 2032 GST_RRMSU_MSU_RR_Byte5 0;
BA_ "UsrSigPurpose" SG_ 2032 GST_RRMSU_MSU_RR_Byte5 3;
BA_ "Description" SG_ 2032 GST_RRMSU_MSU_RR_Byte5 "TP Index : 260";
BA_ "Version" SG_ 2032 GST_RRMSU_MSU_RR_Byte6 "23.04.07";
BA_ "NetworkRequestHoldingTime" SG_ 2032 GST_RRMSU_MSU_RR_Byte6 5000;
BA_ "NetworkRequest" SG_ 2032 GST_RRMSU_MSU_RR_Byte6 0;
BA_ "UserSigValidity" SG_ 2032 GST_RRMSU_MSU_RR_Byte6 0;
BA_ "UsrSigPurpose" SG_ 2032 GST_RRMSU_MSU_RR_Byte6 3;
BA_ "Description" SG_ 2032 GST_RRMSU_MSU_RR_Byte6 "TP Index : 260";
BA_ "Version" SG_ 2032 GST_RRMSU_MSU_RR_Byte7 "23.04.07";
BA_ "NetworkRequestHoldingTime" SG_ 2032 GST_RRMSU_MSU_RR_Byte7 5000;
BA_ "NetworkRequest" SG_ 2032 GST_RRMSU_MSU_RR_Byte7 0;
BA_ "UserSigValidity" SG_ 2032 GST_RRMSU_MSU_RR_Byte7 0;
BA_ "UsrSigPurpose" SG_ 2032 GST_RRMSU_MSU_RR_Byte7 3;
BA_ "Description" SG_ 2032 GST_RRMSU_MSU_RR_Byte7 "TP Index : 260";
BA_ "Version" SG_ 2032 GST_RRMSU_MSU_RR_Byte1 "23.04.07";
BA_ "NetworkRequestHoldingTime" SG_ 2032 GST_RRMSU_MSU_RR_Byte1 5000;
BA_ "NetworkRequest" SG_ 2032 GST_RRMSU_MSU_RR_Byte1 0;
BA_ "UserSigValidity" SG_ 2032 GST_RRMSU_MSU_RR_Byte1 0;
BA_ "UsrSigPurpose" SG_ 2032 GST_RRMSU_MSU_RR_Byte1 3;
BA_ "Description" SG_ 2032 GST_RRMSU_MSU_RR_Byte1 "TP Index : 260";
BA_ "Version" SG_ 952 BLTN_CAM_Set_FR_Ver_Pos "22.07.06";
BA_ "RoutingFactor" SG_ 952 BLTN_CAM_Set_FR_Ver_Pos 0;
BA_ "UserSigValidity" SG_ 952 BLTN_CAM_Set_FR_Ver_Pos 0;
BA_ "GenSigSendType" SG_ 952 BLTN_CAM_Set_FR_Ver_Pos 4;
BA_ "Description" SG_ 952 BLTN_CAM_Set_FR_Ver_Pos "Front Camera Vertical position setting value.";
BA_ "Version" SG_ 952 BLTN_CAM_Set_PEV_AppNoti "21.05.02";
BA_ "RoutingFactor" SG_ 952 BLTN_CAM_Set_PEV_AppNoti 0;
BA_ "UserSigValidity" SG_ 952 BLTN_CAM_Set_PEV_AppNoti 0;
BA_ "GenSigSendType" SG_ 952 BLTN_CAM_Set_PEV_AppNoti 4;
BA_ "Description" SG_ 952 BLTN_CAM_Set_PEV_AppNoti "Parked Event notification to Connectivity Phone App. On/Off";
BA_ "Version" SG_ 952 BLTN_CAM_Set_WiFi_AutoOn "21.05.02";
BA_ "RoutingFactor" SG_ 952 BLTN_CAM_Set_WiFi_AutoOn 0;
BA_ "UserSigValidity" SG_ 952 BLTN_CAM_Set_WiFi_AutoOn 0;
BA_ "GenSigSendType" SG_ 952 BLTN_CAM_Set_WiFi_AutoOn 4;
BA_ "Description" SG_ 952 BLTN_CAM_Set_WiFi_AutoOn "Wifi On/Off User setting";
BA_ "Version" SG_ 952 BLTN_CAM_StrgPropSet "21.05.02";
BA_ "RoutingFactor" SG_ 952 BLTN_CAM_StrgPropSet 0;
BA_ "UserSigValidity" SG_ 952 BLTN_CAM_StrgPropSet 0;
BA_ "GenSigSendType" SG_ 952 BLTN_CAM_StrgPropSet 4;
BA_ "Description" SG_ 952 BLTN_CAM_StrgPropSet "Propotion of built-in Cam SD card Propotion set of the Recording Categories";
BA_ "Version" SG_ 952 BLTN_CAM_File_DEL_CPY_Op_State "21.05.02";
BA_ "RoutingFactor" SG_ 952 BLTN_CAM_File_DEL_CPY_Op_State 0;
BA_ "UserSigValidity" SG_ 952 BLTN_CAM_File_DEL_CPY_Op_State 0;
BA_ "GenSigSendType" SG_ 952 BLTN_CAM_File_DEL_CPY_Op_State 4;
BA_ "Description" SG_ 952 BLTN_CAM_File_DEL_CPY_Op_State "Bulil in Cam Fily copy and delete operating state.";
BA_ "Version" SG_ 952 BLTN_CAM_File_DEL_CPY_NumTot "21.05.02";
BA_ "RoutingFactor" SG_ 952 BLTN_CAM_File_DEL_CPY_NumTot 0;
BA_ "UserSigValidity" SG_ 952 BLTN_CAM_File_DEL_CPY_NumTot 0;
BA_ "GenSigSendType" SG_ 952 BLTN_CAM_File_DEL_CPY_NumTot 4;
BA_ "Description" SG_ 952 BLTN_CAM_File_DEL_CPY_NumTot "Number of Copied or Deleted files.";
BA_ "Version" SG_ 952 BLTN_CAM_File_DEL_CPYed_Num "21.05.02";
BA_ "RoutingFactor" SG_ 952 BLTN_CAM_File_DEL_CPYed_Num 0;
BA_ "UserSigValidity" SG_ 952 BLTN_CAM_File_DEL_CPYed_Num 0;
BA_ "GenSigSendType" SG_ 952 BLTN_CAM_File_DEL_CPYed_Num 4;
BA_ "Description" SG_ 952 BLTN_CAM_File_DEL_CPYed_Num "Total number of the copy or delete file.";
BA_ "Version" SG_ 952 BLTN_CAM_Set_RR_Ver_Pos "22.07.06";
BA_ "RoutingFactor" SG_ 952 BLTN_CAM_Set_RR_Ver_Pos 0;
BA_ "UserSigValidity" SG_ 952 BLTN_CAM_Set_RR_Ver_Pos 0;
BA_ "GenSigSendType" SG_ 952 BLTN_CAM_Set_RR_Ver_Pos 4;
BA_ "Description" SG_ 952 BLTN_CAM_Set_RR_Ver_Pos "Rear Camera Vertical position setting value.";
BA_ "Version" SG_ 2040 RRMSU_MSU_RR_GST_Byte0 "23.04.07";
BA_ "UserSigValidity" SG_ 2040 RRMSU_MSU_RR_GST_Byte0 0;
BA_ "UsrSigPurpose" SG_ 2040 RRMSU_MSU_RR_GST_Byte0 4;
BA_ "Description" SG_ 2040 RRMSU_MSU_RR_GST_Byte0 "TP Index : 260";
BA_ "Version" SG_ 2040 RRMSU_MSU_RR_GST_Byte2 "23.04.07";
BA_ "UserSigValidity" SG_ 2040 RRMSU_MSU_RR_GST_Byte2 0;
BA_ "UsrSigPurpose" SG_ 2040 RRMSU_MSU_RR_GST_Byte2 4;
BA_ "Description" SG_ 2040 RRMSU_MSU_RR_GST_Byte2 "TP Index : 260";
BA_ "Version" SG_ 2040 RRMSU_MSU_RR_GST_Byte3 "23.04.07";
BA_ "UserSigValidity" SG_ 2040 RRMSU_MSU_RR_GST_Byte3 0;
BA_ "UsrSigPurpose" SG_ 2040 RRMSU_MSU_RR_GST_Byte3 4;
BA_ "Description" SG_ 2040 RRMSU_MSU_RR_GST_Byte3 "TP Index : 260";
BA_ "Version" SG_ 2040 RRMSU_MSU_RR_GST_Byte4 "23.04.07";
BA_ "UserSigValidity" SG_ 2040 RRMSU_MSU_RR_GST_Byte4 0;
BA_ "UsrSigPurpose" SG_ 2040 RRMSU_MSU_RR_GST_Byte4 4;
BA_ "Description" SG_ 2040 RRMSU_MSU_RR_GST_Byte4 "TP Index : 260";
BA_ "Version" SG_ 2040 RRMSU_MSU_RR_GST_Byte5 "23.04.07";
BA_ "UserSigValidity" SG_ 2040 RRMSU_MSU_RR_GST_Byte5 0;
BA_ "UsrSigPurpose" SG_ 2040 RRMSU_MSU_RR_GST_Byte5 4;
BA_ "Description" SG_ 2040 RRMSU_MSU_RR_GST_Byte5 "TP Index : 260";
BA_ "Version" SG_ 2040 RRMSU_MSU_RR_GST_Byte6 "23.04.07";
BA_ "UserSigValidity" SG_ 2040 RRMSU_MSU_RR_GST_Byte6 0;
BA_ "UsrSigPurpose" SG_ 2040 RRMSU_MSU_RR_GST_Byte6 4;
BA_ "Description" SG_ 2040 RRMSU_MSU_RR_GST_Byte6 "TP Index : 260";
BA_ "Version" SG_ 2040 RRMSU_MSU_RR_GST_Byte7 "23.04.07";
BA_ "UserSigValidity" SG_ 2040 RRMSU_MSU_RR_GST_Byte7 0;
BA_ "UsrSigPurpose" SG_ 2040 RRMSU_MSU_RR_GST_Byte7 4;
BA_ "Description" SG_ 2040 RRMSU_MSU_RR_GST_Byte7 "TP Index : 260";
BA_ "Version" SG_ 2040 RRMSU_MSU_RR_GST_Byte1 "23.04.07";
BA_ "UserSigValidity" SG_ 2040 RRMSU_MSU_RR_GST_Byte1 0;
BA_ "UsrSigPurpose" SG_ 2040 RRMSU_MSU_RR_GST_Byte1 4;
BA_ "Description" SG_ 2040 RRMSU_MSU_RR_GST_Byte1 "TP Index : 260";
BA_ "Version" SG_ 950 BLTN_CAM_State "21.05.02";
BA_ "RoutingFactor" SG_ 950 BLTN_CAM_State 0;
BA_ "UserSigValidity" SG_ 950 BLTN_CAM_State 1;
BA_ "GenSigSendType" SG_ 950 BLTN_CAM_State 4;
BA_ "Description" SG_ 950 BLTN_CAM_State "This Signal is for cluster warning popup.";
BA_ "Version" SG_ 950 BLTN_CAM_RecSta_DEV "21.05.02";
BA_ "RoutingFactor" SG_ 950 BLTN_CAM_RecSta_DEV 0;
BA_ "UserSigValidity" SG_ 950 BLTN_CAM_RecSta_DEV 1;
BA_ "GenSigSendType" SG_ 950 BLTN_CAM_RecSta_DEV 4;
BA_ "Description" SG_ 950 BLTN_CAM_RecSta_DEV "This Signal inform recording status of Driving Event.";
BA_ "Version" SG_ 950 BLTN_CAM_RecSta_MAR "21.05.02";
BA_ "RoutingFactor" SG_ 950 BLTN_CAM_RecSta_MAR 0;
BA_ "UserSigValidity" SG_ 950 BLTN_CAM_RecSta_MAR 1;
BA_ "GenSigSendType" SG_ 950 BLTN_CAM_RecSta_MAR 4;
BA_ "Description" SG_ 950 BLTN_CAM_RecSta_MAR "This Signal inform recording status of Manual Recording.";
BA_ "Version" SG_ 950 BLTN_CAM_RecSta_TML "21.05.02";
BA_ "RoutingFactor" SG_ 950 BLTN_CAM_RecSta_TML 0;
BA_ "UserSigValidity" SG_ 950 BLTN_CAM_RecSta_TML 1;
BA_ "GenSigSendType" SG_ 950 BLTN_CAM_RecSta_TML 4;
BA_ "Description" SG_ 950 BLTN_CAM_RecSta_TML "This Signal inform recording status of Time-lapse.";
BA_ "Version" SG_ 950 BLTN_CAM_RecSta_OWP "21.05.02";
BA_ "RoutingFactor" SG_ 950 BLTN_CAM_RecSta_OWP 0;
BA_ "UserSigValidity" SG_ 950 BLTN_CAM_RecSta_OWP 1;
BA_ "GenSigSendType" SG_ 950 BLTN_CAM_RecSta_OWP 4;
BA_ "Description" SG_ 950 BLTN_CAM_RecSta_OWP "This Signal inform recording status of On While Parked.";
BA_ "Version" SG_ 950 BLTN_CAM_RecSta_PEV "21.05.02";
BA_ "RoutingFactor" SG_ 950 BLTN_CAM_RecSta_PEV 0;
BA_ "UserSigValidity" SG_ 950 BLTN_CAM_RecSta_PEV 1;
BA_ "GenSigSendType" SG_ 950 BLTN_CAM_RecSta_PEV 4;
BA_ "Description" SG_ 950 BLTN_CAM_RecSta_PEV "This Signal inform recording status of Parked Event.";
BA_ "Version" SG_ 950 BLTN_CAM_Prk_EV_Cnt "21.05.02";
BA_ "RoutingFactor" SG_ 950 BLTN_CAM_Prk_EV_Cnt 0;
BA_ "UserSigValidity" SG_ 950 BLTN_CAM_Prk_EV_Cnt 1;
BA_ "GenSigSendType" SG_ 950 BLTN_CAM_Prk_EV_Cnt 4;
BA_ "Description" SG_ 950 BLTN_CAM_Prk_EV_Cnt "The count number of a parked Event.";
BA_ "Version" SG_ 950 BLTN_CAM_Prk_Oped_Time "22.07.05";
BA_ "RoutingFactor" SG_ 950 BLTN_CAM_Prk_Oped_Time 0;
BA_ "UserSigValidity" SG_ 950 BLTN_CAM_Prk_Oped_Time 1;
BA_ "GenSigSendType" SG_ 950 BLTN_CAM_Prk_Oped_Time 4;
BA_ "Description" SG_ 950 BLTN_CAM_Prk_Oped_Time "The Parked Opreated time ingormation";
BA_ "Version" SG_ 950 BLTN_CAM_Prk_Oprable_Time "25.01.01";
BA_ "RoutingFactor" SG_ 950 BLTN_CAM_Prk_Oprable_Time 0;
BA_ "UserSigValidity" SG_ 950 BLTN_CAM_Prk_Oprable_Time 1;
BA_ "GenSigSendType" SG_ 950 BLTN_CAM_Prk_Oprable_Time 4;
BA_ "Description" SG_ 950 BLTN_CAM_Prk_Oprable_Time "The hours of Park Mode Operatable, the time is limited by user max oper. Set.";
BA_ "Version" SG_ 950 BLTN_CAM_SD_Card_State "22.05.02";
BA_ "RoutingFactor" SG_ 950 BLTN_CAM_SD_Card_State 0;
BA_ "NetworkRequestHoldingTime" SG_ 950 BLTN_CAM_SD_Card_State 1000;
BA_ "NetworkRequest" SG_ 950 BLTN_CAM_SD_Card_State 0;
BA_ "UserSigValidity" SG_ 950 BLTN_CAM_SD_Card_State 0;
BA_ "GenSigSendType" SG_ 950 BLTN_CAM_SD_Card_State 4;
BA_ "Description" SG_ 950 BLTN_CAM_SD_Card_State "This Signal is for SD card Status in Built-in App menu and CCS Phone App.";
BA_ "Version" SG_ 950 BLTN_CAM_Prk_Oprable_Time_Max "24.07.05";
BA_ "RoutingFactor" SG_ 950 BLTN_CAM_Prk_Oprable_Time_Max 0;
BA_ "UserSigValidity" SG_ 950 BLTN_CAM_Prk_Oprable_Time_Max 1;
BA_ "GenSigSendType" SG_ 950 BLTN_CAM_Prk_Oprable_Time_Max 4;
BA_ "Description" SG_ 950 BLTN_CAM_Prk_Oprable_Time_Max "The hours of Park Mode Operatable, the time has no limit.";
BA_ "Version" SG_ 950 BLTN_CAM_AuxBat_Conn_State "24.07.05";
BA_ "RoutingFactor" SG_ 950 BLTN_CAM_AuxBat_Conn_State 0;
BA_ "UserSigValidity" SG_ 950 BLTN_CAM_AuxBat_Conn_State 0;
BA_ "GenSigSendType" SG_ 950 BLTN_CAM_AuxBat_Conn_State 4;
BA_ "Description" SG_ 950 BLTN_CAM_AuxBat_Conn_State "The auxiliary Battery conntction information.";
BA_ "Version" SG_ 950 BLTN_CAM_AuxBat_CapPer "21.05.02";
BA_ "RoutingFactor" SG_ 950 BLTN_CAM_AuxBat_CapPer 0;
BA_ "UserSigValidity" SG_ 950 BLTN_CAM_AuxBat_CapPer 1;
BA_ "GenSigSendType" SG_ 950 BLTN_CAM_AuxBat_CapPer 4;
BA_ "Description" SG_ 950 BLTN_CAM_AuxBat_CapPer "The percentage of Aux. Bat.";
BA_ "Version" SG_ 950 BLTN_CAM_RecSta_OWD "21.05.02";
BA_ "RoutingFactor" SG_ 950 BLTN_CAM_RecSta_OWD 0;
BA_ "UserSigValidity" SG_ 950 BLTN_CAM_RecSta_OWD 1;
BA_ "GenSigSendType" SG_ 950 BLTN_CAM_RecSta_OWD 4;
BA_ "Description" SG_ 950 BLTN_CAM_RecSta_OWD "This Signal inform recording status of On While Driving.";
BA_ "Version" SG_ 951 BLTN_CAM_RecSet_OWD "21.05.02";
BA_ "UserSigValidity" SG_ 951 BLTN_CAM_RecSet_OWD 0;
BA_ "GenSigSendType" SG_ 951 BLTN_CAM_RecSet_OWD 4;
BA_ "Description" SG_ 951 BLTN_CAM_RecSet_OWD "Record On/Off Set of On While Driving";
BA_ "Version" SG_ 951 BLTN_CAM_Set_Tim_Stm "21.05.02";
BA_ "UserSigValidity" SG_ 951 BLTN_CAM_Set_Tim_Stm 0;
BA_ "GenSigSendType" SG_ 951 BLTN_CAM_Set_Tim_Stm 4;
BA_ "Description" SG_ 951 BLTN_CAM_Set_Tim_Stm "Record Set of Date and Time Stamp";
BA_ "Version" SG_ 951 BLTN_CAM_Set_Spd_Stm "21.11.07";
BA_ "UserSigValidity" SG_ 951 BLTN_CAM_Set_Spd_Stm 0;
BA_ "GenSigSendType" SG_ 951 BLTN_CAM_Set_Spd_Stm 4;
BA_ "Description" SG_ 951 BLTN_CAM_Set_Spd_Stm "Record Set of Speed Stamp";
BA_ "Version" SG_ 951 BLTN_CAM_Set_Locatn_Stm "21.05.02";
BA_ "UserSigValidity" SG_ 951 BLTN_CAM_Set_Locatn_Stm 0;
BA_ "GenSigSendType" SG_ 951 BLTN_CAM_Set_Locatn_Stm 4;
BA_ "Description" SG_ 951 BLTN_CAM_Set_Locatn_Stm "Record Set of Location Stamp";
BA_ "Version" SG_ 951 BLTN_CAM_Set_TrnSig_Stm "21.05.02";
BA_ "UserSigValidity" SG_ 951 BLTN_CAM_Set_TrnSig_Stm 0;
BA_ "GenSigSendType" SG_ 951 BLTN_CAM_Set_TrnSig_Stm 4;
BA_ "Description" SG_ 951 BLTN_CAM_Set_TrnSig_Stm "Record Set of Turn Signal Stamp";
BA_ "Version" SG_ 951 BLTN_CAM_Set_AclBrk_Stm "21.11.07";
BA_ "UserSigValidity" SG_ 951 BLTN_CAM_Set_AclBrk_Stm 0;
BA_ "GenSigSendType" SG_ 951 BLTN_CAM_Set_AclBrk_Stm 4;
BA_ "Description" SG_ 951 BLTN_CAM_Set_AclBrk_Stm "Record Set of Accelerator Brake Stamp";
BA_ "Version" SG_ 951 BLTN_CAM_RecSet_DEV "21.05.02";
BA_ "UserSigValidity" SG_ 951 BLTN_CAM_RecSet_DEV 0;
BA_ "GenSigSendType" SG_ 951 BLTN_CAM_RecSet_DEV 4;
BA_ "Description" SG_ 951 BLTN_CAM_RecSet_DEV "Record On/Off Set of Driving Event";
BA_ "Version" SG_ 951 BLTN_CAM_Set_GearPos_Stm "21.05.02";
BA_ "UserSigValidity" SG_ 951 BLTN_CAM_Set_GearPos_Stm 0;
BA_ "GenSigSendType" SG_ 951 BLTN_CAM_Set_GearPos_Stm 4;
BA_ "Description" SG_ 951 BLTN_CAM_Set_GearPos_Stm "Record Set of Gear Position Stamp";
BA_ "Version" SG_ 951 BLTN_CAM_Set_EVSen_Stm "21.05.02";
BA_ "UserSigValidity" SG_ 951 BLTN_CAM_Set_EVSen_Stm 0;
BA_ "GenSigSendType" SG_ 951 BLTN_CAM_Set_EVSen_Stm 4;
BA_ "Description" SG_ 951 BLTN_CAM_Set_EVSen_Stm "Record Set of Event Sensitivity Stamp";
BA_ "Version" SG_ 951 BLTN_CAM_Set_StrAngl_Stm "21.07.05";
BA_ "UserSigValidity" SG_ 951 BLTN_CAM_Set_StrAngl_Stm 0;
BA_ "GenSigSendType" SG_ 951 BLTN_CAM_Set_StrAngl_Stm 4;
BA_ "Description" SG_ 951 BLTN_CAM_Set_StrAngl_Stm "Record Set of Steering Angle Stamp";
BA_ "Version" SG_ 951 BLTN_CAM_Set_EV_RecMaxTime "23.02.02";
BA_ "UserSigValidity" SG_ 951 BLTN_CAM_Set_EV_RecMaxTime 0;
BA_ "GenSigSendType" SG_ 951 BLTN_CAM_Set_EV_RecMaxTime 4;
BA_ "Description" SG_ 951 BLTN_CAM_Set_EV_RecMaxTime "BLTN_CAM Set EV Parking Rec Max Time";
BA_ "Version" SG_ 951 BLTN_CAM_Set_PrkTime "25.01.01";
BA_ "UserSigValidity" SG_ 951 BLTN_CAM_Set_PrkTime 0;
BA_ "GenSigSendType" SG_ 951 BLTN_CAM_Set_PrkTime 4;
BA_ "Description" SG_ 951 BLTN_CAM_Set_PrkTime "Parking Operation Setting Time, Resolution : hr";
BA_ "Version" SG_ 951 BLTN_CAM_Set_EV_BfrTime "21.05.02";
BA_ "UserSigValidity" SG_ 951 BLTN_CAM_Set_EV_BfrTime 0;
BA_ "GenSigSendType" SG_ 951 BLTN_CAM_Set_EV_BfrTime 4;
BA_ "Description" SG_ 951 BLTN_CAM_Set_EV_BfrTime "Driving Event Time Setting - Before, Resolution : sec";
BA_ "Version" SG_ 951 BLTN_CAM_RecSet_OWP "21.05.02";
BA_ "UserSigValidity" SG_ 951 BLTN_CAM_RecSet_OWP 0;
BA_ "GenSigSendType" SG_ 951 BLTN_CAM_RecSet_OWP 4;
BA_ "Description" SG_ 951 BLTN_CAM_RecSet_OWP "Record On/Off Set of On While Parked, 0x0(Default) : Parking recording function not supported";
BA_ "Version" SG_ 951 BLTN_CAM_Set_EV_AftTime "21.05.02";
BA_ "UserSigValidity" SG_ 951 BLTN_CAM_Set_EV_AftTime 0;
BA_ "GenSigSendType" SG_ 951 BLTN_CAM_Set_EV_AftTime 4;
BA_ "Description" SG_ 951 BLTN_CAM_Set_EV_AftTime "Driving Event Time Setting - After, Resolution : sec";
BA_ "Version" SG_ 951 BLTN_CAM_Set_Drv_TML_Int "21.05.02";
BA_ "UserSigValidity" SG_ 951 BLTN_CAM_Set_Drv_TML_Int 0;
BA_ "GenSigSendType" SG_ 951 BLTN_CAM_Set_Drv_TML_Int 4;
BA_ "Description" SG_ 951 BLTN_CAM_Set_Drv_TML_Int "Record Set of Time-lapse Interval, Resolution : sec";
BA_ "Version" SG_ 951 BLTN_CAM_SenSet_DEV "21.05.02";
BA_ "UserSigValidity" SG_ 951 BLTN_CAM_SenSet_DEV 0;
BA_ "GenSigSendType" SG_ 951 BLTN_CAM_SenSet_DEV 4;
BA_ "Description" SG_ 951 BLTN_CAM_SenSet_DEV "Set of Event  Detection Sensitivity of Driving Mode";
BA_ "Version" SG_ 951 BLTN_CAM_SenSet_PEV "21.05.02";
BA_ "UserSigValidity" SG_ 951 BLTN_CAM_SenSet_PEV 0;
BA_ "GenSigSendType" SG_ 951 BLTN_CAM_SenSet_PEV 4;
BA_ "Description" SG_ 951 BLTN_CAM_SenSet_PEV "Set of Event  Detection Sensitivity of Parking Mode";
BA_ "Version" SG_ 951 BLTN_CAM_RecSet_PEV "21.05.02";
BA_ "UserSigValidity" SG_ 951 BLTN_CAM_RecSet_PEV 0;
BA_ "GenSigSendType" SG_ 951 BLTN_CAM_RecSet_PEV 4;
BA_ "Description" SG_ 951 BLTN_CAM_RecSet_PEV "Record Set of Parked Event, 0x0(Default) : Parking recording function not supported";
BA_ "Version" SG_ 951 BLTN_CAM_AudRec_Set "21.05.02";
BA_ "UserSigValidity" SG_ 951 BLTN_CAM_AudRec_Set 0;
BA_ "GenSigSendType" SG_ 951 BLTN_CAM_AudRec_Set 4;
BA_ "Description" SG_ 951 BLTN_CAM_AudRec_Set "Audio Record On/Off Set";
BA_ "Version" SG_ 2281835010 ACU_ActvFltSta "17.12.00";
BA_ "UserSigValidity" SG_ 2281835010 ACU_ActvFltSta 3;
BA_ "GenSigStartValue" SG_ 2281835010 ACU_ActvFltSta 2;
BA_ "Description" SG_ 2281835010 ACU_ActvFltSta "This signal means information regarding fault status, whether it is an active fault or not.



1) Default value : 0x2

2) Default value Transmit condition

    - When the input condition is not supported.";
BA_ "Version" SG_ 2281835010 ACU_NumOfEvtTrigVal "18.04.00";
BA_ "UserSigValidity" SG_ 2281835010 ACU_NumOfEvtTrigVal 3;
BA_ "Description" SG_ 2281835010 ACU_NumOfEvtTrigVal "This signal is incremented by one each time when ACU meet EDR trigger condition

The last value is kept in the next cycle.



1) Value in EOL : always 0x0";
BA_ "Version" SG_ 2281835010 ACU_SdArbgExtTyp "19.07.06";
BA_ "UserSigValidity" SG_ 2281835010 ACU_SdArbgExtTyp 3;
BA_ "Description" SG_ 2281835010 ACU_SdArbgExtTyp "This signal does not specify the types or variations of the side restraints such as the front side airbag only or both the front and the rear side airbag. If any side restraint is equipped, the signal responds as 'exists'.

¡ØInitial value shall be actua";
BA_ "Version" SG_ 2281835010 ACU_PassArbg_SW_Sta "20.08.07";
BA_ "UserSigValidity" SG_ 2281835010 ACU_PassArbg_SW_Sta 3;
BA_ "Description" SG_ 2281835010 ACU_PassArbg_SW_Sta "This signal indicates that the state of passenger airbag on/off switch

¡ØBefore EOL : 0x0(NOT APPLIED) transmit,    (Default value : 0x0)";
BA_ "Version" SG_ 2281835010 ACU_HDPSpprtSWVer "21.12.07";
BA_ "UserSigValidity" SG_ 2281835010 ACU_HDPSpprtSWVer 3;
BA_ "Description" SG_ 2281835010 ACU_HDPSpprtSWVer "This signal means the software version information of signals related to HDP cooperative control.

If the ACU signal related to HDP cooperative control is modified, this signal is changed.

0x0 : Not Support(intit)

After IGN On, 0x0 is transmitted in th";
BA_ "Version" SG_ 2281835010 Reprogram_State_ACU "24.03.06";
BA_ "UserSigValidity" SG_ 2281835010 Reprogram_State_ACU 0;
BA_ "Description" SG_ 2281835010 Reprogram_State_ACU "This signal indicates Reprogram Status of ACU/ISCM(Function Safety Controller)";
BA_ "Version" SG_ 2281835010 ACU_EmerModSta "18.04.00";
BA_ "UserSigValidity" SG_ 2281835010 ACU_EmerModSta 3;
BA_ "Description" SG_ 2281835010 ACU_EmerModSta "This signal is set when  ACU detect Emergency mode status 

 (e.g : During driving, IGN1+ is disconnected)  

1)Value in EOL :  always 0x0 

2)Emergency mode details in ES95910-02";
BA_ "Version" SG_ 2281835010 ACU_EvtTrigSta "18.04.00";
BA_ "UserSigValidity" SG_ 2281835010 ACU_EvtTrigSta 3;
BA_ "Description" SG_ 2281835010 ACU_EvtTrigSta "This signal is set when  ACU meet EDR trigger condition.

Event trigger condition is same as EDR Regulation definition(49 CFR PART 563)

This signal is set to '1'  then kept for the current IGN cycle as '1'



1)Value in EOL :  always 0x0";
BA_ "Version" SG_ 2281835010 ACU_NumOfEmerModVal "18.04.00";
BA_ "UserSigValidity" SG_ 2281835010 ACU_NumOfEmerModVal 3;
BA_ "Description" SG_ 2281835010 ACU_NumOfEmerModVal "This signal is incremented by one each time when ACU enters into emergency mode.

The last value is kept in the next cycle.



1) Value in EOL : always 0x0

2)Emergency mode details in ES95910-02";
BA_ "Version" SG_ 2281835009 ACU_Crc1Val "21.09.03";
BA_ "UserSigValidity" SG_ 2281835009 ACU_Crc1Val 3;
BA_ "GenSigStartValue" SG_ 2281835009 ACU_Crc1Val 65535;
BA_ "Description" SG_ 2281835009 ACU_Crc1Val "The data area for CRC calculation is based on the data length (DLC) of the message DB.

The CRC shall be calculated over the entire data block (excluding the CRC bytes) including the user data, alive counter and Data ID



- CRC Polynomial (0x1021) , Ini";
BA_ "Version" SG_ 2281835009 ACU_AlvCnt1Val "21.09.03";
BA_ "UserSigValidity" SG_ 2281835009 ACU_AlvCnt1Val 3;
BA_ "Description" SG_ 2281835009 ACU_AlvCnt1Val "For the first transmission request for a data element the counter shall be initialized with 0 and shall be incremented by 1 for every subsequent send request. 

When the counter reaches the maximum value(0xFF), then it shall restart with 0 for the next s";
BA_ "Version" SG_ 2281835009 ACU_SysWrngLmpDis "18.11.05";
BA_ "UserSigValidity" SG_ 2281835009 ACU_SysWrngLmpDis 3;
BA_ "GenSigStartValue" SG_ 2281835009 ACU_SysWrngLmpDis 1;
BA_ "Description" SG_ 2281835009 ACU_SysWrngLmpDis "This signal means information regarding ACU diagnostic information result & discrimination.



1) Default value : 0x1

2) Default value Transmit condition

    - When the input condition is not determined.

    - When the input condition is not supported";
BA_ "Version" SG_ 2281835009 ACU_TlltlLmpDis "20.03.02";
BA_ "UserSigValidity" SG_ 2281835009 ACU_TlltlLmpDis 3;
BA_ "GenSigStartValue" SG_ 2281835009 ACU_TlltlLmpDis 3;
BA_ "Description" SG_ 2281835009 ACU_TlltlLmpDis "This signal means information regarding Occupant status.

0) 00Xb : X position means PAB OFF Lamp indication. When this bit set as 1 PAB OFF lamp turns ON. 

    0Y0b : Y position means PAB ON Lamp indication. When this bit set as 1 PAB ON lamp turns ON.";
BA_ "Version" SG_ 2281835009 ACU_OdsIDReq "17.12.00";
BA_ "UserSigValidity" SG_ 2281835009 ACU_OdsIDReq 3;
BA_ "Description" SG_ 2281835009 ACU_OdsIDReq "It s a Request to send ODS Identifier. If the Bit is equal to `0` the ODS-B module will transmit the ODS identifier message. ACU sets ¡°ODS ID Received¡± to ¡®1¡¯ after getting the valid ODS ID two times.



1) Default value : 0x0

2) Default value Trans";
BA_ "Version" SG_ 2281835009 SeatBelt_PassBcklFltSta "19.01.08";
BA_ "UserSigValidity" SG_ 2281835009 SeatBelt_PassBcklFltSta 3;
BA_ "Description" SG_ 2281835009 SeatBelt_PassBcklFltSta "Information of Passenger Seat Belt Buckle switch Fault condition.



1) Default value : 0x0

2) Default value Transmit condition

    - When the input condition is not supported.

¡ØThis signal is valid (updated) only that buckle is connected to ACU dire";
BA_ "Version" SG_ 2281835009 SeatBelt_DrvrBcklFltSta "19.01.08";
BA_ "UserSigValidity" SG_ 2281835009 SeatBelt_DrvrBcklFltSta 3;
BA_ "Description" SG_ 2281835009 SeatBelt_DrvrBcklFltSta "Information of Driver Seat Belt Buckle switch Fault condition.



1) Default value : 0x0

2) Default value Transmit condition

    - When the input condition is not supported.

¡ØThis signal is valid (updated) only that buckle is connected to ACU directl";
BA_ "Version" SG_ 2281835009 SeatBelt_PassBcklSta "19.01.08";
BA_ "UserSigValidity" SG_ 2281835009 SeatBelt_PassBcklSta 3;
BA_ "GenSigStartValue" SG_ 2281835009 SeatBelt_PassBcklSta 1;
BA_ "Description" SG_ 2281835009 SeatBelt_PassBcklSta "Information of Passenger Seat Belt Buckle switch Status, whether its Latched or Not .



1) Default value : 0x1

2) Default value Transmit condition

    - When the input condition is not determined.

    - When the input condition is not supported.

¡ØT";
BA_ "Version" SG_ 2281835009 SeatBelt_DrvrBcklSta "19.01.08";
BA_ "UserSigValidity" SG_ 2281835009 SeatBelt_DrvrBcklSta 3;
BA_ "GenSigStartValue" SG_ 2281835009 SeatBelt_DrvrBcklSta 1;
BA_ "Description" SG_ 2281835009 SeatBelt_DrvrBcklSta "Information of Driver Seat Belt Buckle switch Status, whether its Latched or Not.



1) Default value : 0x1

2) Default value Transmit condition

    - When the input condition is not determined.

    - When the input condition is not supported.

¡ØThis ";
BA_ "Version" SG_ 2281835009 ACU_DiagTrblCodVal "17.12.00";
BA_ "UserSigValidity" SG_ 2281835009 ACU_DiagTrblCodVal 3;
BA_ "Description" SG_ 2281835009 ACU_DiagTrblCodVal "This signal means information regarding a diagnostic trouble code number.



1) Default value : 0x0

2) Default value Transmit condition

    - When Fault does not exist.";
BA_ "Version" SG_ 2281835009 ACU_FltNumVal "17.12.00";
BA_ "UserSigValidity" SG_ 2281835009 ACU_FltNumVal 3;
BA_ "Description" SG_ 2281835009 ACU_FltNumVal "This signal means information regarding number of fault in ACU memory, including active and historic faults.



1) Default value : 0x0

2) Default value Transmit condition

    - When Fault does not exist.";
BA_ "Version" SG_ 2353205505 CDCU_Crc1Val "21.09.03";
BA_ "RoutingFactor" SG_ 2353205505 CDCU_Crc1Val 2;
BA_ "UserSigValidity" SG_ 2353205505 CDCU_Crc1Val 3;
BA_ "GenSigStartValue" SG_ 2353205505 CDCU_Crc1Val 65535;
BA_ "Description" SG_ 2353205505 CDCU_Crc1Val "The data area for CRC calculation is based on the data length (DLC) of the message DB.

The CRC shall be calculated over the entire data block (excluding the CRC bytes) including the user data, alive counter and Data ID



- CRC Polynomial (0x1021) , Ini";
BA_ "Version" SG_ 2353205505 CDCU_AlvCnt1Val "21.09.03";
BA_ "RoutingFactor" SG_ 2353205505 CDCU_AlvCnt1Val 2;
BA_ "UserSigValidity" SG_ 2353205505 CDCU_AlvCnt1Val 3;
BA_ "Description" SG_ 2353205505 CDCU_AlvCnt1Val "For the first transmission request for a data element the counter shall be initialized with 0 and shall be incremented by 1 for every subsequent send request. 

When the counter reaches the maximum value(0xFF), then it shall restart with 0 for the next s";
BA_ "Version" SG_ 2353205505 CDCU_Rd_LongGrdntPerc "21.05.02";
BA_ "RoutingFactor" SG_ 2353205505 CDCU_Rd_LongGrdntPerc 2;
BA_ "UserSigValidity" SG_ 2353205505 CDCU_Rd_LongGrdntPerc 3;
BA_ "Description" SG_ 2353205505 CDCU_Rd_LongGrdntPerc "This signal indicates longitudinal gradient in % unit.";
BA_ "Version" SG_ 2353205505 CDCU_Rd_LatGrdntPerc "21.05.02";
BA_ "RoutingFactor" SG_ 2353205505 CDCU_Rd_LatGrdntPerc 2;
BA_ "UserSigValidity" SG_ 2353205505 CDCU_Rd_LatGrdntPerc 3;
BA_ "Description" SG_ 2353205505 CDCU_Rd_LatGrdntPerc "This signal indicates lateral gradient in % unit.";
BA_ "Version" SG_ 2353205505 CDCU_CPE_Sta "21.05.02";
BA_ "RoutingFactor" SG_ 2353205505 CDCU_CPE_Sta 2;
BA_ "UserSigValidity" SG_ 2353205505 CDCU_CPE_Sta 3;
BA_ "Description" SG_ 2353205505 CDCU_CPE_Sta "CPE status";
BA_ "Version" SG_ 2353205505 CDCU_CPE_CpOffsetPC "21.05.02";
BA_ "RoutingFactor" SG_ 2353205505 CDCU_CPE_CpOffsetPC 2;
BA_ "UserSigValidity" SG_ 2353205505 CDCU_CPE_CpOffsetPC 3;
BA_ "Description" SG_ 2353205505 CDCU_CPE_CpOffsetPC "Brake pressure offset Request value (PC)";
BA_ "Version" SG_ 2353205505 CDCU_CPE_CpOffset "21.05.02";
BA_ "RoutingFactor" SG_ 2353205505 CDCU_CPE_CpOffset 2;
BA_ "UserSigValidity" SG_ 2353205505 CDCU_CPE_CpOffset 3;
BA_ "Description" SG_ 2353205505 CDCU_CPE_CpOffset "Brake factor offset Request value (Nm/bar)";
BA_ "Version" SG_ 2353205505 CDCU_BJDSta "21.05.02";
BA_ "RoutingFactor" SG_ 2353205505 CDCU_BJDSta 2;
BA_ "UserSigValidity" SG_ 2353205505 CDCU_BJDSta 3;
BA_ "Description" SG_ 2353205505 CDCU_BJDSta "Judder Detection Flag

0x0(No Event), 0x1(Event)";
BA_ "Version" SG_ 2353205505 CDCU_WrngLmpSta "22.07.06";
BA_ "RoutingFactor" SG_ 2353205505 CDCU_WrngLmpSta 2;
BA_ "UserSigValidity" SG_ 2353205505 CDCU_WrngLmpSta 3;
BA_ "Description" SG_ 2353205505 CDCU_WrngLmpSta "CDCU Warning Lamp Status";
BA_ "Version" SG_ 2164279809 IMU_Crc1Val "21.09.03";
BA_ "RoutingFactor" SG_ 2164279809 IMU_Crc1Val 0;
BA_ "UserSigValidity" SG_ 2164279809 IMU_Crc1Val 3;
BA_ "GenSigStartValue" SG_ 2164279809 IMU_Crc1Val 65535;
BA_ "Description" SG_ 2164279809 IMU_Crc1Val "The data area for CRC calculation is based on the data length (DLC) of the message DB.

The CRC shall be calculated over the entire data block (excluding the CRC bytes) including the user data, alive counter and Data ID



- CRC Polynomial (0x1021) , Ini";
BA_ "Version" SG_ 2164279809 IMU_AlvCnt1Val "21.09.03";
BA_ "RoutingFactor" SG_ 2164279809 IMU_AlvCnt1Val 0;
BA_ "UserSigValidity" SG_ 2164279809 IMU_AlvCnt1Val 3;
BA_ "Description" SG_ 2164279809 IMU_AlvCnt1Val "For the first transmission request for a data element the counter shall be initialized with 0 and shall be incremented by 1 for every subsequent send request. 

When the counter reaches the maximum value(0xFF), then it shall restart with 0 for the next s";
BA_ "Version" SG_ 2164279809 IMU_YawSigSta "20.03.05";
BA_ "RoutingFactor" SG_ 2164279809 IMU_YawSigSta 0;
BA_ "UserSigValidity" SG_ 2164279809 IMU_YawSigSta 3;
BA_ "GenSigStartValue" SG_ 2164279809 IMU_YawSigSta 2;
BA_ "Description" SG_ 2164279809 IMU_YawSigSta "This signal indicates failure status of yaw rate signal and yaw rate sensing element.



0000B : No failure 



xxx1B : IMU_Yawrate_failure



xx1xB : Initialization is running



x1xxB : Reserved



1xxxB : Reserved



This signal represents the physica";
BA_ "Version" SG_ 2164279809 IMU_LatAccelSigSta "20.03.05";
BA_ "RoutingFactor" SG_ 2164279809 IMU_LatAccelSigSta 0;
BA_ "UserSigValidity" SG_ 2164279809 IMU_LatAccelSigSta 3;
BA_ "GenSigStartValue" SG_ 2164279809 IMU_LatAccelSigSta 2;
BA_ "Description" SG_ 2164279809 IMU_LatAccelSigSta "This signal indicates failure status of lateral acceleration signal and sensing element.



0000B : No failure



xxx1B : IMU_Lateral acceleration failure



xx1xB : Initialization is running



x1xxB : Reserved



1xxxB : Reserved



This signal represe";
BA_ "Version" SG_ 2164279809 IMU_LongAccelSigSta "20.03.05";
BA_ "RoutingFactor" SG_ 2164279809 IMU_LongAccelSigSta 0;
BA_ "UserSigValidity" SG_ 2164279809 IMU_LongAccelSigSta 3;
BA_ "GenSigStartValue" SG_ 2164279809 IMU_LongAccelSigSta 2;
BA_ "Description" SG_ 2164279809 IMU_LongAccelSigSta "This signal indicates failure status of longitudinal acceleration signal and sensing element.



0000B : No failure 



xxx1B : IMU_Longitudial acceleration failure



xx1xB : Initialization is running



x1xxB : Reserved



1xxxB : Reserved



This sign";
BA_ "Version" SG_ 2164279809 IMU_VerAccelSigSta "20.03.05";
BA_ "RoutingFactor" SG_ 2164279809 IMU_VerAccelSigSta 0;
BA_ "UserSigValidity" SG_ 2164279809 IMU_VerAccelSigSta 3;
BA_ "GenSigStartValue" SG_ 2164279809 IMU_VerAccelSigSta 2;
BA_ "Description" SG_ 2164279809 IMU_VerAccelSigSta "This signal indicates failure status of  vertial acceleration signal and yaw rate sensing element.



0000B : No failure 



xxx1B : IMU_Vertial acceleration failure



xx1xB : Initialization is running



x1xxB : Reserved



1xxxB : Reserved



This sig";
BA_ "Version" SG_ 2164279809 IMU_McuVoltSta "20.03.05";
BA_ "RoutingFactor" SG_ 2164279809 IMU_McuVoltSta 0;
BA_ "UserSigValidity" SG_ 2164279809 IMU_McuVoltSta 3;
BA_ "Description" SG_ 2164279809 IMU_McuVoltSta "This signal indicates the failure status of MCU.



0000B : No failure



xxx1B : MCU failure



xx1xB : Under voltage detected



x1xxB : Over voltage detected



1xxxB : Bus off failure



The status information(xxx1B) occurs when MCU error is detected";
BA_ "Version" SG_ 2164279809 IMU_AcuRstSta "20.03.05";
BA_ "RoutingFactor" SG_ 2164279809 IMU_AcuRstSta 0;
BA_ "UserSigValidity" SG_ 2164279809 IMU_AcuRstSta 3;
BA_ "Description" SG_ 2164279809 IMU_AcuRstSta "This signal indicates the status of IMU.



0000B : Normal mode 



xxx1B : IMU Reset mode



xx1xB : Reserved



x1xxB : Reserved



1xxxB : Reserved



If ACU reset is required, ACU will send IMU RESET bit(XXX1B) up to 30 times and perform a reset. If ";
BA_ "Version" SG_ 2164279809 IMU_SnsrTyp "20.03.05";
BA_ "RoutingFactor" SG_ 2164279809 IMU_SnsrTyp 0;
BA_ "UserSigValidity" SG_ 2164279809 IMU_SnsrTyp 3;
BA_ "GenSigStartValue" SG_ 2164279809 IMU_SnsrTyp 2;
BA_ "Description" SG_ 2164279809 IMU_SnsrTyp "This signal indicates supported signals that are correspond to sensor type.

0001B = IMU (yaw rate and lateral acceleration)

0010B = IMU (yaw rate, lateral and longitudinal acceleration)

0100B = IMU (yaw / roll rate, lateral and longitudinal accelerati";
BA_ "Version" SG_ 2164279809 IMU_RollSigSta "20.03.05";
BA_ "RoutingFactor" SG_ 2164279809 IMU_RollSigSta 0;
BA_ "UserSigValidity" SG_ 2164279809 IMU_RollSigSta 3;
BA_ "GenSigStartValue" SG_ 2164279809 IMU_RollSigSta 2;
BA_ "Description" SG_ 2164279809 IMU_RollSigSta "This signal indicates failure status of roll rate signal and roll rate sensing element.



0000B : No failure 



xxx1B : IMU_Roll rate failure



xx1xB : Initialization is running



x1xxB : Reserved



1xxxB : Reserved



This signal represents the phy";
BA_ "Version" SG_ 2164279811 IMU_SeralNumVal "20.03.05";
BA_ "RoutingFactor" SG_ 2164279811 IMU_SeralNumVal 0;
BA_ "UserSigValidity" SG_ 2164279811 IMU_SeralNumVal 3;
BA_ "Description" SG_ 2164279811 IMU_SeralNumVal "IMU serial number in range of 



0x000000000000 = 0......0xFFFFFFFFFFFF

¡ØInitial value shall be actual value

¡ØThis information is only for chipset with yaw sensor.";
BA_ "Version" SG_ 2353205506 CBCR_SocConsumptionReq "24.09.00";
BA_ "RoutingFactor" SG_ 2353205506 CBCR_SocConsumptionReq 2;
BA_ "UserSigValidity" SG_ 2353205506 CBCR_SocConsumptionReq 3;
BA_ "Description" SG_ 2353205506 CBCR_SocConsumptionReq "This signal requests for high-voltage battery consumption.



When EV vehicle travels downhill continuously, Brake hardware can be damaged if regenerative braking does not work due to fully charged high-voltage battery.";
BA_ "Version" SG_ 2353205506 CBCR_CluDispMsgSta "24.09.00";
BA_ "RoutingFactor" SG_ 2353205506 CBCR_CluDispMsgSta 2;
BA_ "UserSigValidity" SG_ 2353205506 CBCR_CluDispMsgSta 3;
BA_ "Description" SG_ 2353205506 CBCR_CluDispMsgSta "Disp1(0x1) : Start compulsory battery consumption

Disp2(0x2) : End compulsory battery consumption

Disp3(0x3) : Gear change request from N to D";
BA_ "Version" SG_ 942 AMP_Beep1VolumeStep "19.02.03";
BA_ "NetworkRequest" SG_ 942 AMP_Beep1VolumeStep 0;
BA_ "UserSigValidity" SG_ 942 AMP_Beep1VolumeStep 1;
BA_ "GenSigStartValue" SG_ 942 AMP_Beep1VolumeStep 255;
BA_ "GenSigSendType" SG_ 942 AMP_Beep1VolumeStep 4;
BA_ "Description" SG_ 942 AMP_Beep1VolumeStep "16.03.03_";
BA_ "Version" SG_ 942 AMP_Analog_OutputCh_Select "21.11.00";
BA_ "UserSigValidity" SG_ 942 AMP_Analog_OutputCh_Select 1;
BA_ "GenSigSendType" SG_ 942 AMP_Analog_OutputCh_Select 4;
BA_ "Description" SG_ 942 AMP_Analog_OutputCh_Select "Command for Set Analog Output Channel to identify which Speakers will output Sound

- per bit, 0 means 'Not Output Channel' and 1 means 'Output Channel'

bit0 : FL / bit1 : FR / bit2 : RL / bit3 : RR / bit4 : CTR / bit5 : Surround L /

bit6 : Surround R ";
BA_ "Version" SG_ 942 AMP_Beep1_OutputCh_Select "21.11.00";
BA_ "UserSigValidity" SG_ 942 AMP_Beep1_OutputCh_Select 1;
BA_ "GenSigStartValue" SG_ 942 AMP_Beep1_OutputCh_Select 65535;
BA_ "GenSigSendType" SG_ 942 AMP_Beep1_OutputCh_Select 4;
BA_ "Description" SG_ 942 AMP_Beep1_OutputCh_Select "Command for Set Beep1 Output Channel to identify which Speakers will output Sound

- per bit, 0 means 'Not Output Channel' and 1 means 'Output Channel'

bit0 : FL / bit1 : FR / bit2 : RL / bit3 : RR / bit4 : CTR / bit5 : Surround L /

bit6 : Surround R /";
BA_ "Version" SG_ 942 AMP_Beep1KBDVolumeStep "20.06.01";
BA_ "UserSigValidity" SG_ 942 AMP_Beep1KBDVolumeStep 1;
BA_ "GenSigStartValue" SG_ 942 AMP_Beep1KBDVolumeStep 255;
BA_ "GenSigSendType" SG_ 942 AMP_Beep1KBDVolumeStep 4;
BA_ "Description" SG_ 942 AMP_Beep1KBDVolumeStep "Command for AVN keyboard Touch Beep Sound Volume Setting 

-range : 0 ~ max

-max : value of AMP_MaxBeep1VolumeState

This Signal's Feedback is AMP_Beep1KBDVolumeState@AMP";
BA_ "Version" SG_ 942 AMP_SPDIF_OutputCh_Select "21.11.00";
BA_ "UserSigValidity" SG_ 942 AMP_SPDIF_OutputCh_Select 1;
BA_ "GenSigStartValue" SG_ 942 AMP_SPDIF_OutputCh_Select 255;
BA_ "GenSigSendType" SG_ 942 AMP_SPDIF_OutputCh_Select 4;
BA_ "Description" SG_ 942 AMP_SPDIF_OutputCh_Select "Command for Set SPDIF Output Channel to identify which Speakers will output Sound

- per bit, 0 means 'Not Output Channel' and 1 means 'Output Channel'

bit0 : FL / bit1 : FR / bit2 : RL / bit3 : RR / bit4 : CTR / bit5 : Surround L /

bit6 : Surround R /";
BA_ "Version" SG_ 2164279810 IMU_YawRtVal "20.03.05";
BA_ "RoutingFactor" SG_ 2164279810 IMU_YawRtVal 0;
BA_ "UserSigValidity" SG_ 2164279810 IMU_YawRtVal 3;
BA_ "GenSigStartValue" SG_ 2164279810 IMU_YawRtVal 32768;
BA_ "Description" SG_ 2164279810 IMU_YawRtVal "This signal indicates Information regarding yaw rate.



physical range : -163.84..163.83 ¢ª/s = 0000H..FFFEh



Conversion : (PH) = ((HEX)-8000H)*0.005[¢ª/s/digit]



                            = (HEX)*0.005[¢ª/s/digit] - 163.84[¢ª/s]



              ";
BA_ "Version" SG_ 2164279810 IMU_LatAccelVal "20.03.05";
BA_ "RoutingFactor" SG_ 2164279810 IMU_LatAccelVal 0;
BA_ "UserSigValidity" SG_ 2164279810 IMU_LatAccelVal 3;
BA_ "GenSigStartValue" SG_ 2164279810 IMU_LatAccelVal 32768;
BA_ "Description" SG_ 2164279810 IMU_LatAccelVal "This signal indicates Information regarding lateral acceleration.



physical range : -4.1768g..4.1765g = 0000H..FFFEh



Conversion : (PH) = ((HEX)-8000H)*0.000127465[g/digit]



                            = (HEX)*0.000127465[g/digit] - 4.17677312[g]

";
BA_ "Version" SG_ 2164279810 IMU_LongAccelVal "20.03.05";
BA_ "RoutingFactor" SG_ 2164279810 IMU_LongAccelVal 0;
BA_ "UserSigValidity" SG_ 2164279810 IMU_LongAccelVal 3;
BA_ "GenSigStartValue" SG_ 2164279810 IMU_LongAccelVal 32768;
BA_ "Description" SG_ 2164279810 IMU_LongAccelVal "This signal indicates information regarding longitudinal acceleration.



physical range : -4.1768g..4.1765g = 0000H..FFFEh



Conversion : (PH) = ((HEX)-8000H)*0.000127465[g/digit]



                            = (HEX)*0.000127465[g/digit] - 4.17677312";
BA_ "Version" SG_ 2164279810 IMU_SnsrTempVal "20.03.05";
BA_ "RoutingFactor" SG_ 2164279810 IMU_SnsrTempVal 0;
BA_ "UserSigValidity" SG_ 2164279810 IMU_SnsrTempVal 3;
BA_ "GenSigStartValue" SG_ 2164279810 IMU_SnsrTempVal 68;
BA_ "Description" SG_ 2164279810 IMU_SnsrTempVal "The temperature is measured on sensing element chip in ACU, so it may be different from the display indicator temperature of the vehicle.



Physical range: -68¡ÆC = 00h, +60 ¡ÆC = 80h, +187¡ÆC = FFh



Quantization LSB: 1[¡ÆC/digit]



Temperature [¡ÆC]";
BA_ "Version" SG_ 2164279812 IMU_RollRtVal "20.03.05";
BA_ "RoutingFactor" SG_ 2164279812 IMU_RollRtVal 0;
BA_ "UserSigValidity" SG_ 2164279812 IMU_RollRtVal 3;
BA_ "GenSigStartValue" SG_ 2164279812 IMU_RollRtVal 32768;
BA_ "Description" SG_ 2164279812 IMU_RollRtVal "This signal indicates Information regarding Roll rate.



physical range : -163.84..163.83 ¢ª/s = 0000H..FFFEh



Conversion : (PH) = ((HEX)-8000H)*0.005[¢ª/s/digit]



                            = (HEX)*0.005[¢ª/s/digit] - 163.84[¢ª/s]



             ";
BA_ "Version" SG_ 2164279812 IMU_VerAccelVal "20.03.05";
BA_ "RoutingFactor" SG_ 2164279812 IMU_VerAccelVal 0;
BA_ "UserSigValidity" SG_ 2164279812 IMU_VerAccelVal 3;
BA_ "GenSigStartValue" SG_ 2164279812 IMU_VerAccelVal 32768;
BA_ "Description" SG_ 2164279812 IMU_VerAccelVal "This signal indicates Information regarding Vertical acceleration.



physical range : -4.1768g..4.1765g = 0000H..FFFEh



Conversion : (PH) = ((HEX)-8000H)*0.000127465[g/digit]



                            = (HEX)*0.000127465[g/digit] - 4.17677312[g]

";
BA_ "Version" SG_ 939 PSB_Crc1Val "21.09.03";
BA_ "UserSigValidity" SG_ 939 PSB_Crc1Val 0;
BA_ "Description" SG_ 939 PSB_Crc1Val "The data area for CRC calculation is based on the data length (DLC) of the message DB.

The CRC shall be calculated over the entire data block (excluding the CRC bytes) including the user data, alive counter and Data ID 

 

- CRC Polynomial (0x1D) , Ini";
BA_ "Version" SG_ 939 PSB_AlvCnt1Val "21.09.03";
BA_ "UserSigValidity" SG_ 939 PSB_AlvCnt1Val 0;
BA_ "Description" SG_ 939 PSB_AlvCnt1Val "For the first transmission request for a data element the counter shall be initialized with 0 and shall be incremented by 1

for every subsequent send request. When the counter reaches the maximum value(0xE), then it shall restart with 0 for the next sen";
BA_ "Version" SG_ 939 PSB_LHFlrSta "18.02.03";
BA_ "UserSigValidity" SG_ 939 PSB_LHFlrSta 0;
BA_ "Description" SG_ 939 PSB_LHFlrSta "Information about availability of PSB_LH (LH Pre-Safe S/Belt).";
BA_ "Version" SG_ 939 PSB_LHActvSta "18.02.03";
BA_ "UserSigValidity" SG_ 939 PSB_LHActvSta 0;
BA_ "Description" SG_ 939 PSB_LHActvSta "Seat belt active state. This signal is for the monitoring of Pre-Safe S/Belt.

If there is a request, but no realization by the Pre-Safe S/Belt -> failure entry in the SCC(Radar).";
BA_ "Version" SG_ 939 PSB_RHFlrSta "18.02.03";
BA_ "UserSigValidity" SG_ 939 PSB_RHFlrSta 0;
BA_ "Description" SG_ 939 PSB_RHFlrSta "Information about availability of PSB_RH (LH Pre-Safe S/Belt).";
BA_ "Version" SG_ 939 PSB_RHActvSta "18.02.03";
BA_ "UserSigValidity" SG_ 939 PSB_RHActvSta 0;
BA_ "Description" SG_ 939 PSB_RHActvSta "Seat belt active state. This signal is for the monitoring of Pre-Safe S/Belt.

If there is a request, but no realization by the Pre-Safe S/Belt -> failure entry in the SCC(Radar).";
BA_ "Version" SG_ 939 PSB_ActForAcu "18.02.03";
BA_ "UserSigValidity" SG_ 939 PSB_ActForAcu 0;
BA_ "Description" SG_ 939 PSB_ActForAcu "This signal indicates status of Pre-Safe S/Belt activation by ACU commends.";
BA_ "Version" SG_ 939 PSB_HapticWarnSta "22.04.02";
BA_ "UserSigValidity" SG_ 939 PSB_HapticWarnSta 0;
BA_ "Description" SG_ 939 PSB_HapticWarnSta "This signal indicates sattus of Pre-active S/Belt Haptic activation by HDP commends";
BA_ "Version" SG_ 939 PSB_RHActForPss "21.04.00";
BA_ "UserSigValidity" SG_ 939 PSB_RHActForPss 0;
BA_ "Description" SG_ 939 PSB_RHActForPss "Seat belt active state. 

This signal is for the monitoring of Pre-Safe S/Belt  in conjunction with PSS.

If there is a request, but no realization by the Pre-Safe S/Belt -> failure entry in the SCC(Radar).";
BA_ "Version" SG_ 939 PSB_HDPSpprtSWVer "22.04.02";
BA_ "UserSigValidity" SG_ 939 PSB_HDPSpprtSWVer 0;
BA_ "Description" SG_ 939 PSB_HDPSpprtSWVer "This signal indicates Requirement Spec Version about PSB haptic active by HDP";
BA_ "Version" SG_ 939 PSB_LHActForPss "21.04.00";
BA_ "UserSigValidity" SG_ 939 PSB_LHActForPss 0;
BA_ "Description" SG_ 939 PSB_LHActForPss "Seat belt active state. 

This signal is for the monitoring of Pre-Safe S/Belt in conjunction with PSS.

If there is a request, but no realization by the Pre-Safe S/Belt -> failure entry in the SCC(Radar).";
BA_ "Version" SG_ 935 SCM_AnySwOnEv "24.10.05";
BA_ "NetworkRequestHoldingTime" SG_ 935 SCM_AnySwOnEv 5000;
BA_ "NetworkRequest" SG_ 935 SCM_AnySwOnEv 0;
BA_ "UserSigValidity" SG_ 935 SCM_AnySwOnEv 0;
BA_ "GenSigSendType" SG_ 935 SCM_AnySwOnEv 4;
BA_ "Description" SG_ 935 SCM_AnySwOnEv "Send the signal when column tilt/tele switch ON occurs";
BA_ "Version" SG_ 2239851012 RSPA_DCTTrgtTqVal "19.06.00";
BA_ "RoutingFactor" SG_ 2239851012 RSPA_DCTTrgtTqVal 5;
BA_ "UserSigValidity" SG_ 2239851012 RSPA_DCTTrgtTqVal 3;
BA_ "Description" SG_ 2239851012 RSPA_DCTTrgtTqVal "RSPA request DCT torque value (Nm)

Init value : 00h

If MSB is 1, this signal is - value.

else, this signal is +value.

0~10bit is used for absolute value.";
BA_ "Version" SG_ 2239851012 MRA_BtnDispSta "24.10.05";
BA_ "RoutingFactor" SG_ 2239851012 MRA_BtnDispSta 5;
BA_ "UserSigValidity" SG_ 2239851012 MRA_BtnDispSta 3;
BA_ "Description" SG_ 2239851012 MRA_BtnDispSta "Request display of MRA Button";
BA_ "Version" SG_ 2239851012 RSPA_HdLmpReq "20.10.00";
BA_ "RoutingFactor" SG_ 2239851012 RSPA_HdLmpReq 5;
BA_ "UserSigValidity" SG_ 2239851012 RSPA_HdLmpReq 3;
BA_ "Description" SG_ 2239851012 RSPA_HdLmpReq "Head lamp request of RSPA";
BA_ "Version" SG_ 2239851012 RSPA_BtnDispSta "24.02.00";
BA_ "RoutingFactor" SG_ 2239851012 RSPA_BtnDispSta 5;
BA_ "UserSigValidity" SG_ 2239851012 RSPA_BtnDispSta 3;
BA_ "Description" SG_ 2239851012 RSPA_BtnDispSta "Request display of RSPA Button";
BA_ "Version" SG_ 2239851012 RSPA_OSMirFoldReq "19.08.08";
BA_ "RoutingFactor" SG_ 2239851012 RSPA_OSMirFoldReq 5;
BA_ "UserSigValidity" SG_ 2239851012 RSPA_OSMirFoldReq 3;
BA_ "Description" SG_ 2239851012 RSPA_OSMirFoldReq "OS Mirror folding/unfolding request of RSPA";
BA_REL_ "GenSigTimeoutTime" BU_SG_REL_ ARS SG_ 894 PDCex_4thRLSBRMatSw 1500;
BA_REL_ "GenSigTimeoutTime" BU_SG_REL_ FCS SG_ 894 PDCex_4thRLSBRMatSw 1500;
BA_REL_ "GenSigTimeoutTime" BU_SG_REL_ WPC2 SG_ 894 PDCex_4thRLSBRMatSw 1500;
BA_REL_ "GenSigTimeoutTime" BU_SG_REL_ ARS SG_ 894 PDCex_4thRRSBRMatSw 1500;
BA_REL_ "GenSigTimeoutTime" BU_SG_REL_ FCS SG_ 894 PDCex_4thRRSBRMatSw 1500;
BA_REL_ "GenSigTimeoutTime" BU_SG_REL_ WPC2 SG_ 894 PDCex_4thRRSBRMatSw 1500;
BA_REL_ "GenSigTimeoutTime" BU_SG_REL_ ARS SG_ 894 PDCex_4thRLSeatBeltSW 1500;
BA_REL_ "GenSigTimeoutTime" BU_SG_REL_ FCS SG_ 894 PDCex_4thRLSeatBeltSW 1500;
BA_REL_ "GenSigTimeoutTime" BU_SG_REL_ WPC2 SG_ 894 PDCex_4thRLSeatBeltSW 1500;
BA_REL_ "GenSigTimeoutTime" BU_SG_REL_ ARS SG_ 894 PDCex_4thRCSeatBeltSW 1500;
BA_REL_ "GenSigTimeoutTime" BU_SG_REL_ FCS SG_ 894 PDCex_4thRCSeatBeltSW 1500;
BA_REL_ "GenSigTimeoutTime" BU_SG_REL_ WPC2 SG_ 894 PDCex_4thRCSeatBeltSW 1500;
BA_REL_ "GenSigTimeoutTime" BU_SG_REL_ ARS SG_ 894 PDCex_4thRRSeatBeltSW 1500;
BA_REL_ "GenSigTimeoutTime" BU_SG_REL_ FCS SG_ 894 PDCex_4thRRSeatBeltSW 1500;
BA_REL_ "GenSigTimeoutTime" BU_SG_REL_ WPC2 SG_ 894 PDCex_4thRRSeatBeltSW 1500;
BA_REL_ "GenSigTimeoutTime" BU_SG_REL_ ARS SG_ 894 PDCex_FuelDrOpenSta 1500;
BA_REL_ "GenSigTimeoutTime" BU_SG_REL_ FCS SG_ 894 PDCex_FuelDrOpenSta 1500;
BA_REL_ "GenSigTimeoutTime" BU_SG_REL_ WPC2 SG_ 894 PDCex_FuelDrOpenSta 1500;
BA_REL_ "GenSigTimeoutTime" BU_SG_REL_ ARS SG_ 894 PDCex_PSDPwrModeOffSwSta 1500;
BA_REL_ "GenSigTimeoutTime" BU_SG_REL_ FCS SG_ 894 PDCex_PSDPwrModeOffSwSta 1500;
BA_REL_ "GenSigTimeoutTime" BU_SG_REL_ WPC2 SG_ 894 PDCex_PSDPwrModeOffSwSta 1500;
BA_REL_ "GenSigTimeoutTime" BU_SG_REL_ CGW_CCU SG_ 1836 RWPC_GST_Byte0 0;
BA_REL_ "GenSigTimeoutTime" BU_SG_REL_ CGW_CCU SG_ 1836 RWPC_GST_Byte2 0;
BA_REL_ "GenSigTimeoutTime" BU_SG_REL_ CGW_CCU SG_ 1836 RWPC_GST_Byte3 0;
BA_REL_ "GenSigTimeoutTime" BU_SG_REL_ CGW_CCU SG_ 1836 RWPC_GST_Byte4 0;
BA_REL_ "GenSigTimeoutTime" BU_SG_REL_ CGW_CCU SG_ 1836 RWPC_GST_Byte5 0;
BA_REL_ "GenSigTimeoutTime" BU_SG_REL_ CGW_CCU SG_ 1836 RWPC_GST_Byte6 0;
BA_REL_ "GenSigTimeoutTime" BU_SG_REL_ CGW_CCU SG_ 1836 RWPC_GST_Byte7 0;
BA_REL_ "GenSigTimeoutTime" BU_SG_REL_ CGW_CCU SG_ 1836 RWPC_GST_Byte1 0;
BA_REL_ "GenSigTimeoutTime" BU_SG_REL_ CGW_CCU SG_ 1837 WPC_GST_Byte0 0;
BA_REL_ "GenSigTimeoutTime" BU_SG_REL_ CGW_CCU SG_ 1837 WPC_GST_Byte2 0;
BA_REL_ "GenSigTimeoutTime" BU_SG_REL_ CGW_CCU SG_ 1837 WPC_GST_Byte3 0;
BA_REL_ "GenSigTimeoutTime" BU_SG_REL_ CGW_CCU SG_ 1837 WPC_GST_Byte4 0;
BA_REL_ "GenSigTimeoutTime" BU_SG_REL_ CGW_CCU SG_ 1837 WPC_GST_Byte5 0;
BA_REL_ "GenSigTimeoutTime" BU_SG_REL_ CGW_CCU SG_ 1837 WPC_GST_Byte6 0;
BA_REL_ "GenSigTimeoutTime" BU_SG_REL_ CGW_CCU SG_ 1837 WPC_GST_Byte7 0;
BA_REL_ "GenSigTimeoutTime" BU_SG_REL_ CGW_CCU SG_ 1837 WPC_GST_Byte1 0;
BA_REL_ "GenSigTimeoutTime" BU_SG_REL_ CGW_CCU SG_ 1833 PSS_3RD_GST_Byte0 0;
BA_REL_ "GenSigTimeoutTime" BU_SG_REL_ CGW_CCU SG_ 1833 PSS_3RD_GST_Byte2 0;
BA_REL_ "GenSigTimeoutTime" BU_SG_REL_ CGW_CCU SG_ 1833 PSS_3RD_GST_Byte3 0;
BA_REL_ "GenSigTimeoutTime" BU_SG_REL_ CGW_CCU SG_ 1833 PSS_3RD_GST_Byte4 0;
BA_REL_ "GenSigTimeoutTime" BU_SG_REL_ CGW_CCU SG_ 1833 PSS_3RD_GST_Byte5 0;
BA_REL_ "GenSigTimeoutTime" BU_SG_REL_ CGW_CCU SG_ 1833 PSS_3RD_GST_Byte6 0;
BA_REL_ "GenSigTimeoutTime" BU_SG_REL_ CGW_CCU SG_ 1833 PSS_3RD_GST_Byte7 0;
BA_REL_ "GenSigTimeoutTime" BU_SG_REL_ CGW_CCU SG_ 1833 PSS_3RD_GST_Byte1 0;
BA_REL_ "GenSigTimeoutTime" BU_SG_REL_ CGW_CCU SG_ 1835 WPC2_GST_Byte0 0;
BA_REL_ "GenSigTimeoutTime" BU_SG_REL_ CGW_CCU SG_ 1835 WPC2_GST_Byte2 0;
BA_REL_ "GenSigTimeoutTime" BU_SG_REL_ CGW_CCU SG_ 1835 WPC2_GST_Byte3 0;
BA_REL_ "GenSigTimeoutTime" BU_SG_REL_ CGW_CCU SG_ 1835 WPC2_GST_Byte4 0;
BA_REL_ "GenSigTimeoutTime" BU_SG_REL_ CGW_CCU SG_ 1835 WPC2_GST_Byte5 0;
BA_REL_ "GenSigTimeoutTime" BU_SG_REL_ CGW_CCU SG_ 1835 WPC2_GST_Byte6 0;
BA_REL_ "GenSigTimeoutTime" BU_SG_REL_ CGW_CCU SG_ 1835 WPC2_GST_Byte7 0;
BA_REL_ "GenSigTimeoutTime" BU_SG_REL_ CGW_CCU SG_ 1835 WPC2_GST_Byte1 0;
BA_REL_ "GenSigTimeoutTime" BU_SG_REL_ RWPC SG_ 1828 GST_RWPC_Byte0 0;
BA_REL_ "GenSigTimeoutTime" BU_SG_REL_ RWPC SG_ 1828 GST_RWPC_Byte2 0;
BA_REL_ "GenSigTimeoutTime" BU_SG_REL_ RWPC SG_ 1828 GST_RWPC_Byte3 0;
BA_REL_ "GenSigTimeoutTime" BU_SG_REL_ RWPC SG_ 1828 GST_RWPC_Byte4 0;
BA_REL_ "GenSigTimeoutTime" BU_SG_REL_ RWPC SG_ 1828 GST_RWPC_Byte5 0;
BA_REL_ "GenSigTimeoutTime" BU_SG_REL_ RWPC SG_ 1828 GST_RWPC_Byte6 0;
BA_REL_ "GenSigTimeoutTime" BU_SG_REL_ RWPC SG_ 1828 GST_RWPC_Byte7 0;
BA_REL_ "GenSigTimeoutTime" BU_SG_REL_ RWPC SG_ 1828 GST_RWPC_Byte1 0;
BA_REL_ "GenSigTimeoutTime" BU_SG_REL_ WPC SG_ 1829 GST_WPC_Byte0 0;
BA_REL_ "GenSigTimeoutTime" BU_SG_REL_ WPC SG_ 1829 GST_WPC_Byte2 0;
BA_REL_ "GenSigTimeoutTime" BU_SG_REL_ WPC SG_ 1829 GST_WPC_Byte3 0;
BA_REL_ "GenSigTimeoutTime" BU_SG_REL_ WPC SG_ 1829 GST_WPC_Byte4 0;
BA_REL_ "GenSigTimeoutTime" BU_SG_REL_ WPC SG_ 1829 GST_WPC_Byte5 0;
BA_REL_ "GenSigTimeoutTime" BU_SG_REL_ WPC SG_ 1829 GST_WPC_Byte6 0;
BA_REL_ "GenSigTimeoutTime" BU_SG_REL_ WPC SG_ 1829 GST_WPC_Byte7 0;
BA_REL_ "GenSigTimeoutTime" BU_SG_REL_ WPC SG_ 1829 GST_WPC_Byte1 0;
BA_REL_ "GenSigTimeoutTime" BU_SG_REL_ PFSU SG_ 1825 GST_PSS_3RD_Byte0 0;
BA_REL_ "GenSigTimeoutTime" BU_SG_REL_ PFSU SG_ 1825 GST_PSS_3RD_Byte2 0;
BA_REL_ "GenSigTimeoutTime" BU_SG_REL_ PFSU SG_ 1825 GST_PSS_3RD_Byte3 0;
BA_REL_ "GenSigTimeoutTime" BU_SG_REL_ PFSU SG_ 1825 GST_PSS_3RD_Byte4 0;
BA_REL_ "GenSigTimeoutTime" BU_SG_REL_ PFSU SG_ 1825 GST_PSS_3RD_Byte5 0;
BA_REL_ "GenSigTimeoutTime" BU_SG_REL_ PFSU SG_ 1825 GST_PSS_3RD_Byte6 0;
BA_REL_ "GenSigTimeoutTime" BU_SG_REL_ PFSU SG_ 1825 GST_PSS_3RD_Byte7 0;
BA_REL_ "GenSigTimeoutTime" BU_SG_REL_ PFSU SG_ 1825 GST_PSS_3RD_Byte1 0;
BA_REL_ "GenSigTimeoutTime" BU_SG_REL_ WPC2 SG_ 1827 GST_WPC2_Byte0 0;
BA_REL_ "GenSigTimeoutTime" BU_SG_REL_ WPC2 SG_ 1827 GST_WPC2_Byte2 0;
BA_REL_ "GenSigTimeoutTime" BU_SG_REL_ WPC2 SG_ 1827 GST_WPC2_Byte3 0;
BA_REL_ "GenSigTimeoutTime" BU_SG_REL_ WPC2 SG_ 1827 GST_WPC2_Byte4 0;
BA_REL_ "GenSigTimeoutTime" BU_SG_REL_ WPC2 SG_ 1827 GST_WPC2_Byte5 0;
BA_REL_ "GenSigTimeoutTime" BU_SG_REL_ WPC2 SG_ 1827 GST_WPC2_Byte6 0;
BA_REL_ "GenSigTimeoutTime" BU_SG_REL_ WPC2 SG_ 1827 GST_WPC2_Byte7 0;
BA_REL_ "GenSigTimeoutTime" BU_SG_REL_ WPC2 SG_ 1827 GST_WPC2_Byte1 0;
BA_REL_ "GenSigTimeoutTime" BU_SG_REL_ CGW_CCU SG_ 1818 RLHVU_GST_Byte0 0;
BA_REL_ "GenSigTimeoutTime" BU_SG_REL_ CGW_CCU SG_ 1818 RLHVU_GST_Byte2 0;
BA_REL_ "GenSigTimeoutTime" BU_SG_REL_ CGW_CCU SG_ 1818 RLHVU_GST_Byte3 0;
BA_REL_ "GenSigTimeoutTime" BU_SG_REL_ CGW_CCU SG_ 1818 RLHVU_GST_Byte4 0;
BA_REL_ "GenSigTimeoutTime" BU_SG_REL_ CGW_CCU SG_ 1818 RLHVU_GST_Byte5 0;
BA_REL_ "GenSigTimeoutTime" BU_SG_REL_ CGW_CCU SG_ 1818 RLHVU_GST_Byte6 0;
BA_REL_ "GenSigTimeoutTime" BU_SG_REL_ CGW_CCU SG_ 1818 RLHVU_GST_Byte7 0;
BA_REL_ "GenSigTimeoutTime" BU_SG_REL_ CGW_CCU SG_ 1818 RLHVU_GST_Byte1 0;
BA_REL_ "GenSigTimeoutTime" BU_SG_REL_ BLTN_CAM SG_ 858 AST_CrashUnlockCmd 1500;
BA_REL_ "GenSigTimeoutTime" BU_SG_REL_ ALBCU SG_ 858 Warn_AsstDrSwSta_SBCM 1500;
BA_REL_ "GenSigTimeoutTime" BU_SG_REL_ ATS SG_ 858 Warn_AsstDrSwSta_SBCM 1500;
BA_REL_ "GenSigTimeoutTime" BU_SG_REL_ BLTN_CAM SG_ 858 Warn_AsstDrSwSta_SBCM 1500;
BA_REL_ "GenSigTimeoutTime" BU_SG_REL_ GW_APSU SG_ 858 Warn_AsstDrSwSta_SBCM 1500;
BA_REL_ "GenSigTimeoutTime" BU_SG_REL_ GW_RLPSU SG_ 858 Warn_AsstDrSwSta_SBCM 1500;
BA_REL_ "GenSigTimeoutTime" BU_SG_REL_ GW_RRPSU SG_ 858 Warn_AsstDrSwSta_SBCM 1500;
BA_REL_ "GenSigTimeoutTime" BU_SG_REL_ PSB SG_ 858 Warn_AsstDrSwSta_SBCM 1500;
BA_REL_ "GenSigTimeoutTime" BU_SG_REL_ RWPC SG_ 858 Warn_AsstDrSwSta_SBCM 1500;
BA_REL_ "GenSigTimeoutTime" BU_SG_REL_ WPC SG_ 858 Warn_AsstDrSwSta_SBCM 1500;
BA_REL_ "GenSigTimeoutTime" BU_SG_REL_ WPC2 SG_ 858 Warn_AsstDrSwSta_SBCM 1500;
BA_REL_ "GenSigTimeoutTime" BU_SG_REL_ ATS SG_ 858 DoorLock_AsstDrUnLkSta_SBCM 1500;
BA_REL_ "GenSigTimeoutTime" BU_SG_REL_ vHS_B2 SG_ 863 Ast_SHVU_DiagMode 1500;
BA_REL_ "GenSigTimeoutTime" BU_SG_REL_ BLTN_CAM SG_ 862 RL_CrashUnlockCmd 1500;
BA_REL_ "GenSigTimeoutTime" BU_SG_REL_ ATS SG_ 862 Warn_RrLftDrSwSta_SBCM 1500;
BA_REL_ "GenSigTimeoutTime" BU_SG_REL_ BLTN_CAM SG_ 862 Warn_RrLftDrSwSta_SBCM 1500;
BA_REL_ "GenSigTimeoutTime" BU_SG_REL_ GW_APSU SG_ 862 Warn_RrLftDrSwSta_SBCM 1500;
BA_REL_ "GenSigTimeoutTime" BU_SG_REL_ GW_RLPSU SG_ 862 Warn_RrLftDrSwSta_SBCM 1500;
BA_REL_ "GenSigTimeoutTime" BU_SG_REL_ GW_RRPSU SG_ 862 Warn_RrLftDrSwSta_SBCM 1500;
BA_REL_ "GenSigTimeoutTime" BU_SG_REL_ RWPC SG_ 862 Warn_RrLftDrSwSta_SBCM 1500;
BA_REL_ "GenSigTimeoutTime" BU_SG_REL_ WPC SG_ 862 Warn_RrLftDrSwSta_SBCM 1500;
BA_REL_ "GenSigTimeoutTime" BU_SG_REL_ WPC2 SG_ 862 Warn_RrLftDrSwSta_SBCM 1500;
BA_REL_ "GenSigTimeoutTime" BU_SG_REL_ ATS SG_ 862 DoorLock_RrLftDrUnLkSta_SBCM 1500;
BA_REL_ "GenSigTimeoutTime" BU_SG_REL_ RLHV SG_ 1810 GST_RLHVU_Byte0 0;
BA_REL_ "GenSigTimeoutTime" BU_SG_REL_ RLHV SG_ 1810 GST_RLHVU_Byte2 0;
BA_REL_ "GenSigTimeoutTime" BU_SG_REL_ RLHV SG_ 1810 GST_RLHVU_Byte3 0;
BA_REL_ "GenSigTimeoutTime" BU_SG_REL_ RLHV SG_ 1810 GST_RLHVU_Byte4 0;
BA_REL_ "GenSigTimeoutTime" BU_SG_REL_ RLHV SG_ 1810 GST_RLHVU_Byte5 0;
BA_REL_ "GenSigTimeoutTime" BU_SG_REL_ RLHV SG_ 1810 GST_RLHVU_Byte6 0;
BA_REL_ "GenSigTimeoutTime" BU_SG_REL_ RLHV SG_ 1810 GST_RLHVU_Byte7 0;
BA_REL_ "GenSigTimeoutTime" BU_SG_REL_ RLHV SG_ 1810 GST_RLHVU_Byte1 0;
BA_REL_ "GenSigTimeoutTime" BU_SG_REL_ CGW_CCU SG_ 1806 AHV_SHVU_FR_GST_Byte0 0;
BA_REL_ "GenSigTimeoutTime" BU_SG_REL_ CGW_CCU SG_ 1806 AHV_SHVU_FR_GST_Byte2 0;
BA_REL_ "GenSigTimeoutTime" BU_SG_REL_ CGW_CCU SG_ 1806 AHV_SHVU_FR_GST_Byte3 0;
BA_REL_ "GenSigTimeoutTime" BU_SG_REL_ CGW_CCU SG_ 1806 AHV_SHVU_FR_GST_Byte4 0;
BA_REL_ "GenSigTimeoutTime" BU_SG_REL_ CGW_CCU SG_ 1806 AHV_SHVU_FR_GST_Byte5 0;
BA_REL_ "GenSigTimeoutTime" BU_SG_REL_ CGW_CCU SG_ 1806 AHV_SHVU_FR_GST_Byte6 0;
BA_REL_ "GenSigTimeoutTime" BU_SG_REL_ CGW_CCU SG_ 1806 AHV_SHVU_FR_GST_Byte7 0;
BA_REL_ "GenSigTimeoutTime" BU_SG_REL_ CGW_CCU SG_ 1806 AHV_SHVU_FR_GST_Byte1 0;
BA_REL_ "GenSigTimeoutTime" BU_SG_REL_ CGW_CCU SG_ 1807 RRHVU_GST_Byte0 0;
BA_REL_ "GenSigTimeoutTime" BU_SG_REL_ CGW_CCU SG_ 1807 RRHVU_GST_Byte2 0;
BA_REL_ "GenSigTimeoutTime" BU_SG_REL_ CGW_CCU SG_ 1807 RRHVU_GST_Byte3 0;
BA_REL_ "GenSigTimeoutTime" BU_SG_REL_ CGW_CCU SG_ 1807 RRHVU_GST_Byte4 0;
BA_REL_ "GenSigTimeoutTime" BU_SG_REL_ CGW_CCU SG_ 1807 RRHVU_GST_Byte5 0;
BA_REL_ "GenSigTimeoutTime" BU_SG_REL_ CGW_CCU SG_ 1807 RRHVU_GST_Byte6 0;
BA_REL_ "GenSigTimeoutTime" BU_SG_REL_ CGW_CCU SG_ 1807 RRHVU_GST_Byte7 0;
BA_REL_ "GenSigTimeoutTime" BU_SG_REL_ CGW_CCU SG_ 1807 RRHVU_GST_Byte1 0;
BA_REL_ "GenSigTimeoutTime" BU_SG_REL_ SHVU_FR SG_ 1798 GST_AHV_SHVU_FR_Byte0 0;
BA_REL_ "GenSigTimeoutTime" BU_SG_REL_ SHVU_FR SG_ 1798 GST_AHV_SHVU_FR_Byte2 0;
BA_REL_ "GenSigTimeoutTime" BU_SG_REL_ SHVU_FR SG_ 1798 GST_AHV_SHVU_FR_Byte3 0;
BA_REL_ "GenSigTimeoutTime" BU_SG_REL_ SHVU_FR SG_ 1798 GST_AHV_SHVU_FR_Byte4 0;
BA_REL_ "GenSigTimeoutTime" BU_SG_REL_ SHVU_FR SG_ 1798 GST_AHV_SHVU_FR_Byte5 0;
BA_REL_ "GenSigTimeoutTime" BU_SG_REL_ SHVU_FR SG_ 1798 GST_AHV_SHVU_FR_Byte6 0;
BA_REL_ "GenSigTimeoutTime" BU_SG_REL_ SHVU_FR SG_ 1798 GST_AHV_SHVU_FR_Byte7 0;
BA_REL_ "GenSigTimeoutTime" BU_SG_REL_ SHVU_FR SG_ 1798 GST_AHV_SHVU_FR_Byte1 0;
BA_REL_ "GenSigTimeoutTime" BU_SG_REL_ RRHV SG_ 1799 GST_RRHVU_Byte0 0;
BA_REL_ "GenSigTimeoutTime" BU_SG_REL_ SHVU_RR SG_ 1799 GST_RRHVU_Byte0 0;
BA_REL_ "GenSigTimeoutTime" BU_SG_REL_ RRHV SG_ 1799 GST_RRHVU_Byte2 0;
BA_REL_ "GenSigTimeoutTime" BU_SG_REL_ SHVU_RR SG_ 1799 GST_RRHVU_Byte2 0;
BA_REL_ "GenSigTimeoutTime" BU_SG_REL_ RRHV SG_ 1799 GST_RRHVU_Byte3 0;
BA_REL_ "GenSigTimeoutTime" BU_SG_REL_ SHVU_RR SG_ 1799 GST_RRHVU_Byte3 0;
BA_REL_ "GenSigTimeoutTime" BU_SG_REL_ RRHV SG_ 1799 GST_RRHVU_Byte4 0;
BA_REL_ "GenSigTimeoutTime" BU_SG_REL_ SHVU_RR SG_ 1799 GST_RRHVU_Byte4 0;
BA_REL_ "GenSigTimeoutTime" BU_SG_REL_ RRHV SG_ 1799 GST_RRHVU_Byte5 0;
BA_REL_ "GenSigTimeoutTime" BU_SG_REL_ SHVU_RR SG_ 1799 GST_RRHVU_Byte5 0;
BA_REL_ "GenSigTimeoutTime" BU_SG_REL_ RRHV SG_ 1799 GST_RRHVU_Byte6 0;
BA_REL_ "GenSigTimeoutTime" BU_SG_REL_ SHVU_RR SG_ 1799 GST_RRHVU_Byte6 0;
BA_REL_ "GenSigTimeoutTime" BU_SG_REL_ RRHV SG_ 1799 GST_RRHVU_Byte7 0;
BA_REL_ "GenSigTimeoutTime" BU_SG_REL_ SHVU_RR SG_ 1799 GST_RRHVU_Byte7 0;
BA_REL_ "GenSigTimeoutTime" BU_SG_REL_ RRHV SG_ 1799 GST_RRHVU_Byte1 0;
BA_REL_ "GenSigTimeoutTime" BU_SG_REL_ SHVU_RR SG_ 1799 GST_RRHVU_Byte1 0;
BA_REL_ "GenSigTimeoutTime" BU_SG_REL_ GW_RRPSU SG_ 2032 GST_RRMSU_MSU_RR_Byte0 0;
BA_REL_ "GenSigTimeoutTime" BU_SG_REL_ GW_RRPSU SG_ 2032 GST_RRMSU_MSU_RR_Byte2 0;
BA_REL_ "GenSigTimeoutTime" BU_SG_REL_ GW_RRPSU SG_ 2032 GST_RRMSU_MSU_RR_Byte3 0;
BA_REL_ "GenSigTimeoutTime" BU_SG_REL_ GW_RRPSU SG_ 2032 GST_RRMSU_MSU_RR_Byte4 0;
BA_REL_ "GenSigTimeoutTime" BU_SG_REL_ GW_RRPSU SG_ 2032 GST_RRMSU_MSU_RR_Byte5 0;
BA_REL_ "GenSigTimeoutTime" BU_SG_REL_ GW_RRPSU SG_ 2032 GST_RRMSU_MSU_RR_Byte6 0;
BA_REL_ "GenSigTimeoutTime" BU_SG_REL_ GW_RRPSU SG_ 2032 GST_RRMSU_MSU_RR_Byte7 0;
BA_REL_ "GenSigTimeoutTime" BU_SG_REL_ GW_RRPSU SG_ 2032 GST_RRMSU_MSU_RR_Byte1 0;
BA_REL_ "GenSigTimeoutTime" BU_SG_REL_ CGW_CCU SG_ 952 BLTN_CAM_Set_FR_Ver_Pos 1500;
BA_REL_ "GenSigTimeoutTime" BU_SG_REL_ CGW_CCU SG_ 952 BLTN_CAM_Set_PEV_AppNoti 1500;
BA_REL_ "GenSigTimeoutTime" BU_SG_REL_ CGW_CCU SG_ 952 BLTN_CAM_Set_WiFi_AutoOn 1500;
BA_REL_ "GenSigTimeoutTime" BU_SG_REL_ CGW_CCU SG_ 952 BLTN_CAM_StrgPropSet 1500;
BA_REL_ "GenSigTimeoutTime" BU_SG_REL_ CGW_CCU SG_ 952 BLTN_CAM_File_DEL_CPY_Op_State 1500;
BA_REL_ "GenSigTimeoutTime" BU_SG_REL_ CGW_CCU SG_ 952 BLTN_CAM_File_DEL_CPY_NumTot 1500;
BA_REL_ "GenSigTimeoutTime" BU_SG_REL_ CGW_CCU SG_ 952 BLTN_CAM_File_DEL_CPYed_Num 1500;
BA_REL_ "GenSigTimeoutTime" BU_SG_REL_ CGW_CCU SG_ 952 BLTN_CAM_Set_RR_Ver_Pos 1500;
BA_REL_ "GenSigTimeoutTime" BU_SG_REL_ CGW_CCU SG_ 2040 RRMSU_MSU_RR_GST_Byte0 0;
BA_REL_ "GenSigTimeoutTime" BU_SG_REL_ CGW_CCU SG_ 2040 RRMSU_MSU_RR_GST_Byte2 0;
BA_REL_ "GenSigTimeoutTime" BU_SG_REL_ CGW_CCU SG_ 2040 RRMSU_MSU_RR_GST_Byte3 0;
BA_REL_ "GenSigTimeoutTime" BU_SG_REL_ CGW_CCU SG_ 2040 RRMSU_MSU_RR_GST_Byte4 0;
BA_REL_ "GenSigTimeoutTime" BU_SG_REL_ CGW_CCU SG_ 2040 RRMSU_MSU_RR_GST_Byte5 0;
BA_REL_ "GenSigTimeoutTime" BU_SG_REL_ CGW_CCU SG_ 2040 RRMSU_MSU_RR_GST_Byte6 0;
BA_REL_ "GenSigTimeoutTime" BU_SG_REL_ CGW_CCU SG_ 2040 RRMSU_MSU_RR_GST_Byte7 0;
BA_REL_ "GenSigTimeoutTime" BU_SG_REL_ CGW_CCU SG_ 2040 RRMSU_MSU_RR_GST_Byte1 0;
BA_REL_ "GenSigTimeoutTime" BU_SG_REL_ CGW_CCU SG_ 950 BLTN_CAM_State 1500;
BA_REL_ "GenSigTimeoutTime" BU_SG_REL_ CGW_CCU SG_ 950 BLTN_CAM_RecSta_DEV 1500;
BA_REL_ "GenSigTimeoutTime" BU_SG_REL_ CGW_CCU SG_ 950 BLTN_CAM_RecSta_MAR 1500;
BA_REL_ "GenSigTimeoutTime" BU_SG_REL_ CGW_CCU SG_ 950 BLTN_CAM_RecSta_TML 1500;
BA_REL_ "GenSigTimeoutTime" BU_SG_REL_ CGW_CCU SG_ 950 BLTN_CAM_RecSta_OWP 1500;
BA_REL_ "GenSigTimeoutTime" BU_SG_REL_ CGW_CCU SG_ 950 BLTN_CAM_RecSta_PEV 1500;
BA_REL_ "GenSigTimeoutTime" BU_SG_REL_ CGW_CCU SG_ 950 BLTN_CAM_Prk_EV_Cnt 1500;
BA_REL_ "GenSigTimeoutTime" BU_SG_REL_ CGW_CCU SG_ 950 BLTN_CAM_Prk_Oped_Time 1500;
BA_REL_ "GenSigTimeoutTime" BU_SG_REL_ CGW_CCU SG_ 950 BLTN_CAM_Prk_Oprable_Time 1500;
BA_REL_ "GenSigTimeoutTime" BU_SG_REL_ CGW_CCU SG_ 950 BLTN_CAM_SD_Card_State 1500;
BA_REL_ "GenSigTimeoutTime" BU_SG_REL_ CGW_CCU SG_ 950 BLTN_CAM_Prk_Oprable_Time_Max 1500;
BA_REL_ "GenSigTimeoutTime" BU_SG_REL_ CGW_CCU SG_ 950 BLTN_CAM_AuxBat_Conn_State 1500;
BA_REL_ "GenSigTimeoutTime" BU_SG_REL_ CGW_CCU SG_ 950 BLTN_CAM_AuxBat_CapPer 1500;
BA_REL_ "GenSigTimeoutTime" BU_SG_REL_ CGW_CCU SG_ 950 BLTN_CAM_RecSta_OWD 1500;
BA_REL_ "GenSigTimeoutTime" BU_SG_REL_ CGW_CCU SG_ 951 BLTN_CAM_RecSet_OWD 1500;
BA_REL_ "GenSigTimeoutTime" BU_SG_REL_ CGW_CCU SG_ 951 BLTN_CAM_Set_Tim_Stm 1500;
BA_REL_ "GenSigTimeoutTime" BU_SG_REL_ CGW_CCU SG_ 951 BLTN_CAM_Set_Spd_Stm 1500;
BA_REL_ "GenSigTimeoutTime" BU_SG_REL_ CGW_CCU SG_ 951 BLTN_CAM_Set_Locatn_Stm 1500;
BA_REL_ "GenSigTimeoutTime" BU_SG_REL_ CGW_CCU SG_ 951 BLTN_CAM_Set_TrnSig_Stm 1500;
BA_REL_ "GenSigTimeoutTime" BU_SG_REL_ CGW_CCU SG_ 951 BLTN_CAM_Set_AclBrk_Stm 1500;
BA_REL_ "GenSigTimeoutTime" BU_SG_REL_ CGW_CCU SG_ 951 BLTN_CAM_RecSet_DEV 1500;
BA_REL_ "GenSigTimeoutTime" BU_SG_REL_ CGW_CCU SG_ 951 BLTN_CAM_Set_GearPos_Stm 1500;
BA_REL_ "GenSigTimeoutTime" BU_SG_REL_ CGW_CCU SG_ 951 BLTN_CAM_Set_EVSen_Stm 1500;
BA_REL_ "GenSigTimeoutTime" BU_SG_REL_ CGW_CCU SG_ 951 BLTN_CAM_Set_StrAngl_Stm 1500;
BA_REL_ "GenSigTimeoutTime" BU_SG_REL_ CGW_CCU SG_ 951 BLTN_CAM_Set_EV_RecMaxTime 1500;
BA_REL_ "GenSigTimeoutTime" BU_SG_REL_ CGW_CCU SG_ 951 BLTN_CAM_Set_PrkTime 1500;
BA_REL_ "GenSigTimeoutTime" BU_SG_REL_ CGW_CCU SG_ 951 BLTN_CAM_Set_EV_BfrTime 1500;
BA_REL_ "GenSigTimeoutTime" BU_SG_REL_ CGW_CCU SG_ 951 BLTN_CAM_RecSet_OWP 1500;
BA_REL_ "GenSigTimeoutTime" BU_SG_REL_ CGW_CCU SG_ 951 BLTN_CAM_Set_EV_AftTime 1500;
BA_REL_ "GenSigTimeoutTime" BU_SG_REL_ CGW_CCU SG_ 951 BLTN_CAM_Set_Drv_TML_Int 1500;
BA_REL_ "GenSigTimeoutTime" BU_SG_REL_ CGW_CCU SG_ 951 BLTN_CAM_SenSet_DEV 1500;
BA_REL_ "GenSigTimeoutTime" BU_SG_REL_ CGW_CCU SG_ 951 BLTN_CAM_SenSet_PEV 1500;
BA_REL_ "GenSigTimeoutTime" BU_SG_REL_ CGW_CCU SG_ 951 BLTN_CAM_RecSet_PEV 1500;
BA_REL_ "GenSigTimeoutTime" BU_SG_REL_ CGW_CCU SG_ 951 BLTN_CAM_AudRec_Set 1500;
BA_REL_ "GenSigTimeoutTime" BU_SG_REL_ OHCL SG_ 2281835009 ACU_Crc1Val 1500;
BA_REL_ "GenSigTimeoutTime" BU_SG_REL_ OHCL SG_ 2281835009 ACU_AlvCnt1Val 1500;
BA_REL_ "GenSigTimeoutTime" BU_SG_REL_ OHCL SG_ 2281835009 ACU_TlltlLmpDis 1500;
BA_REL_ "GenSigTimeoutTime" BU_SG_REL_ PSB SG_ 2281835009 SeatBelt_PassBcklFltSta 1500;
BA_REL_ "GenSigTimeoutTime" BU_SG_REL_ PSB SG_ 2281835009 SeatBelt_DrvrBcklFltSta 1500;
BA_REL_ "GenSigTimeoutTime" BU_SG_REL_ ATS SG_ 2281835009 SeatBelt_PassBcklSta 1500;
BA_REL_ "GenSigTimeoutTime" BU_SG_REL_ GW_APSU SG_ 2281835009 SeatBelt_PassBcklSta 1500;
BA_REL_ "GenSigTimeoutTime" BU_SG_REL_ GW_RLPSU SG_ 2281835009 SeatBelt_PassBcklSta 1500;
BA_REL_ "GenSigTimeoutTime" BU_SG_REL_ GW_RRPSU SG_ 2281835009 SeatBelt_PassBcklSta 1500;
BA_REL_ "GenSigTimeoutTime" BU_SG_REL_ PSB SG_ 2281835009 SeatBelt_PassBcklSta 1500;
BA_REL_ "GenSigTimeoutTime" BU_SG_REL_ PSB SG_ 2281835009 SeatBelt_DrvrBcklSta 1500;
BA_REL_ "GenSigTimeoutTime" BU_SG_REL_ EMCU SG_ 2353205505 CDCU_Rd_LongGrdntPerc 1500;
BA_REL_ "GenSigTimeoutTime" BU_SG_REL_ EMCU SG_ 2353205505 CDCU_Rd_LatGrdntPerc 1500;
BA_REL_ "GenSigTimeoutTime" BU_SG_REL_ ATS SG_ 942 AMP_Beep1VolumeStep 0;
BA_REL_ "GenSigTimeoutTime" BU_SG_REL_ CGW_CCU SG_ 939 PSB_Crc1Val 1500;
BA_REL_ "GenSigTimeoutTime" BU_SG_REL_ CGW_CCU SG_ 939 PSB_AlvCnt1Val 1500;
BA_REL_ "GenSigTimeoutTime" BU_SG_REL_ CGW_CCU SG_ 939 PSB_LHFlrSta 1500;
BA_REL_ "GenSigTimeoutTime" BU_SG_REL_ CGW_CCU SG_ 939 PSB_LHActvSta 1500;
BA_REL_ "GenSigTimeoutTime" BU_SG_REL_ CGW_CCU SG_ 939 PSB_RHFlrSta 1500;
BA_REL_ "GenSigTimeoutTime" BU_SG_REL_ CGW_CCU SG_ 939 PSB_RHActvSta 1500;
BA_REL_ "GenSigTimeoutTime" BU_SG_REL_ GW_APSU SG_ 939 PSB_RHActvSta 1500;
BA_REL_ "GenSigTimeoutTime" BU_SG_REL_ CGW_CCU SG_ 939 PSB_ActForAcu 1500;
BA_REL_ "GenSigTimeoutTime" BU_SG_REL_ CGW_CCU SG_ 939 PSB_HapticWarnSta 1500;
BA_REL_ "GenSigTimeoutTime" BU_SG_REL_ GW_APSU SG_ 939 PSB_RHActForPss 1500;
BA_REL_ "GenSigTimeoutTime" BU_SG_REL_ GW_RLPSU SG_ 939 PSB_RHActForPss 1500;
BA_REL_ "GenSigTimeoutTime" BU_SG_REL_ GW_RRPSU SG_ 939 PSB_RHActForPss 1500;
BA_REL_ "GenSigTimeoutTime" BU_SG_REL_ CGW_CCU SG_ 939 PSB_HDPSpprtSWVer 1500;
BA_REL_ "GenSigTimeoutTime" BU_SG_REL_ GW_RLPSU SG_ 939 PSB_LHActForPss 1500;
BA_REL_ "GenSigTimeoutTime" BU_SG_REL_ GW_RRPSU SG_ 939 PSB_LHActForPss 1500;
BA_REL_ "GenSigTimeoutTime" BU_SG_REL_ CGW_CCU SG_ 935 SCM_AnySwOnEv 0;
VAL_ 894 PDCex_Crc1Val 0 "0x0x0~0xFF:CRCValue" 255 "0x0x0~0xFF:CRCValue" ;
VAL_ 894 PDCex_4thRLSBRMatSw 0 "Off (UnSeated)" 1 "On (Seated)" ;
VAL_ 894 PDCex_4thRRSBRMatSw 0 "Off (UnSeated)" 1 "On (Seated)" ;
VAL_ 894 PDCex_AlvCnt1Val 0 "AlvCntValue" 1 "AlvCntValue" 2 "AlvCntValue" 3 "AlvCntValue" 4 "AlvCntValue" 5 "AlvCntValue" 6 "AlvCntValue" 7 "AlvCntValue" 8 "AlvCntValue" 9 "AlvCntValue" 10 "AlvCntValue" 11 "AlvCntValue" 12 "AlvCntValue" 13 "AlvCntValue" 14 "AlvCntValue" 15 "AlvCntValue" ;
VAL_ 894 PDCex_4thRLSeatBeltSW 0 "Unbelted" 1 "Belted" ;
VAL_ 894 PDCex_4thRCSeatBeltSW 0 "Unbelted" 1 "Belted" ;
VAL_ 894 PDCex_4thRRSeatBeltSW 0 "Unbelted" 1 "Belted" ;
VAL_ 894 PDCex_WirelessSBRWrngSta 0 "Default" 1 "Error State" 2 "RESERVED" 3 "RESERVED" ;
VAL_ 894 PDCex_FrtSunroofOpnSta 0 "Close" 1 "Open" 2 "Not Used" 3 "Error Indicator" ;
VAL_ 894 PDCex_RrSunroofOpnSta 0 "Close" 1 "Open" 2 "Not Used" 3 "Error Indicator" ;
VAL_ 894 PDCex_FuelDrOpenSta 0 "Close" 1 "Open" ;
VAL_ 894 PDCex_TlgtUnLkSta 0 "Lock" 1 "Unlock" 2 "Not Used" 3 "Error Indicator" ;
VAL_ 894 PDCex_PSDPwrModeOffSwSta 0 "Off" 1 "On" 2 "Not Used" 3 "Error Indicator" ;
VAL_ 894 PDCex_StrBoxLidSta 0 "Close" 1 "Open" 2 "Not Used" 3 "Error Indicator" ;
VAL_ 894 PDCex_StrBoxOutReleaseSwSta 0 "Off" 1 "On" 2 "Not Used" 3 "Error Indicator" ;
VAL_ 894 PDCex_DoorLock_LkOutSta 0 "Off" 1 "On" 2 "Not Used" 3 "Error Indicator" ;
VAL_ 894 SeatBeltSwSta_4thLft 0 "Unbelted" 1 "Belted" 2 "Not Supported" 3 "Virgin Mode" ;
VAL_ 894 SeatBeltSwSta_4thCtr 0 "Unbelted" 1 "Belted" 2 "Not Supported" 3 "Virgin Mode" ;
VAL_ 894 SeatBeltSwSta_4thRt 0 "Unbelted" 1 "Belted" 2 "Not Supported" 3 "Virgin Mode" ;
VAL_ 894 PDCex_OptTyp 0 "Default(No option)" 1 "MPV" 2 "Pickup" 3 "Curtain" ;
VAL_ 858 SBCM_AST_Crc2Val 0 "0x0x0~0xFF:CRCValue" 255 "0x0x0~0xFF:CRCValue" ;
VAL_ 858 AST_CrashUnlockCmd 0 "Off" 1 "Unlock (Crash)" ;
VAL_ 858 SBCM_AST_AlvCnt2Val 0 "AlvCntValue" 1 "AlvCntValue" 2 "AlvCntValue" 3 "AlvCntValue" 4 "AlvCntValue" 5 "AlvCntValue" 6 "AlvCntValue" 7 "AlvCntValue" 8 "AlvCntValue" 9 "AlvCntValue" 10 "AlvCntValue" 11 "AlvCntValue" 12 "AlvCntValue" 13 "AlvCntValue" 14 "AlvCntValue" 15 "AlvCntValue" ;
VAL_ 858 DoorLock_CtrlDrLkSwSta_SBCM 0 "Off" 1 "On (Lock On)" 2 "RESERVED" 3 "Error Indicator" ;
VAL_ 858 DoorLock_CtrlDrUnLkSwSta_SBCM 0 "Off" 1 "On (Unlock On)" 2 "RESERVED" 3 "Error Indicator" ;
VAL_ 858 Warn_AsstDrSwSta_SBCM 0 "Close" 1 "Open" 2 "RESERVED" 3 "Error Indicator" ;
VAL_ 858 DoorLock_AsstDrUnLkSta_SBCM 0 "Lock" 1 "Unlock" 2 "RESERVED" 3 "Error Indicator" ;
VAL_ 858 AST_SEAWarn_RH 0 "SEA Right Warning OFF" 1 "SEA Right Warning ON" 2 "RESERVED" 3 "RESERVED" ;
VAL_ 858 AST_SEAWarn_LH 0 "SEA Left Warning OFF" 1 "SEA Left Warning ON" 2 "RESERVED" 3 "RESERVED" ;
VAL_ 858 AST_SEWWarn_LH 0 "SEW Left Warning OFF" 1 "SEW Left Warning ON" 2 "RESERVED" 3 "RESERVED" ;
VAL_ 858 AST_SEWWarn_RH 0 "SEW Right Warning OFF" 1 "SEW Right Warning ON" 2 "RESERVED" 3 "RESERVED" ;
VAL_ 858 AST_MRActivationAlarm 0 "Off" 1 "On" 2 "RESERVED" 3 "Error Indicator" ;
VAL_ 858 AST_ReleaseWarn 0 "Release Warning OFF" 1 "Release Warning ON" 2 "RESERVED" 3 "RESERVED" ;
VAL_ 858 USM_AstGhostDoorSta 0 "Default" 1 "Off" 2 "On" 3 "RESERVED" ;
VAL_ 858 AST_SWFailAlarm 0 "Off" 1 "On" 2 "RESERVED" 3 "Error Indicator" ;
VAL_ 858 DoorLock_PDSLkSwSta_AST 0 "Lock" 1 "Unlock" 2 "RESERVED" 3 "Error Indicator" ;
VAL_ 858 PDS_TypeOption_AST 0 "Off" 1 "On" 2 "RESERVED" 3 "Error Indicator" ;
VAL_ 858 AFCU_AutoWashModeSta_SBCM_AST 0 "Default" 1 "AFCU Auto Wash Mode Off (Ready)" 2 "AFCU Auto Wash Mode Off (Error)" 3 "AFCU Auto Wash Mode On" 4 "RESERVED" 5 "RESERVED" 6 "RESERVED" 7 "Invalid" ;
VAL_ 858 CDM_AutoWashModeSta_SBCM_AST 0 "Default" 1 "CDM Auto Wash Mode Off (Ready)" 2 "CDM Auto Wash Mode Off (Error)" 3 "CDM Auto Wash Mode On" 4 "RESERVED" 5 "RESERVED" 6 "RESERVED" 7 "Invalid" ;
VAL_ 858 ASTDoorPushAlarm 0 "Off" 1 "On" 2 "RESERVED" 3 "Error Indicator" ;
VAL_ 863 Ast_SHVU_DTCdisplay 0 "DTC is not exist(Fail is not exist)" 1 "IGN2 Fuse Open Detection" 2 "Switch Input Detection at Same Time" 3 "NTC/Heating wire Open Detection" 4 "NTC+/NTC- Terminal Short Detection" 5 "NTC+/Heater+ Terminal Short Detection" 6 "NTC+/Heater-, Heater+/Heater-, Heater+/NTC- Terminal Short Detection" 7 "NTC+/Heater- Wiring Short Detection" 8 "NTC+/Heater-, Heater+/Heater-, Heater+/NTC- Wiring Short Detection" 9 "Target Temperature Dissatisfied" 10 "Blower+/Blower- Short, Blower+/Blower Speed, Blower-/Blower Speed Wiring Short Detection" 11 "Blower+/Blower RPM, Blower-/Blower RPM, Blower Speed/Blower RPM Short Detection" 12 "Blower+, Blower-, Blower Speed Signal open Detection" 13 "Blower RPM signal Open Detection" 14 "0x0E~0xFD:RESERVED" 253 "0x0E~0xFD:RESERVED" 254 "No Display" 255 "Invalid" ;
VAL_ 863 Ast_SHVU_DiagMode 0 "Default" 1 "DTC Mode" 2 "Normal Mode" 3 "Invalid" ;
VAL_ 862 SBCM_RL_Crc1Val 0 "0x0x0~0xFF:CRCValue" 255 "0x0x0~0xFF:CRCValue" ;
VAL_ 862 RL_CrashUnlockCmd 0 "Off" 1 "Unlock(Crash)" ;
VAL_ 862 SBCM_RL_AlvCnt1Val 0 "AlvCntValue" 1 "AlvCntValue" 2 "AlvCntValue" 3 "AlvCntValue" 4 "AlvCntValue" 5 "AlvCntValue" 6 "AlvCntValue" 7 "AlvCntValue" 8 "AlvCntValue" 9 "AlvCntValue" 10 "AlvCntValue" 11 "AlvCntValue" 12 "AlvCntValue" 13 "AlvCntValue" 14 "AlvCntValue" 15 "AlvCntValue" ;
VAL_ 862 Warn_RrLftDrSwSta_SBCM 0 "Close" 1 "Open" 2 "RESERVED" 3 "Error Indicator" ;
VAL_ 862 DoorLock_RrLftDrUnLkSta_SBCM 0 "Lock" 1 "Unlock" 2 "RESERVED" 3 "Error Indicator" ;
VAL_ 862 RL_SEAActivated 0 "InActivated" 1 "Activated" 2 "RESERVED" 3 "Error Indicator" ;
VAL_ 862 RL_SEAWarn 0 "SEA Left Warning OFF" 1 "SEA Left Warning ON" 2 "RESERVED" 3 "RESERVED" ;
VAL_ 862 RL_SEWWarn 0 "SEW Left Warning OFF" 1 "SEW Left Warning ON" 2 "RESERVED" 3 "RESERVED" ;
VAL_ 862 RL_ReleaseWarn 0 "Release Warning OFF" 1 "Release Warning ON" 2 "RESERVED" 3 "RESERVED" ;
VAL_ 862 RL_SWFailAlarm 0 "Off" 1 "On" 2 "RESERVED" 3 "Error Indicator" ;
VAL_ 862 RL_ChildLock_ActnFlSta 0 "OK" 1 "Failed" 2 "RESERVED" 3 "Error Indicator" ;
VAL_ 862 RL_MRActivationAlarm 0 "Off" 1 "On" 2 "RESERVED" 3 "Error Indicator" ;
VAL_ 862 RL_ChildLock_Status 0 "ChildLock On" 1 "ChildLock Off" 2 "RESERVED" 3 "RESERVED" ;
VAL_ 862 USM_RLGhostDoorSta 0 "Default" 1 "Off" 2 "On" 3 "RESERVED" ;
VAL_ 862 DoorLock_PDSLkSwSta_RL 0 "Lock" 1 "Unlock" 2 "RESERVED" 3 "Error Indicator" ;
VAL_ 862 PDS_TypeOption_RL 0 "Off" 1 "On" 2 "RESERVED" 3 "Error Indicator" ;
VAL_ 862 RLDoorPushAlarm 0 "Off" 1 "On" 2 "RESERVED" 3 "Error Indicator" ;
VAL_ 847 Drv_SHVU_DTCdisplay 0 "DTC is not exist(Fail is not exist)" 1 "IGN2 Fuse Open Detection" 2 "Switch Input Detection at Same Time" 3 "NTC/Heating wire Open Detection" 4 "NTC+/NTC- Terminal Short Detection" 5 "NTC+/Heater+ Terminal Short Detection" 6 "NTC+/Heater-, Heater+/Heater-, Heater+/NTC- Terminal Short Detection" 7 "NTC+/Heater- Wiring Short Detection" 8 "NTC+/Heater-, Heater+/Heater-, Heater+/NTC- Wiring Short Detection" 9 "Target Temperature Dissatisfied" 10 "Blower+/Blower- Short, Blower+/Blower Speed, Blower-/Blower Speed Wiring Short Detection" 11 "Blower+/Blower RPM, Blower-/Blower RPM, Blower Speed/Blower RPM Short Detection" 12 "Blower+, Blower-, Blower Speed Signal open Detection" 13 "Blower RPM signal Open Detection" 14 "0x0E~0xFD:RESERVED" 253 "0x0E~0xFD:RESERVED" 254 "No Display" 255 "Invalid" ;
VAL_ 847 Drv_SHVU_DiagMode 0 "Default" 1 "DTC Mode" 2 "Normal Mode" 3 "Invalid" ;
VAL_ 952 BLTN_CAM_Set_FR_Ver_Pos 0 "Mid" 1 "Upper Level (1 ~ 10)" 2 "Upper Level (1 ~ 10)" 3 "Upper Level (1 ~ 10)" 4 "Upper Level (1 ~ 10)" 5 "Upper Level (1 ~ 10)" 6 "Upper Level (1 ~ 10)" 7 "Upper Level (1 ~ 10)" 8 "Upper Level (1 ~ 10)" 9 "Upper Level (1 ~ 10)" 10 "Upper Level (1 ~ 10)" 11 "Reserved" 12 "Reserved" 13 "Reserved" 14 "Reserved" 15 "Reserved" 16 "Reserved" 17 "Lower Level (-1 ~ -10)" 18 "Lower Level (-1 ~ -10)" 19 "Lower Level (-1 ~ -10)" 20 "Lower Level (-1 ~ -10)" 21 "Lower Level (-1 ~ -10)" 22 "Lower Level (-1 ~ -10)" 23 "Lower Level (-1 ~ -10)" 24 "Lower Level (-1 ~ -10)" 25 "Lower Level (-1 ~ -10)" 26 "Lower Level (-1 ~ -10)" 27 "Reserved" 28 "Reserved" 29 "Reserved" 30 "Reserved" 31 "Invalid" ;
VAL_ 952 BLTN_CAM_Set_PEV_AppNoti 0 "Default" 1 "Off" 2 "On" 3 "Invalid" ;
VAL_ 952 BLTN_CAM_Set_WiFi_AutoOn 0 "Default" 1 "Off" 2 "On" 3 "Invalid" ;
VAL_ 952 BLTN_CAM_StrgPropSet 0 "Normal" 1 "On While Recordings" 2 "On While Parked" 3 "Driving Events" 4 "Parked Events" 5 "Reserved" 6 "Reserved" 7 "Reserved" 8 "Reserved" 9 "Reserved" 10 "Reserved" 11 "Reserved" 12 "Reserved" 13 "Reserved" 14 "Reserved" 15 "Invalid" ;
VAL_ 952 BLTN_CAM_File_DEL_CPY_Op_State 0 "Default" 1 "On Deleting" 2 "On Copying" 3 "operation completed" 4 "pausing the operation" 5 "operation canceled" 6 "Reserved" 7 "Reserved" 8 "Reserved" 9 "Reserved" 10 "Delete Error, No file(s)" 11 "Copy Error, No file(s)" 12 "Copy Error, Not enough target stroage space." 13 "The space not existed(not mounted)" 14 "the commend file is wrong." 15 "Invalid" ;
VAL_ 952 BLTN_CAM_File_DEL_CPY_NumTot 0 "Default" 1 "0x001~0xFFFB:Number of files" 65531 "0x001~0xFFFB:Number of files" 65532 "not operated" 65533 "The space not existed(not mounted)" 65534 "Not enough space" 65535 "Invalid" ;
VAL_ 952 BLTN_CAM_File_DEL_CPYed_Num 0 "Default" 1 "0x001~0xFFFB:Number of files" 65531 "0x001~0xFFFB:Number of files" 65532 "not operated" 65533 "The space not existed(not mounted)" 65534 "Not enough space" 65535 "Invalid" ;
VAL_ 952 BLTN_CAM_Set_RR_Ver_Pos 0 "Mid" 1 "Upper Level (1 ~ 10)" 2 "Upper Level (1 ~ 10)" 3 "Upper Level (1 ~ 10)" 4 "Upper Level (1 ~ 10)" 5 "Upper Level (1 ~ 10)" 6 "Upper Level (1 ~ 10)" 7 "Upper Level (1 ~ 10)" 8 "Upper Level (1 ~ 10)" 9 "Upper Level (1 ~ 10)" 10 "Upper Level (1 ~ 10)" 11 "Reserved" 12 "Reserved" 13 "Reserved" 14 "Reserved" 15 "Reserved" 16 "Reserved" 17 "Lower Level (-1 ~ -10)" 18 "Lower Level (-1 ~ -10)" 19 "Lower Level (-1 ~ -10)" 20 "Lower Level (-1 ~ -10)" 21 "Lower Level (-1 ~ -10)" 22 "Lower Level (-1 ~ -10)" 23 "Lower Level (-1 ~ -10)" 24 "Lower Level (-1 ~ -10)" 25 "Lower Level (-1 ~ -10)" 26 "Lower Level (-1 ~ -10)" 27 "Reserved" 28 "Reserved" 29 "Reserved" 30 "Reserved" 31 "Invalid" ;
VAL_ 950 BLTN_CAM_State 0 "BLTN_CAM Valid" 1 "BLTN_CAM Front Camera Invalid" 2 "BLTN_CAM Rear Camera Invalid" 3 "BLTN_CAM Front/Rear Camera Inavlid" 4 "BLTN_CAM Record Invalid" 5 "Reserved" 6 "Reserved" 7 "Reserved" 8 "Reserved" 9 "Reserved" 10 "Reserved" 11 "Reserved" 12 "Reserved" 13 "Reserved" 14 "Reserved" 15 "Invalid" ;
VAL_ 950 BLTN_CAM_RecSta_DEV 0 "Off" 1 "Recording" 2 "Reserved" 3 "invalid" ;
VAL_ 950 BLTN_CAM_RecSta_MAR 0 "Off" 1 "Recording" 2 "Reserved" 3 "invalid" ;
VAL_ 950 BLTN_CAM_RecSta_TML 0 "Off" 1 "Recording" 2 "Reserved" 3 "invalid" ;
VAL_ 950 BLTN_CAM_RecSta_OWP 0 "Off" 1 "Recording" 2 "Reserved" 3 "invalid" ;
VAL_ 950 BLTN_CAM_RecSta_PEV 0 "Off" 1 "Recording" 2 "Reserved" 3 "invalid" ;
VAL_ 950 BLTN_CAM_Prk_EV_Cnt 0 "0x0x0~0xC8:the number of the Park Event Record(0~200)" 200 "0x0x0~0xC8:the number of the Park Event Record(0~200)" 201 "Reserved" 202 "Reserved" 203 "Reserved" 204 "Reserved" 205 "Reserved" 206 "Reserved" 207 "Reserved" 208 "Reserved" 209 "Reserved" 210 "Reserved" 211 "Reserved" 212 "Reserved" 213 "Reserved" 214 "Reserved" 215 "Reserved" 216 "Reserved" 217 "Reserved" 218 "Reserved" 219 "Reserved" 220 "Reserved" 221 "Reserved" 222 "Reserved" 223 "Reserved" 224 "Reserved" 225 "Reserved" 226 "Reserved" 227 "Reserved" 228 "Reserved" 229 "Reserved" 230 "Reserved" 231 "Reserved" 232 "Reserved" 233 "Reserved" 234 "Reserved" 235 "Reserved" 236 "Reserved" 237 "Reserved" 238 "Reserved" 239 "Reserved" 240 "Reserved" 241 "Reserved" 242 "Reserved" 243 "Reserved" 244 "Reserved" 245 "Reserved" 246 "Reserved" 247 "Reserved" 248 "Reserved" 249 "Reserved" 250 "Reserved" 251 "Reserved" 252 "Over than 200 count" 253 "Park Mode was not Excuted" 254 "Park Mode was not Supported" 255 "invalid" ;
VAL_ 950 BLTN_CAM_Prk_Oped_Time 0 "Park Mode was not Excuted" 1 "0x1~0xFB:the hours of Park Mode Operated" 251 "0x1~0xFB:the hours of Park Mode Operated" 252 "RESERVED" 253 "RESERVED" 254 "RESERVED" 255 "invalid" ;
VAL_ 950 BLTN_CAM_Prk_Oprable_Time 0 "0x0x0~0xFB:the hours of Park Mode Operatable" 251 "0x0x0~0xFB:the hours of Park Mode Operatable" 252 "Motion Detection Record Mode" 253 "Auxiliary Battery is not connected. - Auxiliary Battery applicable on this vehicle model" 254 "Aux. Bat. is not connected. ? Aux. Bat. not applicable  or Not provide Park Mode Operation" 255 "Invalid" ;
VAL_ 950 BLTN_CAM_SD_Card_State 0 "Good, SD card is OK.(Green State)" 1 "SD card replacement recommend.(Yallow State)" 2 "SD card replacement required.(Red State)" 3 "SD card unrecognizable or No SD card found." 4 "SD card total capacity spec less than 64GByte (Built-in Cam Support 64GByte or higher)" 5 "SD card file system is not for Built-in Cam(Built-in CAM only support exFAT filesystem)" 6 "SD card not enough free space, need more free space for built-in Cam(less than 32GByte, must be 32GB" 7 "SD card recognized but Health State is not available (Gray State)" 8 "SD card Unmounted" 9 "RESERVED" 10 "RESERVED" 11 "RESERVED" 12 "RESERVED" 13 "RESERVED" 14 "RESERVED" 15 "Invalid(Red State)" ;
VAL_ 950 BLTN_CAM_Prk_Oprable_Time_Max 0 "0x0x0~0xFB:the hours of Park Mode Operatable" 251 "0x0x0~0xFB:the hours of Park Mode Operatable" 252 "RESERVED" 253 "Auxiliary Battery is not connected. - Auxiliary Battery applicable on this vehicle model" 254 "Aux. Bat. is not connected. ? Aux. Bat. not applicable  or Not provide Park Mode Operation" 255 "Invalid" ;
VAL_ 950 BLTN_CAM_AuxBat_Conn_State 0 "Default" 1 "Park Mode Operation Available (Aux. Bat. is connected(P-LBM or B-LBM) or Low Voltage battery Use.)" 2 "Auxiliary Battery is not connected. - Auxiliary Battery applicable on this vehicle model" 3 "Aux. Bat. is not connected. ? Aux. Bat. not applicable  or Not provide Park Mode Operation" ;
VAL_ 950 BLTN_CAM_AuxBat_CapPer 0 "0x0x0~0x64: Aux Bat Capacity Percent(0~100%)" 100 "0x0x0~0x64: Aux Bat Capacity Percent(0~100%)" 100 "Reserved" 101 "Reserved" 102 "Reserved" 103 "Reserved" 104 "Reserved" 105 "Reserved" 106 "Reserved" 107 "Reserved" 108 "Reserved" 109 "Reserved" 110 "Reserved" 111 "Reserved" 112 "Reserved" 113 "Reserved" 114 "Reserved" 115 "Reserved" 116 "Reserved" 117 "Reserved" 118 "Reserved" 119 "Reserved" 120 "Reserved" 121 "Reserved" 122 "Reserved" 123 "Reserved" 124 "Reserved" 125 "Reserved" 126 "Reserved" 127 "Invalid" ;
VAL_ 950 BLTN_CAM_RecSta_OWD 0 "Off" 1 "Recording" 2 "Reserved" 3 "invalid" ;
VAL_ 951 BLTN_CAM_RecSet_OWD 0 "Default" 1 "Off" 2 "On" 3 "Invalid" ;
VAL_ 951 BLTN_CAM_Set_Tim_Stm 0 "Default" 1 "Off" 2 "On" 3 "Invalid" ;
VAL_ 951 BLTN_CAM_Set_Spd_Stm 0 "Default" 1 "Off" 2 "On" 3 "Invalid" ;
VAL_ 951 BLTN_CAM_Set_Locatn_Stm 0 "Default" 1 "Off" 2 "On" 3 "Invalid" ;
VAL_ 951 BLTN_CAM_Set_TrnSig_Stm 0 "Default" 1 "Off" 2 "On" 3 "Invalid" ;
VAL_ 951 BLTN_CAM_Set_AclBrk_Stm 0 "Default" 1 "Off" 2 "On" 3 "Invalid" ;
VAL_ 951 BLTN_CAM_RecSet_DEV 0 "Default" 1 "Off" 2 "On" 3 "Invalid" ;
VAL_ 951 BLTN_CAM_Set_GearPos_Stm 0 "Default" 1 "Off" 2 "On" 3 "Invalid" ;
VAL_ 951 BLTN_CAM_Set_EVSen_Stm 0 "Default" 1 "Off" 2 "On" 3 "Invalid" ;
VAL_ 951 BLTN_CAM_Set_StrAngl_Stm 0 "Default" 1 "Off" 2 "On" 3 "Invalid" ;
VAL_ 951 BLTN_CAM_Set_EV_RecMaxTime 0 "Default" 1 "Off" 2 "On" 3 "Default" ;
VAL_ 951 BLTN_CAM_Set_PrkTime 0 "Default" 1 "0x01~0xFB: 1~ 251 hr" 251 "0x01~0xFB: 1~ 251 hr" 252 "Motion Detection Record Mode" 253 "RESERVED" 254 "Not Supported" 255 "Invalid" ;
VAL_ 951 BLTN_CAM_Set_EV_BfrTime 0 "10~20 sec" 1 "10~20 sec" 2 "10~20 sec" 3 "10~20 sec" 4 "10~20 sec" 5 "10~20 sec" 6 "10~20 sec" 7 "10~20 sec" 8 "10~20 sec" 9 "10~20 sec" 10 "10~20 sec" 11 "Reserved" 12 "Reserved" 13 "Reserved" 14 "Reserved" 15 "Reserved" 16 "Reserved" 17 "Reserved" 18 "Reserved" 19 "Reserved" 20 "Reserved" 21 "Reserved" 22 "Reserved" 23 "Reserved" 24 "Reserved" 25 "Reserved" 26 "Reserved" 27 "Reserved" 28 "Reserved" 29 "Reserved" 30 "Reserved" 31 "Invalid" ;
VAL_ 951 BLTN_CAM_RecSet_OWP 0 "Default" 1 "Off" 2 "On" 3 "Invalid" ;
VAL_ 951 BLTN_CAM_Set_EV_AftTime 0 "10~20 sec" 1 "10~20 sec" 2 "10~20 sec" 3 "10~20 sec" 4 "10~20 sec" 5 "10~20 sec" 6 "10~20 sec" 7 "10~20 sec" 8 "10~20 sec" 9 "10~20 sec" 10 "10~20 sec" 11 "Reserved" 12 "Reserved" 13 "Reserved" 14 "Reserved" 15 "Reserved" 16 "Reserved" 17 "Reserved" 18 "Reserved" 19 "Reserved" 20 "Reserved" 21 "Reserved" 22 "Reserved" 23 "Reserved" 24 "Reserved" 25 "Reserved" 26 "Reserved" 27 "Reserved" 28 "Reserved" 29 "Reserved" 30 "Reserved" 31 "Invalid" ;
VAL_ 951 BLTN_CAM_Set_Drv_TML_Int 0 "Default" 1 "1~ 10 sec" 2 "1~ 10 sec" 3 "1~ 10 sec" 4 "1~ 10 sec" 5 "1~ 10 sec" 6 "1~ 10 sec" 7 "1~ 10 sec" 8 "1~ 10 sec" 9 "1~ 10 sec" 10 "1~ 10 sec" 11 "Reserved" 12 "Reserved" 13 "Reserved" 14 "Reserved" 15 "Invalid" ;
VAL_ 951 BLTN_CAM_SenSet_DEV 0 "Default" 1 "Level 1" 2 "Level 2" 3 "Level 3" 4 "Level 4" 5 "Level 5" 6 "Reserved" 7 "Reserved" 8 "Reserved" 9 "Reserved" 10 "Reserved" 11 "Reserved" 12 "Reserved" 13 "Reserved" 14 "Reserved" 15 "Invalid" ;
VAL_ 951 BLTN_CAM_SenSet_PEV 0 "Default" 1 "Level 1" 2 "Level 2" 3 "Level 3" 4 "Level 4" 5 "Level 5" 6 "Reserved" 7 "Reserved" 8 "Reserved" 9 "Reserved" 10 "Reserved" 11 "Reserved" 12 "Reserved" 13 "Reserved" 14 "Reserved" 15 "Invalid" ;
VAL_ 951 BLTN_CAM_RecSet_PEV 0 "Default" 1 "Off" 2 "On" 3 "Invalid" ;
VAL_ 951 BLTN_CAM_AudRec_Set 0 "Default" 1 "Off" 2 "On" 3 "Invalid" ;
VAL_ 2281835010 ACU_ActvFltSta 0 "Fault status is active" 1 "Fault status is historic" 2 "Fault does not exist" 3 "Reserved" 4 "Reserved" 5 "Reserved" 6 "Not used" 7 "Error Indicator" ;
VAL_ 2281835010 ACU_SdArbgExtTyp 0 "Side(or Side/Curtain) Airbag doesn't exist." 1 "Side(or Side/Curtain) Airbag exists." 2 "ACU EOL Programming Mode" 3 "Reserved" 4 "Reserved" 5 "Reserved" 6 "Not used" 7 "Error Indicator" ;
VAL_ 2281835010 ACU_PassArbg_SW_Sta 0 "NOT_APPLIED" 1 "PAB_OFF" 2 "PAB_ON" 3 "Invalid" ;
VAL_ 2281835010 ACU_HDPSpprtSWVer 0 "Not Support(init)" 1 "SW Version" 2 "SW Version" 3 "SW Version" 4 "SW Version" 5 "SW Version" 6 "SW Version" 7 "SW Version" 8 "SW Version" 9 "SW Version" 10 "SW Version" 11 "SW Version" 12 "SW Version" 13 "SW Version" 14 "SW Version" 15 "SW Version" 16 "SW Version" 17 "SW Version" 18 "SW Version" 19 "SW Version" 20 "SW Version" 21 "SW Version" ;
VAL_ 2281835010 Reprogram_State_ACU 0 "Normal Operation" 1 "Reprogramming" 2 "RESERVED" 3 "Error Indicator" ;
VAL_ 2281835010 ACU_EmerModSta 0 "ACU is NOT Emergency mode" 1 "ACU is Emergency mode" ;
VAL_ 2281835010 ACU_EvtTrigSta 0 "EDR Not triggered." 1 "EDR triggered." ;
VAL_ 2281835009 ACU_Crc1Val 0 "0x0x0~0xFFFF:CRCValue" 65535 "0x0x0~0xFFFF:CRCValue" ;
VAL_ 2281835009 ACU_AlvCnt1Val 0 "0x0x0~0xFF:AlvCntValue" 255 "0x0x0~0xFF:AlvCntValue" ;
VAL_ 2281835009 ACU_SysWrngLmpDis 0 "Warning Lamp off" 1 "Warning Lamp on" 2 "Warning Lamp flash" 3 "Reserved" 4 "Reserved" 5 "Reserved" 6 "Not used" 7 "Error Indicator" ;
VAL_ 2281835009 ACU_TlltlLmpDis 0 "ON Lamp off OFF Lamp off" 1 "ON Lamp off  OFF Lamp on" 2 "ON Lamp on OFF Lamp off" 3 "ON Lamp on OFF Lamp on" 4 "Reserved" 5 "Reserved" 6 "Reserved" 7 "Error Indicator" ;
VAL_ 2281835009 ACU_OdsIDReq 0 "Request to send ODS Identifier" 1 "Acknowledgement for the Correct ODS Identifier Received" 2 "Not used" 3 "Error Indicator" ;
VAL_ 2281835009 SeatBelt_PassBcklFltSta 0 "No Fault" 1 "Fault condition exists" 2 "Not used" 3 "Error Indicator" ;
VAL_ 2281835009 SeatBelt_DrvrBcklFltSta 0 "No Fault" 1 "Fault condition exists" 2 "Not used" 3 "Error Indicator" ;
VAL_ 2281835009 SeatBelt_PassBcklSta 0 "Passenger Seat Belt Not Latched" 1 "Passenger Seat Belt Latched" 2 "Not used" 3 "Error Indicator" ;
VAL_ 2281835009 SeatBelt_DrvrBcklSta 0 "Driver Seat Belt Not Latched" 1 "Driver Seat Belt Latched" 2 "Not used" 3 "Error Indicator" ;
VAL_ 2353205505 CDCU_Crc1Val 0 "0x0x0~0xFFFF:CRCValue" 65535 "0x0x0~0xFFFF:CRCValue" ;
VAL_ 2353205505 CDCU_AlvCnt1Val 0 "0x0x0~0xFF:AlvCntValue" 255 "0x0x0~0xFF:AlvCntValue" ;
VAL_ 2353205505 CDCU_Rd_LongGrdntPerc 28 "0x0x1C ~ 0xE4 : -100% ~ 100%0xFF : Invalid(Error Or Not Applied)" 228 "0x0x1C ~ 0xE4 : -100% ~ 100%0xFF : Invalid(Error Or Not Applied)" ;
VAL_ 2353205505 CDCU_Rd_LatGrdntPerc 28 "0x0x1C ~ 0xE4 : -100% ~ 100%0xFF : Invalid(Error Or Not Applied)" 228 "0x0x1C ~ 0xE4 : -100% ~ 100%0xFF : Invalid(Error Or Not Applied)" ;
VAL_ 2353205505 CDCU_CPE_Sta 0 "Not request" 1 "request(PC)" 2 "request(Nm/bar)" 3 "Not available" 4 "Reserved" 5 "Reserved" 6 "Reserved" 7 "Reserved" 8 "Reserved" 9 "Reserved" 10 "Reserved" 11 "Reserved" 12 "Reserved" 13 "Reserved" 14 "Reserved" 15 "Invalid" ;
VAL_ 2353205505 CDCU_CPE_CpOffsetPC 255 "Error indicator" ;
VAL_ 2353205505 CDCU_CPE_CpOffset 255 "Error indicator" ;
VAL_ 2353205505 CDCU_BJDSta 0 "No Event" 1 "Event" ;
VAL_ 2353205505 CDCU_WrngLmpSta 0 "CDCU Warning lamp Off" 1 "CDCU Warning lamp On" 2 "RESERVED" 3 "RESERVED" ;
VAL_ 2164279809 IMU_Crc1Val 0 "0x0x0~0xFFFF:CRCValue" 65535 "0x0x0~0xFFFF:CRCValue" ;
VAL_ 2164279809 IMU_AlvCnt1Val 0 "0x0x0~0xFF:AlvCntValue" 255 "0x0x0~0xFF:AlvCntValue" ;
VAL_ 2353205506 CBCR_SocConsumptionReq 0 "Not Applied" 1 "Request OFF" 2 "Request ON" 3 "Error Identifier" ;
VAL_ 2353205506 CBCR_CluDispMsgSta 0 "None(Default)" 1 "Disp1" 2 "Disp2" 3 "Disp3" 4 "RESERVED" 5 "RESERVED" 6 "RESERVED" 7 "RESERVED" ;
VAL_ 942 AMP_Beep1VolumeStep 0 "0x0x0~0xFD:Beep1 Volume" 253 "0x0x0~0xFD:Beep1 Volume" 254 "Req.amp. Beep1 settings" 255 "Invalid" ;
VAL_ 942 AMP_Analog_OutputCh_Select 0 "0x0x0~0xFFFE:Valid" 65534 "0x0x0~0xFFFE:Valid" 65535 "Invalid" ;
VAL_ 942 AMP_Beep1_OutputCh_Select 0 "0x0x0~0xFFFE:Valid" 65534 "0x0x0~0xFFFE:Valid" 65535 "Invaild" ;
VAL_ 942 AMP_Beep1KBDVolumeStep 0 "0x0x0~0xFE:keyboard Beep Volume" 254 "0x0x0~0xFE:keyboard Beep Volume" 255 "Invalid" ;
VAL_ 942 AMP_SPDIF_OutputCh_Select 0 "0x0x0~0xFFFE:Valid" 65534 "0x0x0~0xFFFE:Valid" 65535 "Invaild" ;
VAL_ 939 PSB_Crc1Val 0 "0x0x0~0xFF:CRCValue" 255 "0x0x0~0xFF:CRCValue" ;
VAL_ 939 PSB_AlvCnt1Val 0 "AlvCntValue" 1 "AlvCntValue" 2 "AlvCntValue" 3 "AlvCntValue" 4 "AlvCntValue" 5 "AlvCntValue" 6 "AlvCntValue" 7 "AlvCntValue" 8 "AlvCntValue" 9 "AlvCntValue" 10 "AlvCntValue" 11 "AlvCntValue" 12 "AlvCntValue" 13 "AlvCntValue" 14 "AlvCntValue" 15 "AlvCntValue" ;
VAL_ 939 PSB_LHFlrSta 0 "No failure" 1 "Failure, Service Required" 2 "Defect, PSB warning light off" 3 "Signal not valid" ;
VAL_ 939 PSB_LHActvSta 0 "No PSB motor activation" 1 "PSB retract cycle active" 2 "Reserved" 3 "Reserved" ;
VAL_ 939 PSB_RHFlrSta 0 "No failure" 1 "Failure, Service Required" 2 "Defect, PSB warning light off" 3 "Signal not valid" ;
VAL_ 939 PSB_RHActvSta 0 "No PSB motor activation" 1 "PSB retract cycle active" 2 "Reserved" 3 "Reserved" ;
VAL_ 939 PSB_ActForAcu 0 "Inactive" 1 "Active" 2 "Reserved" 3 "Failure" ;
VAL_ 939 PSB_HapticWarnSta 0 "No PSB activation" 1 "PSB Haptic active-1st step" 2 "PSB Haptic active-2nd step" 3 "RESERVED" 4 "RESERVED" 5 "RESERVED" 6 "RESERVED" 7 "RESERVED" 8 "RESERVED" 9 "RESERVED" 10 "RESERVED" 11 "RESERVED" 12 "RESERVED" 13 "RESERVED" 14 "HDP Request Error" 15 "Invalid" ;
VAL_ 939 PSB_RHActForPss 0 "No PSB motor activation" 1 "PSB retract cycle active" 2 "Reserved" 3 "Reserved" ;
VAL_ 939 PSB_HDPSpprtSWVer 0 "Requirement Spec Version" 1 "Requirement Spec Version" 2 "Requirement Spec Version" 3 "Requirement Spec Version" 4 "Requirement Spec Version" 5 "Requirement Spec Version" 6 "Requirement Spec Version" 7 "Requirement Spec Version" 8 "Requirement Spec Version" 9 "Requirement Spec Version" 10 "Requirement Spec Version" 11 "Requirement Spec Version" 12 "Requirement Spec Version" 13 "Requirement Spec Version" 14 "Requirement Spec Version" 15 "Requirement Spec Version" 16 "Requirement Spec Version" 17 "Requirement Spec Version" 18 "Requirement Spec Version" 19 "Requirement Spec Version" 20 "Requirement Spec Version" 21 "Requirement Spec Version" 22 "Requirement Spec Version" 23 "Requirement Spec Version" 24 "Requirement Spec Version" 25 "Requirement Spec Version" 26 "Requirement Spec Version" 27 "Requirement Spec Version" 28 "Requirement Spec Version" 29 "Requirement Spec Version" 30 "Requirement Spec Version" 31 "Invalid" ;
VAL_ 939 PSB_LHActForPss 0 "No PSB motor activation" 1 "PSB retract cycle active" 2 "Reserved" 3 "Reserved" ;
VAL_ 935 SCM_AnySwOnEv 0 "Invalid" 1 "On" ;
VAL_ 2239851012 MRA_BtnDispSta 0 "Init (No Display)" 1 "MRA Path Button Display" 2 "Enabled MRA Start Button Display" 3 "Cancel MRA Button display" 4 "RESERVED" 5 "RESERVED" 6 "RESERVED" 7 "RESERVED" 8 "RESERVED" 9 "RESERVED" 10 "RESERVED" 11 "RESERVED" 12 "RESERVED" 13 "RESERVED" 14 "RESERVED" 15 "Invalid" ;
VAL_ 2239851012 RSPA_HdLmpReq 0 "Initial (Inactive)" 1 "HeadLamp On" 2 "Not Used" 3 "Error Indicator" ;
VAL_ 2239851012 RSPA_BtnDispSta 0 "Init" 1 "Check RSPA" 2 "Disable Button display" 3 "Enable Button display" 4 "RESERVED" 5 "RESERVED" 6 "RESERVED" 7 "Invalid" ;
VAL_ 2239851012 RSPA_OSMirFoldReq 0 "Off" 1 "OS Mirror Fold" 2 "OS Mirror Unfold" 3 "Invalid" ;
